VERSION "created by canmatrix"

NS_ :

BS_:

BU_: ARC ADC

BO_ 856 ARC_OD_14_15_RL: 64 ARC
 SG_ DistHeight_Obj_15_RL : 487|8@0+ (0.2,-10) [-10|41] "m" ADC
 SG_ DistHeight_Obj_14_RL : 479|8@0+ (0.2,-10) [-10|41] "m" ADC
 SG_ ARC_OD_DistX_Obj_14_RL : 7|12@0+ (0.1,-152) [-152|257.5] "m" ADC
 SG_ ARC_OD_Classification_Obj_14_RL : 98|3@0+ (1,0) [0|7] "" ADC
 SG_ ARC_OD_AabsYStd_Obj_14_RL : 111|8@0+ (0.25,0) [0|63.75] "m/s^2" ADC
 SG_ ARC_OD_ClassConf_Obj_14_RL : 119|7@0+ (1,0) [0|127] "%" ADC
 SG_ ARC_OD_ProbOfExist_Obj_14_RL : 112|7@0+ (1,0) [0|127] "%" ADC
 SG_ ARC_OD_VabsX_Obj_14_RL : 11|11@0+ (0.125,-128) [-128|127.875] "m/s" ADC
 SG_ ARC_OD_DynProp_Obj_14_RL : 130|3@0+ (1,0) [0|7] "" ADC
 SG_ ARC_OD_Length_Obj_14_RL : 136|7@0+ (0.2,0) [0|25.4] "m" ADC
 SG_ ARC_OD_MaintenanceState_Obj_0075 : 145|2@0+ (1,0) [0|3] "" ADC
 SG_ ARC_OD_Width_Obj_14_RL : 159|7@0+ (0.2,0) [0|25.4] "m" ADC
 SG_ ARC_OD_RCS_Obj_14_RL : 152|9@0+ (0.2,-51.1) [-51.1|51.1] "dBsm" ADC
 SG_ ARC_OD_Orientation_Obj_14_RL : 175|10@0+ (0.01,-5.11) [-5.11|5.12] "rad" ADC
 SG_ ARC_OD_LifeCycle_Obj_14_RL : 207|16@0+ (1,0) [0|65535] "" ADC
 SG_ ARC_OD_DistX_Obj_15_RL : 223|12@0+ (0.1,-152) [-152|257.5] "m" ADC
 SG_ ARC_OD_VabsX_Obj_15_RL : 227|11@0+ (0.125,-128) [-128|127.875] "m/s" ADC
 SG_ ARC_OD_AabsX_Obj_15_RL : 232|9@0+ (0.125,-31.875) [-31.875|32] "m/s^2" ADC
 SG_ ARC_OD_AabsX_Obj_14_RL : 16|9@0+ (0.125,-31.875) [-31.875|32] "m/s^2" ADC
 SG_ ARC_OD_DistY_Obj_15_RL : 255|12@0+ (0.0875,-179.113) [-179.113|179.2] "m" ADC
 SG_ ARC_OD_VabsY_Obj_15_RL : 259|11@0+ (0.125,-128) [-128|127.875] "m/s" ADC
 SG_ ARC_OD_AabsY_Obj_15_RL : 264|9@0+ (0.125,-31.875) [-31.875|32] "m/s^2" ADC
 SG_ ARC_OD_DistXStd_Obj_15_RL : 287|8@0+ (0.05,0) [0|12.75] "m" ADC
 SG_ ARC_OD_DistYStd_Obj_15_RL : 295|8@0+ (0.1,0) [0|25.5] "m" ADC
 SG_ ARC_OD_VabsXStd_Obj_15_RL : 303|7@0+ (0.1,0) [0|12.7] "m/s" ADC
 SG_ ARC_OD_VabsYStd_Obj_15_RL : 296|7@0+ (0.2,0) [0|25.4] "m/s" ADC
 SG_ ARC_OD_AabsXStd_Obj_15_RL : 305|7@0+ (0.25,0) [0|31.75] "m/s^2" ADC
 SG_ ARC_OD_Classification_Obj_15_RL : 314|3@0+ (1,0) [0|7] "" ADC
 SG_ ARC_OD_AabsYStd_Obj_15_RL : 327|8@0+ (0.25,0) [0|63.75] "m/s^2" ADC
 SG_ ARC_OD_ClassConf_Obj_15_RL : 335|7@0+ (1,0) [0|127] "%" ADC
 SG_ ARC_OD_DistY_Obj_14_RL : 39|12@0+ (0.0875,-179.113) [-179.113|179.2] "m" ADC
 SG_ ARC_OD_ProbOfExist_Obj_15_RL : 328|7@0+ (1,0) [0|127] "%" ADC
 SG_ ARC_OD_DynProp_Obj_15_RL : 346|3@0+ (1,0) [0|7] "" ADC
 SG_ ARC_OD_Length_Obj_15_RL : 352|7@0+ (0.2,0) [0|25.4] "m" ADC
 SG_ ARC_OD_MaintenanceState_Obj_0076 : 361|2@0+ (1,0) [0|3] "" ADC
 SG_ ARC_OD_Width_Obj_15_RL : 375|7@0+ (0.2,0) [0|25.4] "m" ADC
 SG_ ARC_OD_RCS_Obj_15_RL : 368|9@0+ (0.2,-51.1) [-51.1|51.1] "dBsm" ADC
 SG_ ARC_OD_Orientation_Obj_15_RL : 391|10@0+ (0.01,-5.11) [-5.11|5.12] "rad" ADC
 SG_ ARC_OD_LifeCycle_Obj_15_RL : 423|16@0+ (1,0) [0|65535] "" ADC
 SG_ ARC_OD_ObstacleProb_Obj_14_RL : 447|7@0+ (1,0) [0|127] "%" ADC
 SG_ ARC_OD_ObstacleProb_Obj_15_RL : 455|7@0+ (1,0) [0|127] "%" ADC
 SG_ ARC_OD_VabsY_Obj_14_RL : 43|11@0+ (0.125,-128) [-128|127.875] "m/s" ADC
 SG_ ARC_OD_ID_14_RL : 463|8@0+ (1,0) [0|255] "" ADC
 SG_ ARC_OD_ID_15_RL : 471|8@0+ (1,0) [0|255] "" ADC
 SG_ ARC_OD_MsgCounter_Obj_14_15_RL : 491|4@0+ (1,0) [0|15] "" ADC
 SG_ ARC_OD_CRC8_Obj_14_15_RL : 511|8@0+ (1,0) [0|256] "" ADC
 SG_ ARC_OD_AabsY_Obj_14_RL : 48|9@0+ (0.125,-31.875) [-31.875|32] "m/s^2" ADC
 SG_ ARC_OD_DistXStd_Obj_14_RL : 71|8@0+ (0.05,0) [0|12.75] "m" ADC
 SG_ ARC_OD_DistYStd_Obj_14_RL : 79|8@0+ (0.1,0) [0|25.5] "m" ADC
 SG_ ARC_OD_VabsXStd_Obj_14_RL : 87|7@0+ (0.1,0) [0|12.7] "m/s" ADC
 SG_ ARC_OD_VabsYStd_Obj_14_RL : 80|7@0+ (0.2,0) [0|25.4] "m/s" ADC
 SG_ ARC_OD_AabsXStd_Obj_14_RL : 89|7@0+ (0.25,0) [0|31.75] "m/s^2" ADC

BO_ 857 ARC_OD_16_17_RL: 64 ARC
 SG_ DistHeight_Obj_17_RL : 487|8@0+ (0.2,-10) [-10|41] "m" ADC
 SG_ DistHeight_Obj_16_RL : 479|8@0+ (0.2,-10) [-10|41] "m" ADC
 SG_ ARC_OD_DistX_Obj_16_RL : 7|12@0+ (0.1,-152) [-152|257.5] "m" ADC
 SG_ ARC_OD_Classification_Obj_16_RL : 98|3@0+ (1,0) [0|7] "" ADC
 SG_ ARC_OD_AabsYStd_Obj_16_RL : 111|8@0+ (0.25,0) [0|63.75] "m/s^2" ADC
 SG_ ARC_OD_ClassConf_Obj_16_RL : 119|7@0+ (1,0) [0|127] "%" ADC
 SG_ ARC_OD_ProbOfExist_Obj_16_RL : 112|7@0+ (1,0) [0|127] "%" ADC
 SG_ ARC_OD_VabsX_Obj_16_RL : 11|11@0+ (0.125,-128) [-128|127.875] "m/s" ADC
 SG_ ARC_OD_DynProp_Obj_16_RL : 130|3@0+ (1,0) [0|7] "" ADC
 SG_ ARC_OD_Length_Obj_16_RL : 136|7@0+ (0.2,0) [0|25.4] "m" ADC
 SG_ ARC_OD_MaintenanceState_Obj_0077 : 145|2@0+ (1,0) [0|3] "" ADC
 SG_ ARC_OD_Width_Obj_16_RL : 159|7@0+ (0.2,0) [0|25.4] "m" ADC
 SG_ ARC_OD_RCS_Obj_16_RL : 152|9@0+ (0.2,-51.1) [-51.1|51.1] "dBsm" ADC
 SG_ ARC_OD_Orientation_Obj_16_RL : 175|10@0+ (0.01,-5.11) [-5.11|5.12] "rad" ADC
 SG_ ARC_OD_LifeCycle_Obj_16_RL : 207|16@0+ (1,0) [0|65535] "" ADC
 SG_ ARC_OD_DistX_Obj_17_RL : 223|12@0+ (0.1,-152) [-152|257.5] "m" ADC
 SG_ ARC_OD_VabsX_Obj_17_RL : 227|11@0+ (0.125,-128) [-128|127.875] "m/s" ADC
 SG_ ARC_OD_AabsX_Obj_17_RL : 232|9@0+ (0.125,-31.875) [-31.875|32] "m/s^2" ADC
 SG_ ARC_OD_AabsX_Obj_16_RL : 16|9@0+ (0.125,-31.875) [-31.875|32] "m/s^2" ADC
 SG_ ARC_OD_DistY_Obj_17_RL : 255|12@0+ (0.0875,-179.113) [-179.113|179.2] "m" ADC
 SG_ ARC_OD_VabsY_Obj_17_RL : 259|11@0+ (0.125,-128) [-128|127.875] "m/s" ADC
 SG_ ARC_OD_AabsY_Obj_17_RL : 264|9@0+ (0.125,-31.875) [-31.875|32] "m/s^2" ADC
 SG_ ARC_OD_DistXStd_Obj_17_RL : 287|8@0+ (0.05,0) [0|12.75] "m" ADC
 SG_ ARC_OD_DistYStd_Obj_17_RL : 295|8@0+ (0.1,0) [0|25.5] "m" ADC
 SG_ ARC_OD_VabsXStd_Obj_17_RL : 303|7@0+ (0.1,0) [0|12.7] "m/s" ADC
 SG_ ARC_OD_VabsYStd_Obj_17_RL : 296|7@0+ (0.2,0) [0|25.4] "m/s" ADC
 SG_ ARC_OD_AabsXStd_Obj_17_RL : 305|7@0+ (0.25,0) [0|31.75] "m/s^2" ADC
 SG_ ARC_OD_Classification_Obj_17_RL : 314|3@0+ (1,0) [0|7] "" ADC
 SG_ ARC_OD_AabsYStd_Obj_17_RL : 327|8@0+ (0.25,0) [0|63.75] "m/s^2" ADC
 SG_ ARC_OD_ClassConf_Obj_17_RL : 335|7@0+ (1,0) [0|127] "%" ADC
 SG_ ARC_OD_DistY_Obj_16_RL : 39|12@0+ (0.0875,-179.113) [-179.113|179.2] "m" ADC
 SG_ ARC_OD_ProbOfExist_Obj_17_RL : 328|7@0+ (1,0) [0|127] "%" ADC
 SG_ ARC_OD_DynProp_Obj_17_RL : 346|3@0+ (1,0) [0|7] "" ADC
 SG_ ARC_OD_Length_Obj_17_RL : 352|7@0+ (0.2,0) [0|25.4] "m" ADC
 SG_ ARC_OD_MaintenanceState_Obj_0078 : 361|2@0+ (1,0) [0|3] "" ADC
 SG_ ARC_OD_Width_Obj_17_RL : 375|7@0+ (0.2,0) [0|25.4] "m" ADC
 SG_ ARC_OD_RCS_Obj_17_RL : 368|9@0+ (0.2,-51.1) [-51.1|51.1] "dBsm" ADC
 SG_ ARC_OD_Orientation_Obj_17_RL : 391|10@0+ (0.01,-5.11) [-5.11|5.12] "rad" ADC
 SG_ ARC_OD_LifeCycle_Obj_17_RL : 423|16@0+ (1,0) [0|65535] "" ADC
 SG_ ARC_OD_ObstacleProb_Obj_16_RL : 447|7@0+ (1,0) [0|127] "%" ADC
 SG_ ARC_OD_ObstacleProb_Obj_17_RL : 455|7@0+ (1,0) [0|127] "%" ADC
 SG_ ARC_OD_VabsY_Obj_16_RL : 43|11@0+ (0.125,-128) [-128|127.875] "m/s" ADC
 SG_ ARC_OD_ID_16_RL : 463|8@0+ (1,0) [0|255] "" ADC
 SG_ ARC_OD_ID_17_RL : 471|8@0+ (1,0) [0|255] "" ADC
 SG_ ARC_OD_MsgCounter_Obj_16_17_RL : 491|4@0+ (1,0) [0|15] "" ADC
 SG_ ARC_OD_CRC8_Obj_16_17_RL : 511|8@0+ (1,0) [0|256] "" ADC
 SG_ ARC_OD_AabsY_Obj_16_RL : 48|9@0+ (0.125,-31.875) [-31.875|32] "m/s^2" ADC
 SG_ ARC_OD_DistXStd_Obj_16_RL : 71|8@0+ (0.05,0) [0|12.75] "m" ADC
 SG_ ARC_OD_DistYStd_Obj_16_RL : 79|8@0+ (0.1,0) [0|25.5] "m" ADC
 SG_ ARC_OD_VabsXStd_Obj_16_RL : 87|7@0+ (0.1,0) [0|12.7] "m/s" ADC
 SG_ ARC_OD_VabsYStd_Obj_16_RL : 80|7@0+ (0.2,0) [0|25.4] "m/s" ADC
 SG_ ARC_OD_AabsXStd_Obj_16_RL : 89|7@0+ (0.25,0) [0|31.75] "m/s^2" ADC

BO_ 858 ARC_OD_18_19_RL: 64 ARC
 SG_ DistHeight_Obj_19_RL : 487|8@0+ (0.2,-10) [-10|41] "m" ADC
 SG_ DistHeight_Obj_18_RL : 479|8@0+ (0.2,-10) [-10|41] "m" ADC
 SG_ ARC_OD_DistX_Obj_18_RL : 7|12@0+ (0.1,-152) [-152|257.5] "m" ADC
 SG_ ARC_OD_Classification_Obj_18_RL : 98|3@0+ (1,0) [0|7] "" ADC
 SG_ ARC_OD_AabsYStd_Obj_18_RL : 111|8@0+ (0.25,0) [0|63.75] "m/s^2" ADC
 SG_ ARC_OD_ClassConf_Obj_18_RL : 119|7@0+ (1,0) [0|127] "%" ADC
 SG_ ARC_OD_ProbOfExist_Obj_18_RL : 112|7@0+ (1,0) [0|127] "%" ADC
 SG_ ARC_OD_VabsX_Obj_18_RL : 11|11@0+ (0.125,-128) [-128|127.875] "m/s" ADC
 SG_ ARC_OD_DynProp_Obj_18_RL : 130|3@0+ (1,0) [0|7] "" ADC
 SG_ ARC_OD_Length_Obj_18_RL : 136|7@0+ (0.2,0) [0|25.4] "m" ADC
 SG_ ARC_OD_MaintenanceState_Obj_0079 : 145|2@0+ (1,0) [0|3] "" ADC
 SG_ ARC_OD_Width_Obj_18_RL : 159|7@0+ (0.2,0) [0|25.4] "m" ADC
 SG_ ARC_OD_RCS_Obj_18_RL : 152|9@0+ (0.2,-51.1) [-51.1|51.1] "dBsm" ADC
 SG_ ARC_OD_Orientation_Obj_18_RL : 175|10@0+ (0.01,-5.11) [-5.11|5.12] "rad" ADC
 SG_ ARC_OD_LifeCycle_Obj_18_RL : 207|16@0+ (1,0) [0|65535] "" ADC
 SG_ ARC_OD_DistX_Obj_19_RL : 223|12@0+ (0.1,-152) [-152|257.5] "m" ADC
 SG_ ARC_OD_VabsX_Obj_19_RL : 227|11@0+ (0.125,-128) [-128|127.875] "m/s" ADC
 SG_ ARC_OD_AabsX_Obj_19_RL : 232|9@0+ (0.125,-31.875) [-31.875|32] "m/s^2" ADC
 SG_ ARC_OD_AabsX_Obj_18_RL : 16|9@0+ (0.125,-31.875) [-31.875|32] "m/s^2" ADC
 SG_ ARC_OD_DistY_Obj_19_RL : 255|12@0+ (0.0875,-179.113) [-179.113|179.2] "m" ADC
 SG_ ARC_OD_VabsY_Obj_19_RL : 259|11@0+ (0.125,-128) [-128|127.875] "m/s" ADC
 SG_ ARC_OD_AabsY_Obj_19_RL : 264|9@0+ (0.125,-31.875) [-31.875|32] "m/s^2" ADC
 SG_ ARC_OD_DistXStd_Obj_19_RL : 287|8@0+ (0.05,0) [0|12.75] "m" ADC
 SG_ ARC_OD_DistYStd_Obj_19_RL : 295|8@0+ (0.1,0) [0|25.5] "m" ADC
 SG_ ARC_OD_VabsXStd_Obj_19_RL : 303|7@0+ (0.1,0) [0|12.7] "m/s" ADC
 SG_ ARC_OD_VabsYStd_Obj_19_RL : 296|7@0+ (0.2,0) [0|25.4] "m/s" ADC
 SG_ ARC_OD_AabsXStd_Obj_19_RL : 305|7@0+ (0.25,0) [0|31.75] "m/s^2" ADC
 SG_ ARC_OD_Classification_Obj_19_RL : 314|3@0+ (1,0) [0|7] "" ADC
 SG_ ARC_OD_AabsYStd_Obj_19_RL : 327|8@0+ (0.25,0) [0|63.75] "m/s^2" ADC
 SG_ ARC_OD_ClassConf_Obj_19_RL : 335|7@0+ (1,0) [0|127] "%" ADC
 SG_ ARC_OD_DistY_Obj_18_RL : 39|12@0+ (0.0875,-179.113) [-179.113|179.2] "m" ADC
 SG_ ARC_OD_ProbOfExist_Obj_19_RL : 328|7@0+ (1,0) [0|127] "%" ADC
 SG_ ARC_OD_DynProp_Obj_19_RL : 346|3@0+ (1,0) [0|7] "" ADC
 SG_ ARC_OD_Length_Obj_19_RL : 352|7@0+ (0.2,0) [0|25.4] "m" ADC
 SG_ ARC_OD_MaintenanceState_Obj_0080 : 361|2@0+ (1,0) [0|3] "" ADC
 SG_ ARC_OD_Width_Obj_19_RL : 375|7@0+ (0.2,0) [0|25.4] "m" ADC
 SG_ ARC_OD_RCS_Obj_19_RL : 368|9@0+ (0.2,-51.1) [-51.1|51.1] "dBsm" ADC
 SG_ ARC_OD_Orientation_Obj_19_RL : 391|10@0+ (0.01,-5.11) [-5.11|5.12] "rad" ADC
 SG_ ARC_OD_LifeCycle_Obj_19_RL : 423|16@0+ (1,0) [0|65535] "" ADC
 SG_ ARC_OD_ObstacleProb_Obj_18_RL : 447|7@0+ (1,0) [0|127] "%" ADC
 SG_ ARC_OD_ObstacleProb_Obj_19_RL : 455|7@0+ (1,0) [0|127] "%" ADC
 SG_ ARC_OD_VabsY_Obj_18_RL : 43|11@0+ (0.125,-128) [-128|127.875] "m/s" ADC
 SG_ ARC_OD_ID_18_RL : 463|8@0+ (1,0) [0|255] "" ADC
 SG_ ARC_OD_ID_19_RL : 471|8@0+ (1,0) [0|255] "" ADC
 SG_ ARC_OD_MsgCounter_Obj_18_19_RL : 491|4@0+ (1,0) [0|15] "" ADC
 SG_ ARC_OD_CRC8_Obj_18_19_RL : 511|8@0+ (1,0) [0|256] "" ADC
 SG_ ARC_OD_AabsY_Obj_18_RL : 48|9@0+ (0.125,-31.875) [-31.875|32] "m/s^2" ADC
 SG_ ARC_OD_DistXStd_Obj_18_RL : 71|8@0+ (0.05,0) [0|12.75] "m" ADC
 SG_ ARC_OD_DistYStd_Obj_18_RL : 79|8@0+ (0.1,0) [0|25.5] "m" ADC
 SG_ ARC_OD_VabsXStd_Obj_18_RL : 87|7@0+ (0.1,0) [0|12.7] "m/s" ADC
 SG_ ARC_OD_VabsYStd_Obj_18_RL : 80|7@0+ (0.2,0) [0|25.4] "m/s" ADC
 SG_ ARC_OD_AabsXStd_Obj_18_RL : 89|7@0+ (0.25,0) [0|31.75] "m/s^2" ADC

BO_ 859 ARC_OD_20_21_RL: 64 ARC
 SG_ DistHeight_Obj_21_RL : 487|8@0+ (0.2,-10) [-10|41] "m" ADC
 SG_ DistHeight_Obj_20_RL : 479|8@0+ (0.2,-10) [-10|41] "m" ADC
 SG_ ARC_OD_DistX_Obj_20_RL : 7|12@0+ (0.1,-152) [-152|257.5] "m" ADC
 SG_ ARC_OD_Classification_Obj_20_RL : 98|3@0+ (1,0) [0|7] "" ADC
 SG_ ARC_OD_AabsYStd_Obj_20_RL : 111|8@0+ (0.25,0) [0|63.75] "m/s^2" ADC
 SG_ ARC_OD_ClassConf_Obj_20_RL : 119|7@0+ (1,0) [0|127] "%" ADC
 SG_ ARC_OD_ProbOfExist_Obj_20_RL : 112|7@0+ (1,0) [0|127] "%" ADC
 SG_ ARC_OD_VabsX_Obj_20_RL : 11|11@0+ (0.125,-128) [-128|127.875] "m/s" ADC
 SG_ ARC_OD_DynProp_Obj_20_RL : 130|3@0+ (1,0) [0|7] "" ADC
 SG_ ARC_OD_Length_Obj_20_RL : 136|7@0+ (0.2,0) [0|25.4] "m" ADC
 SG_ ARC_OD_MaintenanceState_Obj_0081 : 145|2@0+ (1,0) [0|3] "" ADC
 SG_ ARC_OD_Width_Obj_20_RL : 159|7@0+ (0.2,0) [0|25.4] "m" ADC
 SG_ ARC_OD_RCS_Obj_20_RL : 152|9@0+ (0.2,-51.1) [-51.1|51.1] "dBsm" ADC
 SG_ ARC_OD_Orientation_Obj_20_RL : 175|10@0+ (0.01,-5.11) [-5.11|5.12] "rad" ADC
 SG_ ARC_OD_LifeCycle_Obj_20_RL : 207|16@0+ (1,0) [0|65535] "" ADC
 SG_ ARC_OD_DistX_Obj_21_RL : 223|12@0+ (0.1,-152) [-152|257.5] "m" ADC
 SG_ ARC_OD_VabsX_Obj_21_RL : 227|11@0+ (0.125,-128) [-128|127.875] "m/s" ADC
 SG_ ARC_OD_AabsX_Obj_21_RL : 232|9@0+ (0.125,-31.875) [-31.875|32] "m/s^2" ADC
 SG_ ARC_OD_AabsX_Obj_20_RL : 16|9@0+ (0.125,-31.875) [-31.875|32] "m/s^2" ADC
 SG_ ARC_OD_DistY_Obj_21_RL : 255|12@0+ (0.0875,-179.113) [-179.113|179.2] "m" ADC
 SG_ ARC_OD_VabsY_Obj_21_RL : 259|11@0+ (0.125,-128) [-128|127.875] "m/s" ADC
 SG_ ARC_OD_AabsY_Obj_21_RL : 264|9@0+ (0.125,-31.875) [-31.875|32] "m/s^2" ADC
 SG_ ARC_OD_DistXStd_Obj_21_RL : 287|8@0+ (0.05,0) [0|12.75] "m" ADC
 SG_ ARC_OD_DistYStd_Obj_21_RL : 295|8@0+ (0.1,0) [0|25.5] "m" ADC
 SG_ ARC_OD_VabsXStd_Obj_21_RL : 303|7@0+ (0.1,0) [0|12.7] "m/s" ADC
 SG_ ARC_OD_VabsYStd_Obj_21_RL : 296|7@0+ (0.2,0) [0|25.4] "m/s" ADC
 SG_ ARC_OD_AabsXStd_Obj_21_RL : 305|7@0+ (0.25,0) [0|31.75] "m/s^2" ADC
 SG_ ARC_OD_Classification_Obj_21_RL : 314|3@0+ (1,0) [0|7] "" ADC
 SG_ ARC_OD_AabsYStd_Obj_21_RL : 327|8@0+ (0.25,0) [0|63.75] "m/s^2" ADC
 SG_ ARC_OD_ClassConf_Obj_21_RL : 335|7@0+ (1,0) [0|127] "%" ADC
 SG_ ARC_OD_DistY_Obj_20_RL : 39|12@0+ (0.0875,-179.113) [-179.113|179.2] "m" ADC
 SG_ ARC_OD_ProbOfExist_Obj_21_RL : 328|7@0+ (1,0) [0|127] "%" ADC
 SG_ ARC_OD_DynProp_Obj_21_RL : 346|3@0+ (1,0) [0|7] "" ADC
 SG_ ARC_OD_Length_Obj_21_RL : 352|7@0+ (0.2,0) [0|25.4] "m" ADC
 SG_ ARC_OD_MaintenanceState_Obj_0082 : 361|2@0+ (1,0) [0|3] "" ADC
 SG_ ARC_OD_Width_Obj_21_RL : 375|7@0+ (0.2,0) [0|25.4] "m" ADC
 SG_ ARC_OD_RCS_Obj_21_RL : 368|9@0+ (0.2,-51.1) [-51.1|51.1] "dBsm" ADC
 SG_ ARC_OD_Orientation_Obj_21_RL : 391|10@0+ (0.01,-5.11) [-5.11|5.12] "rad" ADC
 SG_ ARC_OD_LifeCycle_Obj_21_RL : 423|16@0+ (1,0) [0|65535] "" ADC
 SG_ ARC_OD_ObstacleProb_Obj_20_RL : 447|7@0+ (1,0) [0|127] "%" ADC
 SG_ ARC_OD_ObstacleProb_Obj_21_RL : 455|7@0+ (1,0) [0|127] "%" ADC
 SG_ ARC_OD_VabsY_Obj_20_RL : 43|11@0+ (0.125,-128) [-128|127.875] "m/s" ADC
 SG_ ARC_OD_ID_20_RL : 463|8@0+ (1,0) [0|255] "" ADC
 SG_ ARC_OD_ID_21_RL : 471|8@0+ (1,0) [0|255] "" ADC
 SG_ ARC_OD_MsgCounter_Obj_20_21_RL : 491|4@0+ (1,0) [0|15] "" ADC
 SG_ ARC_OD_CRC8_Obj_20_21_RL : 511|8@0+ (1,0) [0|256] "" ADC
 SG_ ARC_OD_AabsY_Obj_20_RL : 48|9@0+ (0.125,-31.875) [-31.875|32] "m/s^2" ADC
 SG_ ARC_OD_DistXStd_Obj_20_RL : 71|8@0+ (0.05,0) [0|12.75] "m" ADC
 SG_ ARC_OD_DistYStd_Obj_20_RL : 79|8@0+ (0.1,0) [0|25.5] "m" ADC
 SG_ ARC_OD_VabsXStd_Obj_20_RL : 87|7@0+ (0.1,0) [0|12.7] "m/s" ADC
 SG_ ARC_OD_VabsYStd_Obj_20_RL : 80|7@0+ (0.2,0) [0|25.4] "m/s" ADC
 SG_ ARC_OD_AabsXStd_Obj_20_RL : 89|7@0+ (0.25,0) [0|31.75] "m/s^2" ADC

BO_ 860 ARC_OD_22_23_RL: 64 ARC
 SG_ DistHeight_Obj_23_RL : 487|8@0+ (0.2,-10) [-10|41] "m" ADC
 SG_ DistHeight_Obj_22_RL : 479|8@0+ (0.2,-10) [-10|41] "m" ADC
 SG_ ARC_OD_DistX_Obj_22_RL : 7|12@0+ (0.1,-152) [-152|257.5] "m" ADC
 SG_ ARC_OD_Classification_Obj_22_RL : 98|3@0+ (1,0) [0|7] "" ADC
 SG_ ARC_OD_AabsYStd_Obj_22_RL : 111|8@0+ (0.25,0) [0|63.75] "m/s^2" ADC
 SG_ ARC_OD_ClassConf_Obj_22_RL : 119|7@0+ (1,0) [0|127] "%" ADC
 SG_ ARC_OD_ProbOfExist_Obj_22_RL : 112|7@0+ (1,0) [0|127] "%" ADC
 SG_ ARC_OD_VabsX_Obj_22_RL : 11|11@0+ (0.125,-128) [-128|127.875] "m/s" ADC
 SG_ ARC_OD_DynProp_Obj_22_RL : 130|3@0+ (1,0) [0|7] "" ADC
 SG_ ARC_OD_Length_Obj_22_RL : 136|7@0+ (0.2,0) [0|25.4] "m" ADC
 SG_ ARC_OD_MaintenanceState_Obj_0083 : 145|2@0+ (1,0) [0|3] "" ADC
 SG_ ARC_OD_Width_Obj_22_RL : 159|7@0+ (0.2,0) [0|25.4] "m" ADC
 SG_ ARC_OD_RCS_Obj_22_RL : 152|9@0+ (0.2,-51.1) [-51.1|51.1] "dBsm" ADC
 SG_ ARC_OD_Orientation_Obj_22_RL : 175|10@0+ (0.01,-5.11) [-5.11|5.12] "rad" ADC
 SG_ ARC_OD_LifeCycle_Obj_22_RL : 207|16@0+ (1,0) [0|65535] "" ADC
 SG_ ARC_OD_DistX_Obj_23_RL : 223|12@0+ (0.1,-152) [-152|257.5] "m" ADC
 SG_ ARC_OD_VabsX_Obj_23_RL : 227|11@0+ (0.125,-128) [-128|127.875] "m/s" ADC
 SG_ ARC_OD_AabsX_Obj_23_RL : 232|9@0+ (0.125,-31.875) [-31.875|32] "m/s^2" ADC
 SG_ ARC_OD_AabsX_Obj_22_RL : 16|9@0+ (0.125,-31.875) [-31.875|32] "m/s^2" ADC
 SG_ ARC_OD_DistY_Obj_23_RL : 255|12@0+ (0.0875,-179.113) [-179.113|179.2] "m" ADC
 SG_ ARC_OD_VabsY_Obj_23_RL : 259|11@0+ (0.125,-128) [-128|127.875] "m/s" ADC
 SG_ ARC_OD_AabsY_Obj_23_RL : 264|9@0+ (0.125,-31.875) [-31.875|32] "m/s^2" ADC
 SG_ ARC_OD_DistXStd_Obj_23_RL : 287|8@0+ (0.05,0) [0|12.75] "m" ADC
 SG_ ARC_OD_DistYStd_Obj_23_RL : 295|8@0+ (0.1,0) [0|25.5] "m" ADC
 SG_ ARC_OD_VabsXStd_Obj_23_RL : 303|7@0+ (0.1,0) [0|12.7] "m/s" ADC
 SG_ ARC_OD_VabsYStd_Obj_23_RL : 296|7@0+ (0.2,0) [0|25.4] "m/s" ADC
 SG_ ARC_OD_AabsXStd_Obj_23_RL : 305|7@0+ (0.25,0) [0|31.75] "m/s^2" ADC
 SG_ ARC_OD_Classification_Obj_23_RL : 314|3@0+ (1,0) [0|7] "" ADC
 SG_ ARC_OD_AabsYStd_Obj_23_RL : 327|8@0+ (0.25,0) [0|63.75] "m/s^2" ADC
 SG_ ARC_OD_ClassConf_Obj_23_RL : 335|7@0+ (1,0) [0|127] "%" ADC
 SG_ ARC_OD_DistY_Obj_22_RL : 39|12@0+ (0.0875,-179.113) [-179.113|179.2] "m" ADC
 SG_ ARC_OD_ProbOfExist_Obj_23_RL : 328|7@0+ (1,0) [0|127] "%" ADC
 SG_ ARC_OD_DynProp_Obj_23_RL : 346|3@0+ (1,0) [0|7] "" ADC
 SG_ ARC_OD_Length_Obj_23_RL : 352|7@0+ (0.2,0) [0|25.4] "m" ADC
 SG_ ARC_OD_MaintenanceState_Obj_0084 : 361|2@0+ (1,0) [0|3] "" ADC
 SG_ ARC_OD_Width_Obj_23_RL : 375|7@0+ (0.2,0) [0|25.4] "m" ADC
 SG_ ARC_OD_RCS_Obj_23_RL : 368|9@0+ (0.2,-51.1) [-51.1|51.1] "dBsm" ADC
 SG_ ARC_OD_Orientation_Obj_23_RL : 391|10@0+ (0.01,-5.11) [-5.11|5.12] "rad" ADC
 SG_ ARC_OD_LifeCycle_Obj_23_RL : 423|16@0+ (1,0) [0|65535] "" ADC
 SG_ ARC_OD_ObstacleProb_Obj_22_RL : 447|7@0+ (1,0) [0|127] "%" ADC
 SG_ ARC_OD_ObstacleProb_Obj_23_RL : 455|7@0+ (1,0) [0|127] "%" ADC
 SG_ ARC_OD_VabsY_Obj_22_RL : 43|11@0+ (0.125,-128) [-128|127.875] "m/s" ADC
 SG_ ARC_OD_ID_22_RL : 463|8@0+ (1,0) [0|255] "" ADC
 SG_ ARC_OD_ID_23_RL : 471|8@0+ (1,0) [0|255] "" ADC
 SG_ ARC_OD_MsgCounter_Obj_22_23_RL : 491|4@0+ (1,0) [0|15] "" ADC
 SG_ ARC_OD_CRC8_Obj_22_23_RL : 511|8@0+ (1,0) [0|256] "" ADC
 SG_ ARC_OD_AabsY_Obj_22_RL : 48|9@0+ (0.125,-31.875) [-31.875|32] "m/s^2" ADC
 SG_ ARC_OD_DistXStd_Obj_22_RL : 71|8@0+ (0.05,0) [0|12.75] "m" ADC
 SG_ ARC_OD_DistYStd_Obj_22_RL : 79|8@0+ (0.1,0) [0|25.5] "m" ADC
 SG_ ARC_OD_VabsXStd_Obj_22_RL : 87|7@0+ (0.1,0) [0|12.7] "m/s" ADC
 SG_ ARC_OD_VabsYStd_Obj_22_RL : 80|7@0+ (0.2,0) [0|25.4] "m/s" ADC
 SG_ ARC_OD_AabsXStd_Obj_22_RL : 89|7@0+ (0.25,0) [0|31.75] "m/s^2" ADC

BO_ 861 ARC_OD_24_25_RL: 64 ARC
 SG_ DistHeight_Obj_25_RL : 487|8@0+ (0.2,-10) [-10|41] "m" ADC
 SG_ DistHeight_Obj_24_RL : 479|8@0+ (0.2,-10) [-10|41] "m" ADC
 SG_ ARC_OD_DistX_Obj_24_RL : 7|12@0+ (0.1,-152) [-152|257.5] "m" ADC
 SG_ ARC_OD_Classification_Obj_24_RL : 98|3@0+ (1,0) [0|7] "" ADC
 SG_ ARC_OD_AabsYStd_Obj_24_RL : 111|8@0+ (0.25,0) [0|63.75] "m/s^2" ADC
 SG_ ARC_OD_ClassConf_Obj_24_RL : 119|7@0+ (1,0) [0|127] "%" ADC
 SG_ ARC_OD_ProbOfExist_Obj_24_RL : 112|7@0+ (1,0) [0|127] "%" ADC
 SG_ ARC_OD_VabsX_Obj_24_RL : 11|11@0+ (0.125,-128) [-128|127.875] "m/s" ADC
 SG_ ARC_OD_DynProp_Obj_24_RL : 130|3@0+ (1,0) [0|7] "" ADC
 SG_ ARC_OD_Length_Obj_24_RL : 136|7@0+ (0.2,0) [0|25.4] "m" ADC
 SG_ ARC_OD_MaintenanceState_Obj_0085 : 145|2@0+ (1,0) [0|3] "" ADC
 SG_ ARC_OD_Width_Obj_24_RL : 159|7@0+ (0.2,0) [0|25.4] "m" ADC
 SG_ ARC_OD_RCS_Obj_24_RL : 152|9@0+ (0.2,-51.1) [-51.1|51.1] "dBsm" ADC
 SG_ ARC_OD_Orientation_Obj_24_RL : 175|10@0+ (0.01,-5.11) [-5.11|5.12] "rad" ADC
 SG_ ARC_OD_LifeCycle_Obj_24_RL : 207|16@0+ (1,0) [0|65535] "" ADC
 SG_ ARC_OD_DistX_Obj_25_RL : 223|12@0+ (0.1,-152) [-152|257.5] "m" ADC
 SG_ ARC_OD_VabsX_Obj_25_RL : 227|11@0+ (0.125,-128) [-128|127.875] "m/s" ADC
 SG_ ARC_OD_AabsX_Obj_25_RL : 232|9@0+ (0.125,-31.875) [-31.875|32] "m/s^2" ADC
 SG_ ARC_OD_AabsX_Obj_24_RL : 16|9@0+ (0.125,-31.875) [-31.875|32] "m/s^2" ADC
 SG_ ARC_OD_DistY_Obj_25_RL : 255|12@0+ (0.0875,-179.113) [-179.113|179.2] "m" ADC
 SG_ ARC_OD_VabsY_Obj_25_RL : 259|11@0+ (0.125,-128) [-128|127.875] "m/s" ADC
 SG_ ARC_OD_AabsY_Obj_25_RL : 264|9@0+ (0.125,-31.875) [-31.875|32] "m/s^2" ADC
 SG_ ARC_OD_DistXStd_Obj_25_RL : 287|8@0+ (0.05,0) [0|12.75] "m" ADC
 SG_ ARC_OD_DistYStd_Obj_25_RL : 295|8@0+ (0.1,0) [0|25.5] "m" ADC
 SG_ ARC_OD_VabsXStd_Obj_25_RL : 303|7@0+ (0.1,0) [0|12.7] "m/s" ADC
 SG_ ARC_OD_VabsYStd_Obj_25_RL : 296|7@0+ (0.2,0) [0|25.4] "m/s" ADC
 SG_ ARC_OD_AabsXStd_Obj_25_RL : 305|7@0+ (0.25,0) [0|31.75] "m/s^2" ADC
 SG_ ARC_OD_Classification_Obj_25_RL : 314|3@0+ (1,0) [0|7] "" ADC
 SG_ ARC_OD_AabsYStd_Obj_25_RL : 327|8@0+ (0.25,0) [0|63.75] "m/s^2" ADC
 SG_ ARC_OD_ClassConf_Obj_25_RL : 335|7@0+ (1,0) [0|127] "%" ADC
 SG_ ARC_OD_DistY_Obj_24_RL : 39|12@0+ (0.0875,-179.113) [-179.113|179.2] "m" ADC
 SG_ ARC_OD_ProbOfExist_Obj_25_RL : 328|7@0+ (1,0) [0|127] "%" ADC
 SG_ ARC_OD_DynProp_Obj_25_RL : 346|3@0+ (1,0) [0|7] "" ADC
 SG_ ARC_OD_Length_Obj_25_RL : 352|7@0+ (0.2,0) [0|25.4] "m" ADC
 SG_ ARC_OD_MaintenanceState_Obj_0086 : 361|2@0+ (1,0) [0|3] "" ADC
 SG_ ARC_OD_Width_Obj_25_RL : 375|7@0+ (0.2,0) [0|25.4] "m" ADC
 SG_ ARC_OD_RCS_Obj_25_RL : 368|9@0+ (0.2,-51.1) [-51.1|51.1] "dBsm" ADC
 SG_ ARC_OD_Orientation_Obj_25_RL : 391|10@0+ (0.01,-5.11) [-5.11|5.12] "rad" ADC
 SG_ ARC_OD_LifeCycle_Obj_25_RL : 423|16@0+ (1,0) [0|65535] "" ADC
 SG_ ARC_OD_ObstacleProb_Obj_24_RL : 447|7@0+ (1,0) [0|127] "%" ADC
 SG_ ARC_OD_ObstacleProb_Obj_25_RL : 455|7@0+ (1,0) [0|127] "%" ADC
 SG_ ARC_OD_VabsY_Obj_24_RL : 43|11@0+ (0.125,-128) [-128|127.875] "m/s" ADC
 SG_ ARC_OD_ID_24_RL : 463|8@0+ (1,0) [0|255] "" ADC
 SG_ ARC_OD_ID_25_RL : 471|8@0+ (1,0) [0|255] "" ADC
 SG_ ARC_OD_MsgCounter_Obj_24_25_RL : 491|4@0+ (1,0) [0|15] "" ADC
 SG_ ARC_OD_CRC8_Obj_24_25_RL : 511|8@0+ (1,0) [0|256] "" ADC
 SG_ ARC_OD_AabsY_Obj_24_RL : 48|9@0+ (0.125,-31.875) [-31.875|32] "m/s^2" ADC
 SG_ ARC_OD_DistXStd_Obj_24_RL : 71|8@0+ (0.05,0) [0|12.75] "m" ADC
 SG_ ARC_OD_DistYStd_Obj_24_RL : 79|8@0+ (0.1,0) [0|25.5] "m" ADC
 SG_ ARC_OD_VabsXStd_Obj_24_RL : 87|7@0+ (0.1,0) [0|12.7] "m/s" ADC
 SG_ ARC_OD_VabsYStd_Obj_24_RL : 80|7@0+ (0.2,0) [0|25.4] "m/s" ADC
 SG_ ARC_OD_AabsXStd_Obj_24_RL : 89|7@0+ (0.25,0) [0|31.75] "m/s^2" ADC

BO_ 862 ARC_OD_26_27_RL: 64 ARC
 SG_ DistHeight_Obj_27_RL : 487|8@0+ (0.2,-10) [-10|41] "m" ADC
 SG_ DistHeight_Obj_26_RL : 479|8@0+ (0.2,-10) [-10|41] "m" ADC
 SG_ ARC_OD_DistX_Obj_26_RL : 7|12@0+ (0.1,-152) [-152|257.5] "m" ADC
 SG_ ARC_OD_Classification_Obj_26_RL : 98|3@0+ (1,0) [0|7] "" ADC
 SG_ ARC_OD_AabsYStd_Obj_26_RL : 111|8@0+ (0.25,0) [0|63.75] "m/s^2" ADC
 SG_ ARC_OD_ClassConf_Obj_26_RL : 119|7@0+ (1,0) [0|127] "%" ADC
 SG_ ARC_OD_ProbOfExist_Obj_26_RL : 112|7@0+ (1,0) [0|127] "%" ADC
 SG_ ARC_OD_VabsX_Obj_26_RL : 11|11@0+ (0.125,-128) [-128|127.875] "m/s" ADC
 SG_ ARC_OD_DynProp_Obj_26_RL : 130|3@0+ (1,0) [0|7] "" ADC
 SG_ ARC_OD_Length_Obj_26_RL : 136|7@0+ (0.2,0) [0|25.4] "m" ADC
 SG_ ARC_OD_MaintenanceState_Obj_0087 : 145|2@0+ (1,0) [0|3] "" ADC
 SG_ ARC_OD_Width_Obj_26_RL : 159|7@0+ (0.2,0) [0|25.4] "m" ADC
 SG_ ARC_OD_RCS_Obj_26_RL : 152|9@0+ (0.2,-51.1) [-51.1|51.1] "dBsm" ADC
 SG_ ARC_OD_Orientation_Obj_26_RL : 175|10@0+ (0.01,-5.11) [-5.11|5.12] "rad" ADC
 SG_ ARC_OD_LifeCycle_Obj_26_RL : 207|16@0+ (1,0) [0|65535] "" ADC
 SG_ ARC_OD_DistX_Obj_27_RL : 223|12@0+ (0.1,-152) [-152|257.5] "m" ADC
 SG_ ARC_OD_VabsX_Obj_27_RL : 227|11@0+ (0.125,-128) [-128|127.875] "m/s" ADC
 SG_ ARC_OD_AabsX_Obj_27_RL : 232|9@0+ (0.125,-31.875) [-31.875|32] "m/s^2" ADC
 SG_ ARC_OD_AabsX_Obj_26_RL : 16|9@0+ (0.125,-31.875) [-31.875|32] "m/s^2" ADC
 SG_ ARC_OD_DistY_Obj_27_RL : 255|12@0+ (0.0875,-179.113) [-179.113|179.2] "m" ADC
 SG_ ARC_OD_VabsY_Obj_27_RL : 259|11@0+ (0.125,-128) [-128|127.875] "m/s" ADC
 SG_ ARC_OD_AabsY_Obj_27_RL : 264|9@0+ (0.125,-31.875) [-31.875|32] "m/s^2" ADC
 SG_ ARC_OD_DistXStd_Obj_27_RL : 287|8@0+ (0.05,0) [0|12.75] "m" ADC
 SG_ ARC_OD_DistYStd_Obj_27_RL : 295|8@0+ (0.1,0) [0|25.5] "m" ADC
 SG_ ARC_OD_VabsXStd_Obj_27_RL : 303|7@0+ (0.1,0) [0|12.7] "m/s" ADC
 SG_ ARC_OD_VabsYStd_Obj_27_RL : 296|7@0+ (0.2,0) [0|25.4] "m/s" ADC
 SG_ ARC_OD_AabsXStd_Obj_27_RL : 305|7@0+ (0.25,0) [0|31.75] "m/s^2" ADC
 SG_ ARC_OD_Classification_Obj_27_RL : 314|3@0+ (1,0) [0|7] "" ADC
 SG_ ARC_OD_AabsYStd_Obj_27_RL : 327|8@0+ (0.25,0) [0|63.75] "m/s^2" ADC
 SG_ ARC_OD_ClassConf_Obj_27_RL : 335|7@0+ (1,0) [0|127] "%" ADC
 SG_ ARC_OD_DistY_Obj_26_RL : 39|12@0+ (0.0875,-179.113) [-179.113|179.2] "m" ADC
 SG_ ARC_OD_ProbOfExist_Obj_27_RL : 328|7@0+ (1,0) [0|127] "%" ADC
 SG_ ARC_OD_DynProp_Obj_27_RL : 346|3@0+ (1,0) [0|7] "" ADC
 SG_ ARC_OD_Length_Obj_27_RL : 352|7@0+ (0.2,0) [0|25.4] "m" ADC
 SG_ ARC_OD_MaintenanceState_Obj_0088 : 361|2@0+ (1,0) [0|3] "" ADC
 SG_ ARC_OD_Width_Obj_27_RL : 375|7@0+ (0.2,0) [0|25.4] "m" ADC
 SG_ ARC_OD_RCS_Obj_27_RL : 368|9@0+ (0.2,-51.1) [-51.1|51.1] "dBsm" ADC
 SG_ ARC_OD_Orientation_Obj_27_RL : 391|10@0+ (0.01,-5.11) [-5.11|5.12] "rad" ADC
 SG_ ARC_OD_LifeCycle_Obj_27_RL : 423|16@0+ (1,0) [0|65535] "" ADC
 SG_ ARC_OD_ObstacleProb_Obj_26_RL : 447|7@0+ (1,0) [0|127] "%" ADC
 SG_ ARC_OD_ObstacleProb_Obj_27_RL : 455|7@0+ (1,0) [0|127] "%" ADC
 SG_ ARC_OD_VabsY_Obj_26_RL : 43|11@0+ (0.125,-128) [-128|127.875] "m/s" ADC
 SG_ ARC_OD_ID_26_RL : 463|8@0+ (1,0) [0|255] "" ADC
 SG_ ARC_OD_ID_27_RL : 471|8@0+ (1,0) [0|255] "" ADC
 SG_ ARC_OD_MsgCounter_Obj_26_27_RL : 491|4@0+ (1,0) [0|15] "" ADC
 SG_ ARC_OD_CRC8_Obj_26_27_RL : 511|8@0+ (1,0) [0|256] "" ADC
 SG_ ARC_OD_AabsY_Obj_26_RL : 48|9@0+ (0.125,-31.875) [-31.875|32] "m/s^2" ADC
 SG_ ARC_OD_DistXStd_Obj_26_RL : 71|8@0+ (0.05,0) [0|12.75] "m" ADC
 SG_ ARC_OD_DistYStd_Obj_26_RL : 79|8@0+ (0.1,0) [0|25.5] "m" ADC
 SG_ ARC_OD_VabsXStd_Obj_26_RL : 87|7@0+ (0.1,0) [0|12.7] "m/s" ADC
 SG_ ARC_OD_VabsYStd_Obj_26_RL : 80|7@0+ (0.2,0) [0|25.4] "m/s" ADC
 SG_ ARC_OD_AabsXStd_Obj_26_RL : 89|7@0+ (0.25,0) [0|31.75] "m/s^2" ADC

BO_ 863 ARC_OD_28_29_RL: 64 ARC
 SG_ DistHeight_Obj_29_RL : 487|8@0+ (0.2,-10) [-10|41] "m" ADC
 SG_ DistHeight_Obj_28_RL : 479|8@0+ (0.2,-10) [-10|41] "m" ADC
 SG_ ARC_OD_DistX_Obj_28_RL : 7|12@0+ (0.1,-152) [-152|257.5] "m" ADC
 SG_ ARC_OD_Classification_Obj_28_RL : 98|3@0+ (1,0) [0|7] "" ADC
 SG_ ARC_OD_AabsYStd_Obj_28_RL : 111|8@0+ (0.25,0) [0|63.75] "m/s^2" ADC
 SG_ ARC_OD_ClassConf_Obj_28_RL : 119|7@0+ (1,0) [0|127] "%" ADC
 SG_ ARC_OD_ProbOfExist_Obj_28_RL : 112|7@0+ (1,0) [0|127] "%" ADC
 SG_ ARC_OD_VabsX_Obj_28_RL : 11|11@0+ (0.125,-128) [-128|127.875] "m/s" ADC
 SG_ ARC_OD_DynProp_Obj_28_RL : 130|3@0+ (1,0) [0|7] "" ADC
 SG_ ARC_OD_Length_Obj_28_RL : 136|7@0+ (0.2,0) [0|25.4] "m" ADC
 SG_ ARC_OD_MaintenanceState_Obj_0089 : 145|2@0+ (1,0) [0|3] "" ADC
 SG_ ARC_OD_Width_Obj_28_RL : 159|7@0+ (0.2,0) [0|25.4] "m" ADC
 SG_ ARC_OD_RCS_Obj_28_RL : 152|9@0+ (0.2,-51.1) [-51.1|51.1] "dBsm" ADC
 SG_ ARC_OD_Orientation_Obj_28_RL : 175|10@0+ (0.01,-5.11) [-5.11|5.12] "rad" ADC
 SG_ ARC_OD_LifeCycle_Obj_28_RL : 207|16@0+ (1,0) [0|65535] "" ADC
 SG_ ARC_OD_DistX_Obj_29_RL : 223|12@0+ (0.1,-152) [-152|257.5] "m" ADC
 SG_ ARC_OD_VabsX_Obj_29_RL : 227|11@0+ (0.125,-128) [-128|127.875] "m/s" ADC
 SG_ ARC_OD_AabsX_Obj_29_RL : 232|9@0+ (0.125,-31.875) [-31.875|32] "m/s^2" ADC
 SG_ ARC_OD_AabsX_Obj_28_RL : 16|9@0+ (0.125,-31.875) [-31.875|32] "m/s^2" ADC
 SG_ ARC_OD_DistY_Obj_29_RL : 255|12@0+ (0.0875,-179.113) [-179.113|179.2] "m" ADC
 SG_ ARC_OD_VabsY_Obj_29_RL : 259|11@0+ (0.125,-128) [-128|127.875] "m/s" ADC
 SG_ ARC_OD_AabsY_Obj_29_RL : 264|9@0+ (0.125,-31.875) [-31.875|32] "m/s^2" ADC
 SG_ ARC_OD_DistXStd_Obj_29_RL : 287|8@0+ (0.05,0) [0|12.75] "m" ADC
 SG_ ARC_OD_DistYStd_Obj_29_RL : 295|8@0+ (0.1,0) [0|25.5] "m" ADC
 SG_ ARC_OD_VabsXStd_Obj_29_RL : 303|7@0+ (0.1,0) [0|12.7] "m/s" ADC
 SG_ ARC_OD_VabsYStd_Obj_29_RL : 296|7@0+ (0.2,0) [0|25.4] "m/s" ADC
 SG_ ARC_OD_AabsXStd_Obj_29_RL : 305|7@0+ (0.25,0) [0|31.75] "m/s^2" ADC
 SG_ ARC_OD_Classification_Obj_29_RL : 314|3@0+ (1,0) [0|7] "" ADC
 SG_ ARC_OD_AabsYStd_Obj_29_RL : 327|8@0+ (0.25,0) [0|63.75] "m/s^2" ADC
 SG_ ARC_OD_ClassConf_Obj_29_RL : 335|7@0+ (1,0) [0|127] "%" ADC
 SG_ ARC_OD_DistY_Obj_28_RL : 39|12@0+ (0.0875,-179.113) [-179.113|179.2] "m" ADC
 SG_ ARC_OD_ProbOfExist_Obj_29_RL : 328|7@0+ (1,0) [0|127] "%" ADC
 SG_ ARC_OD_DynProp_Obj_29_RL : 346|3@0+ (1,0) [0|7] "" ADC
 SG_ ARC_OD_Length_Obj_29_RL : 352|7@0+ (0.2,0) [0|25.4] "m" ADC
 SG_ ARC_OD_MaintenanceState_Obj_0090 : 361|2@0+ (1,0) [0|3] "" ADC
 SG_ ARC_OD_Width_Obj_29_RL : 375|7@0+ (0.2,0) [0|25.4] "m" ADC
 SG_ ARC_OD_RCS_Obj_29_RL : 368|9@0+ (0.2,-51.1) [-51.1|51.1] "dBsm" ADC
 SG_ ARC_OD_Orientation_Obj_29_RL : 391|10@0+ (0.01,-5.11) [-5.11|5.12] "rad" ADC
 SG_ ARC_OD_LifeCycle_Obj_29_RL : 423|16@0+ (1,0) [0|65535] "" ADC
 SG_ ARC_OD_ObstacleProb_Obj_28_RL : 447|7@0+ (1,0) [0|127] "%" ADC
 SG_ ARC_OD_ObstacleProb_Obj_29_RL : 455|7@0+ (1,0) [0|127] "%" ADC
 SG_ ARC_OD_VabsY_Obj_28_RL : 43|11@0+ (0.125,-128) [-128|127.875] "m/s" ADC
 SG_ ARC_OD_ID_28_RL : 463|8@0+ (1,0) [0|255] "" ADC
 SG_ ARC_OD_ID_29_RL : 471|8@0+ (1,0) [0|255] "" ADC
 SG_ ARC_OD_MsgCounter_Obj_28_29_RL : 491|4@0+ (1,0) [0|15] "" ADC
 SG_ ARC_OD_CRC8_Obj_28_29_RL : 511|8@0+ (1,0) [0|256] "" ADC
 SG_ ARC_OD_AabsY_Obj_28_RL : 48|9@0+ (0.125,-31.875) [-31.875|32] "m/s^2" ADC
 SG_ ARC_OD_DistXStd_Obj_28_RL : 71|8@0+ (0.05,0) [0|12.75] "m" ADC
 SG_ ARC_OD_DistYStd_Obj_28_RL : 79|8@0+ (0.1,0) [0|25.5] "m" ADC
 SG_ ARC_OD_VabsXStd_Obj_28_RL : 87|7@0+ (0.1,0) [0|12.7] "m/s" ADC
 SG_ ARC_OD_VabsYStd_Obj_28_RL : 80|7@0+ (0.2,0) [0|25.4] "m/s" ADC
 SG_ ARC_OD_AabsXStd_Obj_28_RL : 89|7@0+ (0.25,0) [0|31.75] "m/s^2" ADC

BO_ 864 ARC_OD_30_31_RL: 64 ARC
 SG_ DistHeight_Obj_31_RL : 487|8@0+ (0.2,-10) [-10|41] "m" ADC
 SG_ DistHeight_Obj_30_RL : 479|8@0+ (0.2,-10) [-10|41] "m" ADC
 SG_ ARC_OD_DistX_Obj_30_RL : 7|12@0+ (0.1,-152) [-152|257.5] "m" ADC
 SG_ ARC_OD_Classification_Obj_30_RL : 98|3@0+ (1,0) [0|7] "" ADC
 SG_ ARC_OD_AabsYStd_Obj_30_RL : 111|8@0+ (0.25,0) [0|63.75] "m/s^2" ADC
 SG_ ARC_OD_ClassConf_Obj_30_RL : 119|7@0+ (1,0) [0|127] "%" ADC
 SG_ ARC_OD_ProbOfExist_Obj_30_RL : 112|7@0+ (1,0) [0|127] "%" ADC
 SG_ ARC_OD_VabsX_Obj_30_RL : 11|11@0+ (0.125,-128) [-128|127.875] "m/s" ADC
 SG_ ARC_OD_DynProp_Obj_30_RL : 130|3@0+ (1,0) [0|7] "" ADC
 SG_ ARC_OD_Length_Obj_30_RL : 136|7@0+ (0.2,0) [0|25.4] "m" ADC
 SG_ ARC_OD_MaintenanceState_Obj_0091 : 145|2@0+ (1,0) [0|3] "" ADC
 SG_ ARC_OD_Width_Obj_30_RL : 159|7@0+ (0.2,0) [0|25.4] "m" ADC
 SG_ ARC_OD_RCS_Obj_30_RL : 152|9@0+ (0.2,-51.1) [-51.1|51.1] "dBsm" ADC
 SG_ ARC_OD_Orientation_Obj_30_RL : 175|10@0+ (0.01,-5.11) [-5.11|5.12] "rad" ADC
 SG_ ARC_OD_LifeCycle_Obj_30_RL : 207|16@0+ (1,0) [0|65535] "" ADC
 SG_ ARC_OD_DistX_Obj_31_RL : 223|12@0+ (0.1,-152) [-152|257.5] "m" ADC
 SG_ ARC_OD_VabsX_Obj_31_RL : 227|11@0+ (0.125,-128) [-128|127.875] "m/s" ADC
 SG_ ARC_OD_AabsX_Obj_31_RL : 232|9@0+ (0.125,-31.875) [-31.875|32] "m/s^2" ADC
 SG_ ARC_OD_AabsX_Obj_30_RL : 16|9@0+ (0.125,-31.875) [-31.875|32] "m/s^2" ADC
 SG_ ARC_OD_DistY_Obj_31_RL : 255|12@0+ (0.0875,-179.113) [-179.113|179.2] "m" ADC
 SG_ ARC_OD_VabsY_Obj_31_RL : 259|11@0+ (0.125,-128) [-128|127.875] "m/s" ADC
 SG_ ARC_OD_AabsY_Obj_31_RL : 264|9@0+ (0.125,-31.875) [-31.875|32] "m/s^2" ADC
 SG_ ARC_OD_DistXStd_Obj_31_RL : 287|8@0+ (0.05,0) [0|12.75] "m" ADC
 SG_ ARC_OD_DistYStd_Obj_31_RL : 295|8@0+ (0.1,0) [0|25.5] "m" ADC
 SG_ ARC_OD_VabsXStd_Obj_31_RL : 303|7@0+ (0.1,0) [0|12.7] "m/s" ADC
 SG_ ARC_OD_VabsYStd_Obj_31_RL : 296|7@0+ (0.2,0) [0|25.4] "m/s" ADC
 SG_ ARC_OD_AabsXStd_Obj_31_RL : 305|7@0+ (0.25,0) [0|31.75] "m/s^2" ADC
 SG_ ARC_OD_Classification_Obj_31_RL : 314|3@0+ (1,0) [0|7] "" ADC
 SG_ ARC_OD_AabsYStd_Obj_31_RL : 327|8@0+ (0.25,0) [0|63.75] "m/s^2" ADC
 SG_ ARC_OD_ClassConf_Obj_31_RL : 335|7@0+ (1,0) [0|127] "%" ADC
 SG_ ARC_OD_DistY_Obj_30_RL : 39|12@0+ (0.0875,-179.113) [-179.113|179.2] "m" ADC
 SG_ ARC_OD_ProbOfExist_Obj_31_RL : 328|7@0+ (1,0) [0|127] "%" ADC
 SG_ ARC_OD_DynProp_Obj_31_RL : 346|3@0+ (1,0) [0|7] "" ADC
 SG_ ARC_OD_Length_Obj_31_RL : 352|7@0+ (0.2,0) [0|25.4] "m" ADC
 SG_ ARC_OD_MaintenanceState_Obj_0092 : 361|2@0+ (1,0) [0|3] "" ADC
 SG_ ARC_OD_Width_Obj_31_RL : 375|7@0+ (0.2,0) [0|25.4] "m" ADC
 SG_ ARC_OD_RCS_Obj_31_RL : 368|9@0+ (0.2,-51.1) [-51.1|51.1] "dBsm" ADC
 SG_ ARC_OD_Orientation_Obj_31_RL : 391|10@0+ (0.01,-5.11) [-5.11|5.12] "rad" ADC
 SG_ ARC_OD_LifeCycle_Obj_31_RL : 423|16@0+ (1,0) [0|65535] "" ADC
 SG_ ARC_OD_ObstacleProb_Obj_30_RL : 447|7@0+ (1,0) [0|127] "%" ADC
 SG_ ARC_OD_ObstacleProb_Obj_31_RL : 455|7@0+ (1,0) [0|127] "%" ADC
 SG_ ARC_OD_VabsY_Obj_30_RL : 43|11@0+ (0.125,-128) [-128|127.875] "m/s" ADC
 SG_ ARC_OD_ID_30_RL : 463|8@0+ (1,0) [0|255] "" ADC
 SG_ ARC_OD_ID_31_RL : 471|8@0+ (1,0) [0|255] "" ADC
 SG_ ARC_OD_MsgCounter_Obj_30_31_RL : 491|4@0+ (1,0) [0|15] "" ADC
 SG_ ARC_OD_CRC8_Obj_30_31_RL : 511|8@0+ (1,0) [0|256] "" ADC
 SG_ ARC_OD_AabsY_Obj_30_RL : 48|9@0+ (0.125,-31.875) [-31.875|32] "m/s^2" ADC
 SG_ ARC_OD_DistXStd_Obj_30_RL : 71|8@0+ (0.05,0) [0|12.75] "m" ADC
 SG_ ARC_OD_DistYStd_Obj_30_RL : 79|8@0+ (0.1,0) [0|25.5] "m" ADC
 SG_ ARC_OD_VabsXStd_Obj_30_RL : 87|7@0+ (0.1,0) [0|12.7] "m/s" ADC
 SG_ ARC_OD_VabsYStd_Obj_30_RL : 80|7@0+ (0.2,0) [0|25.4] "m/s" ADC
 SG_ ARC_OD_AabsXStd_Obj_30_RL : 89|7@0+ (0.25,0) [0|31.75] "m/s^2" ADC

BO_ 865 ARC_OD_32_33_RL: 64 ARC
 SG_ DistHeight_Obj_33_RL : 487|8@0+ (0.2,-10) [-10|41] "m" ADC
 SG_ DistHeight_Obj_32_RL : 479|8@0+ (0.2,-10) [-10|41] "m" ADC
 SG_ ARC_OD_DistX_Obj_32_RL : 7|12@0+ (0.1,-152) [-152|257.5] "m" ADC
 SG_ ARC_OD_Classification_Obj_32_RL : 98|3@0+ (1,0) [0|7] "" ADC
 SG_ ARC_OD_AabsYStd_Obj_32_RL : 111|8@0+ (0.25,0) [0|63.75] "m/s^2" ADC
 SG_ ARC_OD_ClassConf_Obj_32_RL : 119|7@0+ (1,0) [0|127] "%" ADC
 SG_ ARC_OD_ProbOfExist_Obj_32_RL : 112|7@0+ (1,0) [0|127] "%" ADC
 SG_ ARC_OD_VabsX_Obj_32_RL : 11|11@0+ (0.125,-128) [-128|127.875] "m/s" ADC
 SG_ ARC_OD_DynProp_Obj_32_RL : 130|3@0+ (1,0) [0|7] "" ADC
 SG_ ARC_OD_Length_Obj_32_RL : 136|7@0+ (0.2,0) [0|25.4] "m" ADC
 SG_ ARC_OD_MaintenanceState_Obj_0093 : 145|2@0+ (1,0) [0|3] "" ADC
 SG_ ARC_OD_Width_Obj_32_RL : 159|7@0+ (0.2,0) [0|25.4] "m" ADC
 SG_ ARC_OD_RCS_Obj_32_RL : 152|9@0+ (0.2,-51.1) [-51.1|51.1] "dBsm" ADC
 SG_ ARC_OD_Orientation_Obj_32_RL : 175|10@0+ (0.01,-5.11) [-5.11|5.12] "rad" ADC
 SG_ ARC_OD_LifeCycle_Obj_32_RL : 207|16@0+ (1,0) [0|65535] "" ADC
 SG_ ARC_OD_DistX_Obj_33_RL : 223|12@0+ (0.1,-152) [-152|257.5] "m" ADC
 SG_ ARC_OD_VabsX_Obj_33_RL : 227|11@0+ (0.125,-128) [-128|127.875] "m/s" ADC
 SG_ ARC_OD_AabsX_Obj_33_RL : 232|9@0+ (0.125,-31.875) [-31.875|32] "m/s^2" ADC
 SG_ ARC_OD_AabsX_Obj_32_RL : 16|9@0+ (0.125,-31.875) [-31.875|32] "m/s^2" ADC
 SG_ ARC_OD_DistY_Obj_33_RL : 255|12@0+ (0.0875,-179.113) [-179.113|179.2] "m" ADC
 SG_ ARC_OD_VabsY_Obj_33_RL : 259|11@0+ (0.125,-128) [-128|127.875] "m/s" ADC
 SG_ ARC_OD_AabsY_Obj_33_RL : 264|9@0+ (0.125,-31.875) [-31.875|32] "m/s^2" ADC
 SG_ ARC_OD_DistXStd_Obj_33_RL : 287|8@0+ (0.05,0) [0|12.75] "m" ADC
 SG_ ARC_OD_DistYStd_Obj_33_RL : 295|8@0+ (0.1,0) [0|25.5] "m" ADC
 SG_ ARC_OD_VabsXStd_Obj_33_RL : 303|7@0+ (0.1,0) [0|12.7] "m/s" ADC
 SG_ ARC_OD_VabsYStd_Obj_33_RL : 296|7@0+ (0.2,0) [0|25.4] "m/s" ADC
 SG_ ARC_OD_AabsXStd_Obj_33_RL : 305|7@0+ (0.25,0) [0|31.75] "m/s^2" ADC
 SG_ ARC_OD_Classification_Obj_33_RL : 314|3@0+ (1,0) [0|7] "" ADC
 SG_ ARC_OD_AabsYStd_Obj_33_RL : 327|8@0+ (0.25,0) [0|63.75] "m/s^2" ADC
 SG_ ARC_OD_ClassConf_Obj_33_RL : 335|7@0+ (1,0) [0|127] "%" ADC
 SG_ ARC_OD_DistY_Obj_32_RL : 39|12@0+ (0.0875,-179.113) [-179.113|179.2] "m" ADC
 SG_ ARC_OD_ProbOfExist_Obj_33_RL : 328|7@0+ (1,0) [0|127] "%" ADC
 SG_ ARC_OD_DynProp_Obj_33_RL : 346|3@0+ (1,0) [0|7] "" ADC
 SG_ ARC_OD_Length_Obj_33_RL : 352|7@0+ (0.2,0) [0|25.4] "m" ADC
 SG_ ARC_OD_MaintenanceState_Obj_0094 : 361|2@0+ (1,0) [0|3] "" ADC
 SG_ ARC_OD_Width_Obj_33_RL : 375|7@0+ (0.2,0) [0|25.4] "m" ADC
 SG_ ARC_OD_RCS_Obj_33_RL : 368|9@0+ (0.2,-51.1) [-51.1|51.1] "dBsm" ADC
 SG_ ARC_OD_Orientation_Obj_33_RL : 391|10@0+ (0.01,-5.11) [-5.11|5.12] "rad" ADC
 SG_ ARC_OD_LifeCycle_Obj_33_RL : 423|16@0+ (1,0) [0|65535] "" ADC
 SG_ ARC_OD_ObstacleProb_Obj_32_RL : 447|7@0+ (1,0) [0|127] "%" ADC
 SG_ ARC_OD_ObstacleProb_Obj_33_RL : 455|7@0+ (1,0) [0|127] "%" ADC
 SG_ ARC_OD_VabsY_Obj_32_RL : 43|11@0+ (0.125,-128) [-128|127.875] "m/s" ADC
 SG_ ARC_OD_ID_32_RL : 463|8@0+ (1,0) [0|255] "" ADC
 SG_ ARC_OD_ID_33_RL : 471|8@0+ (1,0) [0|255] "" ADC
 SG_ ARC_OD_MsgCounter_Obj_32_33_RL : 491|4@0+ (1,0) [0|15] "" ADC
 SG_ ARC_OD_CRC8_Obj_32_33_RL : 511|8@0+ (1,0) [0|256] "" ADC
 SG_ ARC_OD_AabsY_Obj_32_RL : 48|9@0+ (0.125,-31.875) [-31.875|32] "m/s^2" ADC
 SG_ ARC_OD_DistXStd_Obj_32_RL : 71|8@0+ (0.05,0) [0|12.75] "m" ADC
 SG_ ARC_OD_DistYStd_Obj_32_RL : 79|8@0+ (0.1,0) [0|25.5] "m" ADC
 SG_ ARC_OD_VabsXStd_Obj_32_RL : 87|7@0+ (0.1,0) [0|12.7] "m/s" ADC
 SG_ ARC_OD_VabsYStd_Obj_32_RL : 80|7@0+ (0.2,0) [0|25.4] "m/s" ADC
 SG_ ARC_OD_AabsXStd_Obj_32_RL : 89|7@0+ (0.25,0) [0|31.75] "m/s^2" ADC

BO_ 866 ARC_OD_34_35_RL: 64 ARC
 SG_ DistHeight_Obj_35_RL : 487|8@0+ (0.2,-10) [-10|41] "m" ADC
 SG_ DistHeight_Obj_34_RL : 479|8@0+ (0.2,-10) [-10|41] "m" ADC
 SG_ ARC_OD_DistX_Obj_34_RL : 7|12@0+ (0.1,-152) [-152|257.5] "m" ADC
 SG_ ARC_OD_Classification_Obj_34_RL : 98|3@0+ (1,0) [0|7] "" ADC
 SG_ ARC_OD_AabsYStd_Obj_34_RL : 111|8@0+ (0.25,0) [0|63.75] "m/s^2" ADC
 SG_ ARC_OD_ClassConf_Obj_34_RL : 119|7@0+ (1,0) [0|127] "%" ADC
 SG_ ARC_OD_ProbOfExist_Obj_34_RL : 112|7@0+ (1,0) [0|127] "%" ADC
 SG_ ARC_OD_VabsX_Obj_34_RL : 11|11@0+ (0.125,-128) [-128|127.875] "m/s" ADC
 SG_ ARC_OD_DynProp_Obj_34_RL : 130|3@0+ (1,0) [0|7] "" ADC
 SG_ ARC_OD_Length_Obj_34_RL : 136|7@0+ (0.2,0) [0|25.4] "m" ADC
 SG_ ARC_OD_MaintenanceState_Obj_0095 : 145|2@0+ (1,0) [0|3] "" ADC
 SG_ ARC_OD_Width_Obj_34_RL : 159|7@0+ (0.2,0) [0|25.4] "m" ADC
 SG_ ARC_OD_RCS_Obj_34_RL : 152|9@0+ (0.2,-51.1) [-51.1|51.1] "dBsm" ADC
 SG_ ARC_OD_Orientation_Obj_34_RL : 175|10@0+ (0.01,-5.11) [-5.11|5.12] "rad" ADC
 SG_ ARC_OD_LifeCycle_Obj_34_RL : 207|16@0+ (1,0) [0|65535] "" ADC
 SG_ ARC_OD_DistX_Obj_35_RL : 223|12@0+ (0.1,-152) [-152|257.5] "m" ADC
 SG_ ARC_OD_VabsX_Obj_35_RL : 227|11@0+ (0.125,-128) [-128|127.875] "m/s" ADC
 SG_ ARC_OD_AabsX_Obj_35_RL : 232|9@0+ (0.125,-31.875) [-31.875|32] "m/s^2" ADC
 SG_ ARC_OD_AabsX_Obj_34_RL : 16|9@0+ (0.125,-31.875) [-31.875|32] "m/s^2" ADC
 SG_ ARC_OD_DistY_Obj_35_RL : 255|12@0+ (0.0875,-179.113) [-179.113|179.2] "m" ADC
 SG_ ARC_OD_VabsY_Obj_35_RL : 259|11@0+ (0.125,-128) [-128|127.875] "m/s" ADC
 SG_ ARC_OD_AabsY_Obj_35_RL : 264|9@0+ (0.125,-31.875) [-31.875|32] "m/s^2" ADC
 SG_ ARC_OD_DistXStd_Obj_35_RL : 287|8@0+ (0.05,0) [0|12.75] "m" ADC
 SG_ ARC_OD_DistYStd_Obj_35_RL : 295|8@0+ (0.1,0) [0|25.5] "m" ADC
 SG_ ARC_OD_VabsXStd_Obj_35_RL : 303|7@0+ (0.1,0) [0|12.7] "m/s" ADC
 SG_ ARC_OD_VabsYStd_Obj_35_RL : 296|7@0+ (0.2,0) [0|25.4] "m/s" ADC
 SG_ ARC_OD_AabsXStd_Obj_35_RL : 305|7@0+ (0.25,0) [0|31.75] "m/s^2" ADC
 SG_ ARC_OD_Classification_Obj_35_RL : 314|3@0+ (1,0) [0|7] "" ADC
 SG_ ARC_OD_AabsYStd_Obj_35_RL : 327|8@0+ (0.25,0) [0|63.75] "m/s^2" ADC
 SG_ ARC_OD_ClassConf_Obj_35_RL : 335|7@0+ (1,0) [0|127] "%" ADC
 SG_ ARC_OD_DistY_Obj_34_RL : 39|12@0+ (0.0875,-179.113) [-179.113|179.2] "m" ADC
 SG_ ARC_OD_ProbOfExist_Obj_35_RL : 328|7@0+ (1,0) [0|127] "%" ADC
 SG_ ARC_OD_DynProp_Obj_35_RL : 346|3@0+ (1,0) [0|7] "" ADC
 SG_ ARC_OD_Length_Obj_35_RL : 352|7@0+ (0.2,0) [0|25.4] "m" ADC
 SG_ ARC_OD_MaintenanceState_Obj_0096 : 361|2@0+ (1,0) [0|3] "" ADC
 SG_ ARC_OD_Width_Obj_35_RL : 375|7@0+ (0.2,0) [0|25.4] "m" ADC
 SG_ ARC_OD_RCS_Obj_35_RL : 368|9@0+ (0.2,-51.1) [-51.1|51.1] "dBsm" ADC
 SG_ ARC_OD_Orientation_Obj_35_RL : 391|10@0+ (0.01,-5.11) [-5.11|5.12] "rad" ADC
 SG_ ARC_OD_LifeCycle_Obj_35_RL : 423|16@0+ (1,0) [0|65535] "" ADC
 SG_ ARC_OD_ObstacleProb_Obj_34_RL : 447|7@0+ (1,0) [0|127] "%" ADC
 SG_ ARC_OD_ObstacleProb_Obj_35_RL : 455|7@0+ (1,0) [0|127] "%" ADC
 SG_ ARC_OD_VabsY_Obj_34_RL : 43|11@0+ (0.125,-128) [-128|127.875] "m/s" ADC
 SG_ ARC_OD_ID_34_RL : 463|8@0+ (1,0) [0|255] "" ADC
 SG_ ARC_OD_ID_35_RL : 471|8@0+ (1,0) [0|255] "" ADC
 SG_ ARC_OD_MsgCounter_Obj_34_35_RL : 491|4@0+ (1,0) [0|15] "" ADC
 SG_ ARC_OD_CRC8_Obj_34_35_RL : 511|8@0+ (1,0) [0|256] "" ADC
 SG_ ARC_OD_AabsY_Obj_34_RL : 48|9@0+ (0.125,-31.875) [-31.875|32] "m/s^2" ADC
 SG_ ARC_OD_DistXStd_Obj_34_RL : 71|8@0+ (0.05,0) [0|12.75] "m" ADC
 SG_ ARC_OD_DistYStd_Obj_34_RL : 79|8@0+ (0.1,0) [0|25.5] "m" ADC
 SG_ ARC_OD_VabsXStd_Obj_34_RL : 87|7@0+ (0.1,0) [0|12.7] "m/s" ADC
 SG_ ARC_OD_VabsYStd_Obj_34_RL : 80|7@0+ (0.2,0) [0|25.4] "m/s" ADC
 SG_ ARC_OD_AabsXStd_Obj_34_RL : 89|7@0+ (0.25,0) [0|31.75] "m/s^2" ADC

BO_ 867 ARC_OD_36_37_RL: 64 ARC
 SG_ DistHeight_Obj_37_RL : 487|8@0+ (0.2,-10) [-10|41] "m" ADC
 SG_ DistHeight_Obj_36_RL : 479|8@0+ (0.2,-10) [-10|41] "m" ADC
 SG_ ARC_OD_DistX_Obj_36_RL : 7|12@0+ (0.1,-152) [-152|257.5] "m" ADC
 SG_ ARC_OD_Classification_Obj_36_RL : 98|3@0+ (1,0) [0|7] "" ADC
 SG_ ARC_OD_AabsYStd_Obj_36_RL : 111|8@0+ (0.25,0) [0|63.75] "m/s^2" ADC
 SG_ ARC_OD_ClassConf_Obj_36_RL : 119|7@0+ (1,0) [0|127] "%" ADC
 SG_ ARC_OD_ProbOfExist_Obj_36_RL : 112|7@0+ (1,0) [0|127] "%" ADC
 SG_ ARC_OD_VabsX_Obj_36_RL : 11|11@0+ (0.125,-128) [-128|127.875] "m/s" ADC
 SG_ ARC_OD_DynProp_Obj_36_RL : 130|3@0+ (1,0) [0|7] "" ADC
 SG_ ARC_OD_Length_Obj_36_RL : 136|7@0+ (0.2,0) [0|25.4] "m" ADC
 SG_ ARC_OD_MaintenanceState_Obj_0097 : 145|2@0+ (1,0) [0|3] "" ADC
 SG_ ARC_OD_Width_Obj_36_RL : 159|7@0+ (0.2,0) [0|25.4] "m" ADC
 SG_ ARC_OD_RCS_Obj_36_RL : 152|9@0+ (0.2,-51.1) [-51.1|51.1] "dBsm" ADC
 SG_ ARC_OD_Orientation_Obj_36_RL : 175|10@0+ (0.01,-5.11) [-5.11|5.12] "rad" ADC
 SG_ ARC_OD_LifeCycle_Obj_36_RL : 207|16@0+ (1,0) [0|65535] "" ADC
 SG_ ARC_OD_DistX_Obj_37_RL : 223|12@0+ (0.1,-152) [-152|257.5] "m" ADC
 SG_ ARC_OD_VabsX_Obj_37_RL : 227|11@0+ (0.125,-128) [-128|127.875] "m/s" ADC
 SG_ ARC_OD_AabsX_Obj_37_RL : 232|9@0+ (0.125,-31.875) [-31.875|32] "m/s^2" ADC
 SG_ ARC_OD_AabsX_Obj_36_RL : 16|9@0+ (0.125,-31.875) [-31.875|32] "m/s^2" ADC
 SG_ ARC_OD_DistY_Obj_37_RL : 255|12@0+ (0.0875,-179.113) [-179.113|179.2] "m" ADC
 SG_ ARC_OD_VabsY_Obj_37_RL : 259|11@0+ (0.125,-128) [-128|127.875] "m/s" ADC
 SG_ ARC_OD_AabsY_Obj_37_RL : 264|9@0+ (0.125,-31.875) [-31.875|32] "m/s^2" ADC
 SG_ ARC_OD_DistXStd_Obj_37_RL : 287|8@0+ (0.05,0) [0|12.75] "m" ADC
 SG_ ARC_OD_DistYStd_Obj_37_RL : 295|8@0+ (0.1,0) [0|25.5] "m" ADC
 SG_ ARC_OD_VabsXStd_Obj_37_RL : 303|7@0+ (0.1,0) [0|12.7] "m/s" ADC
 SG_ ARC_OD_VabsYStd_Obj_37_RL : 296|7@0+ (0.2,0) [0|25.4] "m/s" ADC
 SG_ ARC_OD_AabsXStd_Obj_37_RL : 305|7@0+ (0.25,0) [0|31.75] "m/s^2" ADC
 SG_ ARC_OD_Classification_Obj_37_RL : 314|3@0+ (1,0) [0|7] "" ADC
 SG_ ARC_OD_AabsYStd_Obj_37_RL : 327|8@0+ (0.25,0) [0|63.75] "m/s^2" ADC
 SG_ ARC_OD_ClassConf_Obj_37_RL : 335|7@0+ (1,0) [0|127] "%" ADC
 SG_ ARC_OD_DistY_Obj_36_RL : 39|12@0+ (0.0875,-179.113) [-179.113|179.2] "m" ADC
 SG_ ARC_OD_ProbOfExist_Obj_37_RL : 328|7@0+ (1,0) [0|127] "%" ADC
 SG_ ARC_OD_DynProp_Obj_37_RL : 346|3@0+ (1,0) [0|7] "" ADC
 SG_ ARC_OD_Length_Obj_37_RL : 352|7@0+ (0.2,0) [0|25.4] "m" ADC
 SG_ ARC_OD_MaintenanceState_Obj_0098 : 361|2@0+ (1,0) [0|3] "" ADC
 SG_ ARC_OD_Width_Obj_37_RL : 375|7@0+ (0.2,0) [0|25.4] "m" ADC
 SG_ ARC_OD_RCS_Obj_37_RL : 368|9@0+ (0.2,-51.1) [-51.1|51.1] "dBsm" ADC
 SG_ ARC_OD_Orientation_Obj_37_RL : 391|10@0+ (0.01,-5.11) [-5.11|5.12] "rad" ADC
 SG_ ARC_OD_LifeCycle_Obj_37_RL : 423|16@0+ (1,0) [0|65535] "" ADC
 SG_ ARC_OD_ObstacleProb_Obj_36_RL : 447|7@0+ (1,0) [0|127] "%" ADC
 SG_ ARC_OD_ObstacleProb_Obj_37_RL : 455|7@0+ (1,0) [0|127] "%" ADC
 SG_ ARC_OD_VabsY_Obj_36_RL : 43|11@0+ (0.125,-128) [-128|127.875] "m/s" ADC
 SG_ ARC_OD_ID_36_RL : 463|8@0+ (1,0) [0|255] "" ADC
 SG_ ARC_OD_ID_37_RL : 471|8@0+ (1,0) [0|255] "" ADC
 SG_ ARC_OD_MsgCounter_Obj_36_37_RL : 491|4@0+ (1,0) [0|15] "" ADC
 SG_ ARC_OD_CRC8_Obj_36_37_RL : 511|8@0+ (1,0) [0|256] "" ADC
 SG_ ARC_OD_AabsY_Obj_36_RL : 48|9@0+ (0.125,-31.875) [-31.875|32] "m/s^2" ADC
 SG_ ARC_OD_DistXStd_Obj_36_RL : 71|8@0+ (0.05,0) [0|12.75] "m" ADC
 SG_ ARC_OD_DistYStd_Obj_36_RL : 79|8@0+ (0.1,0) [0|25.5] "m" ADC
 SG_ ARC_OD_VabsXStd_Obj_36_RL : 87|7@0+ (0.1,0) [0|12.7] "m/s" ADC
 SG_ ARC_OD_VabsYStd_Obj_36_RL : 80|7@0+ (0.2,0) [0|25.4] "m/s" ADC
 SG_ ARC_OD_AabsXStd_Obj_36_RL : 89|7@0+ (0.25,0) [0|31.75] "m/s^2" ADC

BO_ 868 ARC_OD_38_39_RL: 64 ARC
 SG_ DistHeight_Obj_39_RL : 487|8@0+ (0.2,-10) [-10|41] "m" ADC
 SG_ DistHeight_Obj_38_RL : 479|8@0+ (0.2,-10) [-10|41] "m" ADC
 SG_ ARC_OD_DistX_Obj_38_RL : 7|12@0+ (0.1,-152) [-152|257.5] "m" ADC
 SG_ ARC_OD_Classification_Obj_38_RL : 98|3@0+ (1,0) [0|7] "" ADC
 SG_ ARC_OD_AabsYStd_Obj_38_RL : 111|8@0+ (0.25,0) [0|63.75] "m/s^2" ADC
 SG_ ARC_OD_ClassConf_Obj_38_RL : 119|7@0+ (1,0) [0|127] "%" ADC
 SG_ ARC_OD_ProbOfExist_Obj_38_RL : 112|7@0+ (1,0) [0|127] "%" ADC
 SG_ ARC_OD_VabsX_Obj_38_RL : 11|11@0+ (0.125,-128) [-128|127.875] "m/s" ADC
 SG_ ARC_OD_DynProp_Obj_38_RL : 130|3@0+ (1,0) [0|7] "" ADC
 SG_ ARC_OD_Length_Obj_38_RL : 136|7@0+ (0.2,0) [0|25.4] "m" ADC
 SG_ ARC_OD_MaintenanceState_Obj_0099 : 145|2@0+ (1,0) [0|3] "" ADC
 SG_ ARC_OD_Width_Obj_38_RL : 159|7@0+ (0.2,0) [0|25.4] "m" ADC
 SG_ ARC_OD_RCS_Obj_38_RL : 152|9@0+ (0.2,-51.1) [-51.1|51.1] "dBsm" ADC
 SG_ ARC_OD_Orientation_Obj_38_RL : 175|10@0+ (0.01,-5.11) [-5.11|5.12] "rad" ADC
 SG_ ARC_OD_LifeCycle_Obj_38_RL : 207|16@0+ (1,0) [0|65535] "" ADC
 SG_ ARC_OD_DistX_Obj_39_RL : 223|12@0+ (0.1,-152) [-152|257.5] "m" ADC
 SG_ ARC_OD_VabsX_Obj_39_RL : 227|11@0+ (0.125,-128) [-128|127.875] "m/s" ADC
 SG_ ARC_OD_AabsX_Obj_39_RL : 232|9@0+ (0.125,-31.875) [-31.875|32] "m/s^2" ADC
 SG_ ARC_OD_AabsX_Obj_38_RL : 16|9@0+ (0.125,-31.875) [-31.875|32] "m/s^2" ADC
 SG_ ARC_OD_DistY_Obj_39_RL : 255|12@0+ (0.0875,-179.113) [-179.113|179.2] "m" ADC
 SG_ ARC_OD_VabsY_Obj_39_RL : 259|11@0+ (0.125,-128) [-128|127.875] "m/s" ADC
 SG_ ARC_OD_AabsY_Obj_39_RL : 264|9@0+ (0.125,-31.875) [-31.875|32] "m/s^2" ADC
 SG_ ARC_OD_DistXStd_Obj_39_RL : 287|8@0+ (0.05,0) [0|12.75] "m" ADC
 SG_ ARC_OD_DistYStd_Obj_39_RL : 295|8@0+ (0.1,0) [0|25.5] "m" ADC
 SG_ ARC_OD_VabsXStd_Obj_39_RL : 303|7@0+ (0.1,0) [0|12.7] "m/s" ADC
 SG_ ARC_OD_VabsYStd_Obj_39_RL : 296|7@0+ (0.2,0) [0|25.4] "m/s" ADC
 SG_ ARC_OD_AabsXStd_Obj_39_RL : 305|7@0+ (0.25,0) [0|31.75] "m/s^2" ADC
 SG_ ARC_OD_Classification_Obj_39_RL : 314|3@0+ (1,0) [0|7] "" ADC
 SG_ ARC_OD_AabsYStd_Obj_39_RL : 327|8@0+ (0.25,0) [0|63.75] "m/s^2" ADC
 SG_ ARC_OD_ClassConf_Obj_39_RL : 335|7@0+ (1,0) [0|127] "%" ADC
 SG_ ARC_OD_DistY_Obj_38_RL : 39|12@0+ (0.0875,-179.113) [-179.113|179.2] "m" ADC
 SG_ ARC_OD_ProbOfExist_Obj_39_RL : 328|7@0+ (1,0) [0|127] "%" ADC
 SG_ ARC_OD_DynProp_Obj_39_RL : 346|3@0+ (1,0) [0|7] "" ADC
 SG_ ARC_OD_Length_Obj_39_RL : 352|7@0+ (0.2,0) [0|25.4] "m" ADC
 SG_ ARC_OD_MaintenanceState_Obj_0100 : 361|2@0+ (1,0) [0|3] "" ADC
 SG_ ARC_OD_Width_Obj_39_RL : 375|7@0+ (0.2,0) [0|25.4] "m" ADC
 SG_ ARC_OD_RCS_Obj_39_RL : 368|9@0+ (0.2,-51.1) [-51.1|51.1] "dBsm" ADC
 SG_ ARC_OD_Orientation_Obj_39_RL : 391|10@0+ (0.01,-5.11) [-5.11|5.12] "rad" ADC
 SG_ ARC_OD_LifeCycle_Obj_39_RL : 423|16@0+ (1,0) [0|65535] "" ADC
 SG_ ARC_OD_ObstacleProb_Obj_38_RL : 447|7@0+ (1,0) [0|127] "%" ADC
 SG_ ARC_OD_ObstacleProb_Obj_39_RL : 455|7@0+ (1,0) [0|127] "%" ADC
 SG_ ARC_OD_VabsY_Obj_38_RL : 43|11@0+ (0.125,-128) [-128|127.875] "m/s" ADC
 SG_ ARC_OD_ID_38_RL : 463|8@0+ (1,0) [0|255] "" ADC
 SG_ ARC_OD_ID_39_RL : 471|8@0+ (1,0) [0|255] "" ADC
 SG_ ARC_OD_MsgCounter_Obj_38_39_RL : 491|4@0+ (1,0) [0|15] "" ADC
 SG_ ARC_OD_CRC8_Obj_38_39_RL : 511|8@0+ (1,0) [0|256] "" ADC
 SG_ ARC_OD_AabsY_Obj_38_RL : 48|9@0+ (0.125,-31.875) [-31.875|32] "m/s^2" ADC
 SG_ ARC_OD_DistXStd_Obj_38_RL : 71|8@0+ (0.05,0) [0|12.75] "m" ADC
 SG_ ARC_OD_DistYStd_Obj_38_RL : 79|8@0+ (0.1,0) [0|25.5] "m" ADC
 SG_ ARC_OD_VabsXStd_Obj_38_RL : 87|7@0+ (0.1,0) [0|12.7] "m/s" ADC
 SG_ ARC_OD_VabsYStd_Obj_38_RL : 80|7@0+ (0.2,0) [0|25.4] "m/s" ADC
 SG_ ARC_OD_AabsXStd_Obj_38_RL : 89|7@0+ (0.25,0) [0|31.75] "m/s^2" ADC

BO_ 869 ARC_OD_40_41_RL: 64 ARC
 SG_ DistHeight_Obj_41_RL : 487|8@0+ (0.2,-10) [-10|41] "m" ADC
 SG_ DistHeight_Obj_40_RL : 479|8@0+ (0.2,-10) [-10|41] "m" ADC
 SG_ ARC_OD_DistX_Obj_40_RL : 7|12@0+ (0.1,-152) [-152|257.5] "m" ADC
 SG_ ARC_OD_Classification_Obj_40_RL : 98|3@0+ (1,0) [0|7] "" ADC
 SG_ ARC_OD_AabsYStd_Obj_40_RL : 111|8@0+ (0.25,0) [0|63.75] "m/s^2" ADC
 SG_ ARC_OD_ClassConf_Obj_40_RL : 119|7@0+ (1,0) [0|127] "%" ADC
 SG_ ARC_OD_ProbOfExist_Obj_40_RL : 112|7@0+ (1,0) [0|127] "%" ADC
 SG_ ARC_OD_VabsX_Obj_40_RL : 11|11@0+ (0.125,-128) [-128|127.875] "m/s" ADC
 SG_ ARC_OD_DynProp_Obj_40_RL : 130|3@0+ (1,0) [0|7] "" ADC
 SG_ ARC_OD_Length_Obj_40_RL : 136|7@0+ (0.2,0) [0|25.4] "m" ADC
 SG_ ARC_OD_MaintenanceState_Obj_0101 : 145|2@0+ (1,0) [0|3] "" ADC
 SG_ ARC_OD_Width_Obj_40_RL : 159|7@0+ (0.2,0) [0|25.4] "m" ADC
 SG_ ARC_OD_RCS_Obj_40_RL : 152|9@0+ (0.2,-51.1) [-51.1|51.1] "dBsm" ADC
 SG_ ARC_OD_Orientation_Obj_40_RL : 175|10@0+ (0.01,-5.11) [-5.11|5.12] "rad" ADC
 SG_ ARC_OD_LifeCycle_Obj_40_RL : 207|16@0+ (1,0) [0|65535] "" ADC
 SG_ ARC_OD_DistX_Obj_41_RL : 223|12@0+ (0.1,-152) [-152|257.5] "m" ADC
 SG_ ARC_OD_VabsX_Obj_41_RL : 227|11@0+ (0.125,-128) [-128|127.875] "m/s" ADC
 SG_ ARC_OD_AabsX_Obj_41_RL : 232|9@0+ (0.125,-31.875) [-31.875|32] "m/s^2" ADC
 SG_ ARC_OD_AabsX_Obj_40_RL : 16|9@0+ (0.125,-31.875) [-31.875|32] "m/s^2" ADC
 SG_ ARC_OD_DistY_Obj_41_RL : 255|12@0+ (0.0875,-179.113) [-179.113|179.2] "m" ADC
 SG_ ARC_OD_VabsY_Obj_41_RL : 259|11@0+ (0.125,-128) [-128|127.875] "m/s" ADC
 SG_ ARC_OD_AabsY_Obj_41_RL : 264|9@0+ (0.125,-31.875) [-31.875|32] "m/s^2" ADC
 SG_ ARC_OD_DistXStd_Obj_41_RL : 287|8@0+ (0.05,0) [0|12.75] "m" ADC
 SG_ ARC_OD_DistYStd_Obj_41_RL : 295|8@0+ (0.1,0) [0|25.5] "m" ADC
 SG_ ARC_OD_VabsXStd_Obj_41_RL : 303|7@0+ (0.1,0) [0|12.7] "m/s" ADC
 SG_ ARC_OD_VabsYStd_Obj_41_RL : 296|7@0+ (0.2,0) [0|25.4] "m/s" ADC
 SG_ ARC_OD_AabsXStd_Obj_41_RL : 305|7@0+ (0.25,0) [0|31.75] "m/s^2" ADC
 SG_ ARC_OD_Classification_Obj_41_RL : 314|3@0+ (1,0) [0|7] "" ADC
 SG_ ARC_OD_AabsYStd_Obj_41_RL : 327|8@0+ (0.25,0) [0|63.75] "m/s^2" ADC
 SG_ ARC_OD_ClassConf_Obj_41_RL : 335|7@0+ (1,0) [0|127] "%" ADC
 SG_ ARC_OD_DistY_Obj_40_RL : 39|12@0+ (0.0875,-179.113) [-179.113|179.2] "m" ADC
 SG_ ARC_OD_ProbOfExist_Obj_41_RL : 328|7@0+ (1,0) [0|127] "%" ADC
 SG_ ARC_OD_DynProp_Obj_41_RL : 346|3@0+ (1,0) [0|7] "" ADC
 SG_ ARC_OD_Length_Obj_41_RL : 352|7@0+ (0.2,0) [0|25.4] "m" ADC
 SG_ ARC_OD_MaintenanceState_Obj_0102 : 361|2@0+ (1,0) [0|3] "" ADC
 SG_ ARC_OD_Width_Obj_41_RL : 375|7@0+ (0.2,0) [0|25.4] "m" ADC
 SG_ ARC_OD_RCS_Obj_41_RL : 368|9@0+ (0.2,-51.1) [-51.1|51.1] "dBsm" ADC
 SG_ ARC_OD_Orientation_Obj_41_RL : 391|10@0+ (0.01,-5.11) [-5.11|5.12] "rad" ADC
 SG_ ARC_OD_LifeCycle_Obj_41_RL : 423|16@0+ (1,0) [0|65535] "" ADC
 SG_ ARC_OD_ObstacleProb_Obj_40_RL : 447|7@0+ (1,0) [0|127] "%" ADC
 SG_ ARC_OD_ObstacleProb_Obj_41_RL : 455|7@0+ (1,0) [0|127] "%" ADC
 SG_ ARC_OD_VabsY_Obj_40_RL : 43|11@0+ (0.125,-128) [-128|127.875] "m/s" ADC
 SG_ ARC_OD_ID_40_RL : 463|8@0+ (1,0) [0|255] "" ADC
 SG_ ARC_OD_ID_41_RL : 471|8@0+ (1,0) [0|255] "" ADC
 SG_ ARC_OD_MsgCounter_Obj_40_41_RL : 491|4@0+ (1,0) [0|15] "" ADC
 SG_ ARC_OD_CRC8_Obj_40_41_RL : 511|8@0+ (1,0) [0|256] "" ADC
 SG_ ARC_OD_AabsY_Obj_40_RL : 48|9@0+ (0.125,-31.875) [-31.875|32] "m/s^2" ADC
 SG_ ARC_OD_DistXStd_Obj_40_RL : 71|8@0+ (0.05,0) [0|12.75] "m" ADC
 SG_ ARC_OD_DistYStd_Obj_40_RL : 79|8@0+ (0.1,0) [0|25.5] "m" ADC
 SG_ ARC_OD_VabsXStd_Obj_40_RL : 87|7@0+ (0.1,0) [0|12.7] "m/s" ADC
 SG_ ARC_OD_VabsYStd_Obj_40_RL : 80|7@0+ (0.2,0) [0|25.4] "m/s" ADC
 SG_ ARC_OD_AabsXStd_Obj_40_RL : 89|7@0+ (0.25,0) [0|31.75] "m/s^2" ADC

BO_ 870 ARC_OD_42_43_RL: 64 ARC
 SG_ DistHeight_Obj_43_RL : 487|8@0+ (0.2,-10) [-10|41] "m" Vector__XXX
 SG_ DistHeight_Obj_42_RL : 479|8@0+ (0.2,-10) [-10|41] "m" Vector__XXX
 SG_ ARC_OD_DistX_Obj_42_RL : 7|12@0+ (0.1,-152) [-152|257.5] "m" ADC
 SG_ ARC_OD_Classification_Obj_42_RL : 98|3@0+ (1,0) [0|7] "" ADC
 SG_ ARC_OD_AabsYStd_Obj_42_RL : 111|8@0+ (0.25,0) [0|63.75] "m/s^2" ADC
 SG_ ARC_OD_ClassConf_Obj_42_RL : 119|7@0+ (1,0) [0|127] "%" ADC
 SG_ ARC_OD_ProbOfExist_Obj_42_RL : 112|7@0+ (1,0) [0|127] "%" ADC
 SG_ ARC_OD_VabsX_Obj_42_RL : 11|11@0+ (0.125,-128) [-128|127.875] "m/s" ADC
 SG_ ARC_OD_DynProp_Obj_42_RL : 130|3@0+ (1,0) [0|7] "" ADC
 SG_ ARC_OD_Length_Obj_42_RL : 136|7@0+ (0.2,0) [0|25.4] "m" ADC
 SG_ ARC_OD_MaintenanceState_Obj_0103 : 145|2@0+ (1,0) [0|3] "" ADC
 SG_ ARC_OD_Width_Obj_42_RL : 159|7@0+ (0.2,0) [0|25.4] "m" ADC
 SG_ ARC_OD_RCS_Obj_42_RL : 152|9@0+ (0.2,-51.1) [-51.1|51.1] "dBsm" ADC
 SG_ ARC_OD_Orientation_Obj_42_RL : 175|10@0+ (0.01,-5.11) [-5.11|5.12] "rad" ADC
 SG_ ARC_OD_LifeCycle_Obj_42_RL : 207|16@0+ (1,0) [0|65535] "" ADC
 SG_ ARC_OD_DistX_Obj_43_RL : 223|12@0+ (0.1,-152) [-152|257.5] "m" ADC
 SG_ ARC_OD_VabsX_Obj_43_RL : 227|11@0+ (0.125,-128) [-128|127.875] "m/s" ADC
 SG_ ARC_OD_AabsX_Obj_43_RL : 232|9@0+ (0.125,-31.875) [-31.875|32] "m/s^2" ADC
 SG_ ARC_OD_AabsX_Obj_42_RL : 16|9@0+ (0.125,-31.875) [-31.875|32] "m/s^2" ADC
 SG_ ARC_OD_DistY_Obj_43_RL : 255|12@0+ (0.0875,-179.113) [-179.113|179.2] "m" ADC
 SG_ ARC_OD_VabsY_Obj_43_RL : 259|11@0+ (0.125,-128) [-128|127.875] "m/s" ADC
 SG_ ARC_OD_AabsY_Obj_43_RL : 264|9@0+ (0.125,-31.875) [-31.875|32] "m/s^2" ADC
 SG_ ARC_OD_DistXStd_Obj_43_RL : 287|8@0+ (0.05,0) [0|12.75] "m" ADC
 SG_ ARC_OD_DistYStd_Obj_43_RL : 295|8@0+ (0.1,0) [0|25.5] "m" ADC
 SG_ ARC_OD_VabsXStd_Obj_43_RL : 303|7@0+ (0.1,0) [0|12.7] "m/s" ADC
 SG_ ARC_OD_VabsYStd_Obj_43_RL : 296|7@0+ (0.2,0) [0|25.4] "m/s" ADC
 SG_ ARC_OD_AabsXStd_Obj_43_RL : 305|7@0+ (0.25,0) [0|31.75] "m/s^2" ADC
 SG_ ARC_OD_Classification_Obj_43_RL : 314|3@0+ (1,0) [0|7] "" ADC
 SG_ ARC_OD_AabsYStd_Obj_43_RL : 327|8@0+ (0.25,0) [0|63.75] "m/s^2" ADC
 SG_ ARC_OD_ClassConf_Obj_43_RL : 335|7@0+ (1,0) [0|127] "%" ADC
 SG_ ARC_OD_DistY_Obj_42_RL : 39|12@0+ (0.0875,-179.113) [-179.113|179.2] "m" ADC
 SG_ ARC_OD_ProbOfExist_Obj_43_RL : 328|7@0+ (1,0) [0|127] "%" ADC
 SG_ ARC_OD_DynProp_Obj_43_RL : 346|3@0+ (1,0) [0|7] "" ADC
 SG_ ARC_OD_Length_Obj_43_RL : 352|7@0+ (0.2,0) [0|25.4] "m" ADC
 SG_ ARC_OD_MaintenanceState_Obj_0104 : 361|2@0+ (1,0) [0|3] "" ADC
 SG_ ARC_OD_Width_Obj_43_RL : 375|7@0+ (0.2,0) [0|25.4] "m" ADC
 SG_ ARC_OD_RCS_Obj_43_RL : 368|9@0+ (0.2,-51.1) [-51.1|51.1] "dBsm" ADC
 SG_ ARC_OD_Orientation_Obj_43_RL : 391|10@0+ (0.01,-5.11) [-5.11|5.12] "rad" ADC
 SG_ ARC_OD_LifeCycle_Obj_43_RL : 423|16@0+ (1,0) [0|65535] "" ADC
 SG_ ARC_OD_ObstacleProb_Obj_42_RL : 447|7@0+ (1,0) [0|127] "%" ADC
 SG_ ARC_OD_ObstacleProb_Obj_43_RL : 455|7@0+ (1,0) [0|127] "%" ADC
 SG_ ARC_OD_VabsY_Obj_42_RL : 43|11@0+ (0.125,-128) [-128|127.875] "m/s" ADC
 SG_ ARC_OD_ID_42_RL : 463|8@0+ (1,0) [0|255] "" ADC
 SG_ ARC_OD_ID_43_RL : 471|8@0+ (1,0) [0|255] "" ADC
 SG_ ARC_OD_MsgCounter_Obj_42_43_RL : 491|4@0+ (1,0) [0|15] "" ADC
 SG_ ARC_OD_CRC8_Obj_42_43_RL : 511|8@0+ (1,0) [0|256] "" ADC
 SG_ ARC_OD_AabsY_Obj_42_RL : 48|9@0+ (0.125,-31.875) [-31.875|32] "m/s^2" ADC
 SG_ ARC_OD_DistXStd_Obj_42_RL : 71|8@0+ (0.05,0) [0|12.75] "m" ADC
 SG_ ARC_OD_DistYStd_Obj_42_RL : 79|8@0+ (0.1,0) [0|25.5] "m" ADC
 SG_ ARC_OD_VabsXStd_Obj_42_RL : 87|7@0+ (0.1,0) [0|12.7] "m/s" ADC
 SG_ ARC_OD_VabsYStd_Obj_42_RL : 80|7@0+ (0.2,0) [0|25.4] "m/s" ADC
 SG_ ARC_OD_AabsXStd_Obj_42_RL : 89|7@0+ (0.25,0) [0|31.75] "m/s^2" ADC

BO_ 871 ARC_OD_44_45_RL: 64 ARC
 SG_ DistHeight_Obj_45_RL : 487|8@0+ (0.2,-10) [-10|41] "m" Vector__XXX
 SG_ DistHeight_Obj_44_RL : 479|8@0+ (0.2,-10) [-10|41] "m" Vector__XXX
 SG_ ARC_OD_DistX_Obj_44_RL : 7|12@0+ (0.1,-152) [-152|257.5] "m" ADC
 SG_ ARC_OD_Classification_Obj_44_RL : 98|3@0+ (1,0) [0|7] "" ADC
 SG_ ARC_OD_AabsYStd_Obj_44_RL : 111|8@0+ (0.25,0) [0|63.75] "m/s^2" ADC
 SG_ ARC_OD_ClassConf_Obj_44_RL : 119|7@0+ (1,0) [0|127] "%" ADC
 SG_ ARC_OD_ProbOfExist_Obj_44_RL : 112|7@0+ (1,0) [0|127] "%" ADC
 SG_ ARC_OD_VabsX_Obj_44_RL : 11|11@0+ (0.125,-128) [-128|127.875] "m/s" ADC
 SG_ ARC_OD_DynProp_Obj_44_RL : 130|3@0+ (1,0) [0|7] "" ADC
 SG_ ARC_OD_Length_Obj_44_RL : 136|7@0+ (0.2,0) [0|25.4] "m" ADC
 SG_ ARC_OD_MaintenanceState_Obj_0105 : 145|2@0+ (1,0) [0|3] "" ADC
 SG_ ARC_OD_Width_Obj_44_RL : 159|7@0+ (0.2,0) [0|25.4] "m" ADC
 SG_ ARC_OD_RCS_Obj_44_RL : 152|9@0+ (0.2,-51.1) [-51.1|51.1] "dBsm" ADC
 SG_ ARC_OD_Orientation_Obj_44_RL : 175|10@0+ (0.01,-5.11) [-5.11|5.12] "rad" ADC
 SG_ ARC_OD_LifeCycle_Obj_44_RL : 207|16@0+ (1,0) [0|65535] "" ADC
 SG_ ARC_OD_DistX_Obj_45_RL : 223|12@0+ (0.1,-152) [-152|257.5] "m" ADC
 SG_ ARC_OD_VabsX_Obj_45_RL : 227|11@0+ (0.125,-128) [-128|127.875] "m/s" ADC
 SG_ ARC_OD_AabsX_Obj_45_RL : 232|9@0+ (0.125,-31.875) [-31.875|32] "m/s^2" ADC
 SG_ ARC_OD_AabsX_Obj_44_RL : 16|9@0+ (0.125,-31.875) [-31.875|32] "m/s^2" ADC
 SG_ ARC_OD_DistY_Obj_45_RL : 255|12@0+ (0.0875,-179.113) [-179.113|179.2] "m" ADC
 SG_ ARC_OD_VabsY_Obj_45_RL : 259|11@0+ (0.125,-128) [-128|127.875] "m/s" ADC
 SG_ ARC_OD_AabsY_Obj_45_RL : 264|9@0+ (0.125,-31.875) [-31.875|32] "m/s^2" ADC
 SG_ ARC_OD_DistXStd_Obj_45_RL : 287|8@0+ (0.05,0) [0|12.75] "m" ADC
 SG_ ARC_OD_DistYStd_Obj_45_RL : 295|8@0+ (0.1,0) [0|25.5] "m" ADC
 SG_ ARC_OD_VabsXStd_Obj_45_RL : 303|7@0+ (0.1,0) [0|12.7] "m/s" ADC
 SG_ ARC_OD_VabsYStd_Obj_45_RL : 296|7@0+ (0.2,0) [0|25.4] "m/s" ADC
 SG_ ARC_OD_AabsXStd_Obj_45_RL : 305|7@0+ (0.25,0) [0|31.75] "m/s^2" ADC
 SG_ ARC_OD_Classification_Obj_45_RL : 314|3@0+ (1,0) [0|7] "" ADC
 SG_ ARC_OD_AabsYStd_Obj_45_RL : 327|8@0+ (0.25,0) [0|63.75] "m/s^2" ADC
 SG_ ARC_OD_ClassConf_Obj_45_RL : 335|7@0+ (1,0) [0|127] "%" ADC
 SG_ ARC_OD_DistY_Obj_44_RL : 39|12@0+ (0.0875,-179.113) [-179.113|179.2] "m" ADC
 SG_ ARC_OD_ProbOfExist_Obj_45_RL : 328|7@0+ (1,0) [0|127] "%" ADC
 SG_ ARC_OD_DynProp_Obj_45_RL : 346|3@0+ (1,0) [0|7] "" ADC
 SG_ ARC_OD_Length_Obj_45_RL : 352|7@0+ (0.2,0) [0|25.4] "m" ADC
 SG_ ARC_OD_MaintenanceState_Obj_0106 : 361|2@0+ (1,0) [0|3] "" ADC
 SG_ ARC_OD_Width_Obj_45_RL : 375|7@0+ (0.2,0) [0|25.4] "m" ADC
 SG_ ARC_OD_RCS_Obj_45_RL : 368|9@0+ (0.2,-51.1) [-51.1|51.1] "dBsm" ADC
 SG_ ARC_OD_Orientation_Obj_45_RL : 391|10@0+ (0.01,-5.11) [-5.11|5.12] "rad" ADC
 SG_ ARC_OD_LifeCycle_Obj_45_RL : 423|16@0+ (1,0) [0|65535] "" ADC
 SG_ ARC_OD_ObstacleProb_Obj_44_RL : 447|7@0+ (1,0) [0|127] "%" ADC
 SG_ ARC_OD_ObstacleProb_Obj_45_RL : 455|7@0+ (1,0) [0|127] "%" ADC
 SG_ ARC_OD_VabsY_Obj_44_RL : 43|11@0+ (0.125,-128) [-128|127.875] "m/s" ADC
 SG_ ARC_OD_ID_44_RL : 463|8@0+ (1,0) [0|255] "" ADC
 SG_ ARC_OD_ID_45_RL : 471|8@0+ (1,0) [0|255] "" ADC
 SG_ ARC_OD_MsgCounter_Obj_44_45_RL : 491|4@0+ (1,0) [0|15] "" ADC
 SG_ ARC_OD_CRC8_Obj_44_45_RL : 511|8@0+ (1,0) [0|256] "" ADC
 SG_ ARC_OD_AabsY_Obj_44_RL : 48|9@0+ (0.125,-31.875) [-31.875|32] "m/s^2" ADC
 SG_ ARC_OD_DistXStd_Obj_44_RL : 71|8@0+ (0.05,0) [0|12.75] "m" ADC
 SG_ ARC_OD_DistYStd_Obj_44_RL : 79|8@0+ (0.1,0) [0|25.5] "m" ADC
 SG_ ARC_OD_VabsXStd_Obj_44_RL : 87|7@0+ (0.1,0) [0|12.7] "m/s" ADC
 SG_ ARC_OD_VabsYStd_Obj_44_RL : 80|7@0+ (0.2,0) [0|25.4] "m/s" ADC
 SG_ ARC_OD_AabsXStd_Obj_44_RL : 89|7@0+ (0.25,0) [0|31.75] "m/s^2" ADC

BO_ 872 ARC_OD_46_47_RL: 64 ARC
 SG_ DistHeight_Obj_47_RL : 487|8@0+ (0.2,-10) [-10|41] "m" Vector__XXX
 SG_ DistHeight_Obj_46_RL : 479|8@0+ (0.2,-10) [-10|41] "m" Vector__XXX
 SG_ ARC_OD_DistX_Obj_46_RL : 7|12@0+ (0.1,-152) [-152|257.5] "m" ADC
 SG_ ARC_OD_Classification_Obj_46_RL : 98|3@0+ (1,0) [0|7] "" ADC
 SG_ ARC_OD_AabsYStd_Obj_46_RL : 111|8@0+ (0.25,0) [0|63.75] "m/s^2" ADC
 SG_ ARC_OD_ClassConf_Obj_46_RL : 119|7@0+ (1,0) [0|127] "%" ADC
 SG_ ARC_OD_ProbOfExist_Obj_46_RL : 112|7@0+ (1,0) [0|127] "%" ADC
 SG_ ARC_OD_VabsX_Obj_46_RL : 11|11@0+ (0.125,-128) [-128|127.875] "m/s" ADC
 SG_ ARC_OD_DynProp_Obj_46_RL : 130|3@0+ (1,0) [0|7] "" ADC
 SG_ ARC_OD_Length_Obj_46_RL : 136|7@0+ (0.2,0) [0|25.4] "m" ADC
 SG_ ARC_OD_MaintenanceState_Obj_0107 : 145|2@0+ (1,0) [0|3] "" ADC
 SG_ ARC_OD_Width_Obj_46_RL : 159|7@0+ (0.2,0) [0|25.4] "m" ADC
 SG_ ARC_OD_RCS_Obj_46_RL : 152|9@0+ (0.2,-51.1) [-51.1|51.1] "dBsm" ADC
 SG_ ARC_OD_Orientation_Obj_46_RL : 175|10@0+ (0.01,-5.11) [-5.11|5.12] "rad" ADC
 SG_ ARC_OD_LifeCycle_Obj_46_RL : 207|16@0+ (1,0) [0|65535] "" ADC
 SG_ ARC_OD_DistX_Obj_47_RL : 223|12@0+ (0.1,-152) [-152|257.5] "m" ADC
 SG_ ARC_OD_VabsX_Obj_47_RL : 227|11@0+ (0.125,-128) [-128|127.875] "m/s" ADC
 SG_ ARC_OD_AabsX_Obj_47_RL : 232|9@0+ (0.125,-31.875) [-31.875|32] "m/s^2" ADC
 SG_ ARC_OD_AabsX_Obj_46_RL : 16|9@0+ (0.125,-31.875) [-31.875|32] "m/s^2" ADC
 SG_ ARC_OD_DistY_Obj_47_RL : 255|12@0+ (0.0875,-179.113) [-179.113|179.2] "m" ADC
 SG_ ARC_OD_VabsY_Obj_47_RL : 259|11@0+ (0.125,-128) [-128|127.875] "m/s" ADC
 SG_ ARC_OD_AabsY_Obj_47_RL : 264|9@0+ (0.125,-31.875) [-31.875|32] "m/s^2" ADC
 SG_ ARC_OD_DistXStd_Obj_47_RL : 287|8@0+ (0.05,0) [0|12.75] "m" ADC
 SG_ ARC_OD_DistYStd_Obj_47_RL : 295|8@0+ (0.1,0) [0|25.5] "m" ADC
 SG_ ARC_OD_VabsXStd_Obj_47_RL : 303|7@0+ (0.1,0) [0|12.7] "m/s" ADC
 SG_ ARC_OD_VabsYStd_Obj_47_RL : 296|7@0+ (0.2,0) [0|25.4] "m/s" ADC
 SG_ ARC_OD_AabsXStd_Obj_47_RL : 305|7@0+ (0.25,0) [0|31.75] "m/s^2" ADC
 SG_ ARC_OD_Classification_Obj_47_RL : 314|3@0+ (1,0) [0|7] "" ADC
 SG_ ARC_OD_AabsYStd_Obj_47_RL : 327|8@0+ (0.25,0) [0|63.75] "m/s^2" ADC
 SG_ ARC_OD_ClassConf_Obj_47_RL : 335|7@0+ (1,0) [0|127] "%" ADC
 SG_ ARC_OD_DistY_Obj_46_RL : 39|12@0+ (0.0875,-179.113) [-179.113|179.2] "m" ADC
 SG_ ARC_OD_ProbOfExist_Obj_47_RL : 328|7@0+ (1,0) [0|127] "%" ADC
 SG_ ARC_OD_DynProp_Obj_47_RL : 346|3@0+ (1,0) [0|7] "" ADC
 SG_ ARC_OD_Length_Obj_47_RL : 352|7@0+ (0.2,0) [0|25.4] "m" ADC
 SG_ ARC_OD_MaintenanceState_Obj_0108 : 361|2@0+ (1,0) [0|3] "" ADC
 SG_ ARC_OD_Width_Obj_47_RL : 375|7@0+ (0.2,0) [0|25.4] "m" ADC
 SG_ ARC_OD_RCS_Obj_47_RL : 368|9@0+ (0.2,-51.1) [-51.1|51.1] "dBsm" ADC
 SG_ ARC_OD_Orientation_Obj_47_RL : 391|10@0+ (0.01,-5.11) [-5.11|5.12] "rad" ADC
 SG_ ARC_OD_LifeCycle_Obj_47_RL : 423|16@0+ (1,0) [0|65535] "" ADC
 SG_ ARC_OD_ObstacleProb_Obj_46_RL : 447|7@0+ (1,0) [0|127] "%" ADC
 SG_ ARC_OD_ObstacleProb_Obj_47_RL : 455|7@0+ (1,0) [0|127] "%" ADC
 SG_ ARC_OD_VabsY_Obj_46_RL : 43|11@0+ (0.125,-128) [-128|127.875] "m/s" ADC
 SG_ ARC_OD_ID_46_RL : 463|8@0+ (1,0) [0|255] "" ADC
 SG_ ARC_OD_ID_47_RL : 471|8@0+ (1,0) [0|255] "" ADC
 SG_ ARC_OD_MsgCounter_Obj_46_47_RL : 491|4@0+ (1,0) [0|15] "" ADC
 SG_ ARC_OD_CRC8_Obj_46_47_RL : 511|8@0+ (1,0) [0|256] "" ADC
 SG_ ARC_OD_AabsY_Obj_46_RL : 48|9@0+ (0.125,-31.875) [-31.875|32] "m/s^2" ADC
 SG_ ARC_OD_DistXStd_Obj_46_RL : 71|8@0+ (0.05,0) [0|12.75] "m" ADC
 SG_ ARC_OD_DistYStd_Obj_46_RL : 79|8@0+ (0.1,0) [0|25.5] "m" ADC
 SG_ ARC_OD_VabsXStd_Obj_46_RL : 87|7@0+ (0.1,0) [0|12.7] "m/s" ADC
 SG_ ARC_OD_VabsYStd_Obj_46_RL : 80|7@0+ (0.2,0) [0|25.4] "m/s" ADC
 SG_ ARC_OD_AabsXStd_Obj_46_RL : 89|7@0+ (0.25,0) [0|31.75] "m/s^2" ADC

BO_ 873 ARC_OD_48_49_RL: 64 ARC
 SG_ DistHeight_Obj_49_RL : 487|8@0+ (0.2,-10) [-10|41] "m" Vector__XXX
 SG_ DistHeight_Obj_48_RL : 479|8@0+ (0.2,-10) [-10|41] "m" Vector__XXX
 SG_ ARC_OD_DistX_Obj_48_RL : 7|12@0+ (0.1,-152) [-152|257.5] "m" ADC
 SG_ ARC_OD_Classification_Obj_48_RL : 98|3@0+ (1,0) [0|7] "" ADC
 SG_ ARC_OD_AabsYStd_Obj_48_RL : 111|8@0+ (0.25,0) [0|63.75] "m/s^2" ADC
 SG_ ARC_OD_ClassConf_Obj_48_RL : 119|7@0+ (1,0) [0|127] "%" ADC
 SG_ ARC_OD_ProbOfExist_Obj_48_RL : 112|7@0+ (1,0) [0|127] "%" ADC
 SG_ ARC_OD_VabsX_Obj_48_RL : 11|11@0+ (0.125,-128) [-128|127.875] "m/s" ADC
 SG_ ARC_OD_DynProp_Obj_48_RL : 130|3@0+ (1,0) [0|7] "" ADC
 SG_ ARC_OD_Length_Obj_48_RL : 136|7@0+ (0.2,0) [0|25.4] "m" ADC
 SG_ ARC_OD_MaintenanceState_Obj_0109 : 145|2@0+ (1,0) [0|3] "" ADC
 SG_ ARC_OD_Width_Obj_48_RL : 159|7@0+ (0.2,0) [0|25.4] "m" ADC
 SG_ ARC_OD_RCS_Obj_48_RL : 152|9@0+ (0.2,-51.1) [-51.1|51.1] "dBsm" ADC
 SG_ ARC_OD_Orientation_Obj_48_RL : 175|10@0+ (0.01,-5.11) [-5.11|5.12] "rad" ADC
 SG_ ARC_OD_LifeCycle_Obj_48_RL : 207|16@0+ (1,0) [0|65535] "" ADC
 SG_ ARC_OD_DistX_Obj_49_RL : 223|12@0+ (0.1,-152) [-152|257.5] "m" ADC
 SG_ ARC_OD_VabsX_Obj_49_RL : 227|11@0+ (0.125,-128) [-128|127.875] "m/s" ADC
 SG_ ARC_OD_AabsX_Obj_49_RL : 232|9@0+ (0.125,-31.875) [-31.875|32] "m/s^2" ADC
 SG_ ARC_OD_AabsX_Obj_48_RL : 16|9@0+ (0.125,-31.875) [-31.875|32] "m/s^2" ADC
 SG_ ARC_OD_DistY_Obj_49_RL : 255|12@0+ (0.0875,-179.113) [-179.113|179.2] "m" ADC
 SG_ ARC_OD_VabsY_Obj_49_RL : 259|11@0+ (0.125,-128) [-128|127.875] "m/s" ADC
 SG_ ARC_OD_AabsY_Obj_49_RL : 264|9@0+ (0.125,-31.875) [-31.875|32] "m/s^2" ADC
 SG_ ARC_OD_DistXStd_Obj_49_RL : 287|8@0+ (0.05,0) [0|12.75] "m" ADC
 SG_ ARC_OD_DistYStd_Obj_49_RL : 295|8@0+ (0.1,0) [0|25.5] "m" ADC
 SG_ ARC_OD_VabsXStd_Obj_49_RL : 303|7@0+ (0.1,0) [0|12.7] "m/s" ADC
 SG_ ARC_OD_VabsYStd_Obj_49_RL : 296|7@0+ (0.2,0) [0|25.4] "m/s" ADC
 SG_ ARC_OD_AabsXStd_Obj_49_RL : 305|7@0+ (0.25,0) [0|31.75] "m/s^2" ADC
 SG_ ARC_OD_Classification_Obj_49_RL : 314|3@0+ (1,0) [0|7] "" ADC
 SG_ ARC_OD_AabsYStd_Obj_49_RL : 327|8@0+ (0.25,0) [0|63.75] "m/s^2" ADC
 SG_ ARC_OD_ClassConf_Obj_49_RL : 335|7@0+ (1,0) [0|127] "%" ADC
 SG_ ARC_OD_DistY_Obj_48_RL : 39|12@0+ (0.0875,-179.113) [-179.113|179.2] "m" ADC
 SG_ ARC_OD_ProbOfExist_Obj_49_RL : 328|7@0+ (1,0) [0|127] "%" ADC
 SG_ ARC_OD_DynProp_Obj_49_RL : 346|3@0+ (1,0) [0|7] "" ADC
 SG_ ARC_OD_Length_Obj_49_RL : 352|7@0+ (0.2,0) [0|25.4] "m" ADC
 SG_ ARC_OD_MaintenanceState_Obj_0110 : 361|2@0+ (1,0) [0|3] "" ADC
 SG_ ARC_OD_Width_Obj_49_RL : 375|7@0+ (0.2,0) [0|25.4] "m" ADC
 SG_ ARC_OD_RCS_Obj_49_RL : 368|9@0+ (0.2,-51.1) [-51.1|51.1] "dBsm" ADC
 SG_ ARC_OD_Orientation_Obj_49_RL : 391|10@0+ (0.01,-5.11) [-5.11|5.12] "rad" ADC
 SG_ ARC_OD_LifeCycle_Obj_49_RL : 423|16@0+ (1,0) [0|65535] "" ADC
 SG_ ARC_OD_ObstacleProb_Obj_48_RL : 447|7@0+ (1,0) [0|127] "%" ADC
 SG_ ARC_OD_ObstacleProb_Obj_49_RL : 455|7@0+ (1,0) [0|127] "%" ADC
 SG_ ARC_OD_VabsY_Obj_48_RL : 43|11@0+ (0.125,-128) [-128|127.875] "m/s" ADC
 SG_ ARC_OD_ID_48_RL : 463|8@0+ (1,0) [0|255] "" ADC
 SG_ ARC_OD_ID_49_RL : 471|8@0+ (1,0) [0|255] "" ADC
 SG_ ARC_OD_MsgCounter_Obj_48_49_RL : 491|4@0+ (1,0) [0|15] "" ADC
 SG_ ARC_OD_CRC8_Obj_48_49_RL : 511|8@0+ (1,0) [0|256] "" ADC
 SG_ ARC_OD_AabsY_Obj_48_RL : 48|9@0+ (0.125,-31.875) [-31.875|32] "m/s^2" ADC
 SG_ ARC_OD_DistXStd_Obj_48_RL : 71|8@0+ (0.05,0) [0|12.75] "m" ADC
 SG_ ARC_OD_DistYStd_Obj_48_RL : 79|8@0+ (0.1,0) [0|25.5] "m" ADC
 SG_ ARC_OD_VabsXStd_Obj_48_RL : 87|7@0+ (0.1,0) [0|12.7] "m/s" ADC
 SG_ ARC_OD_VabsYStd_Obj_48_RL : 80|7@0+ (0.2,0) [0|25.4] "m/s" ADC
 SG_ ARC_OD_AabsXStd_Obj_48_RL : 89|7@0+ (0.25,0) [0|31.75] "m/s^2" ADC

BO_ 874 ARC_OD_50_51_RL: 64 ARC
 SG_ DistHeight_Obj_51_RL : 487|8@0+ (0.2,-10) [-10|41] "m" Vector__XXX
 SG_ DistHeight_Obj_50_RL : 479|8@0+ (0.2,-10) [-10|41] "m" Vector__XXX
 SG_ ARC_OD_DistX_Obj_50_RL : 7|12@0+ (0.1,-152) [-152|257.5] "m" ADC
 SG_ ARC_OD_Classification_Obj_50_RL : 98|3@0+ (1,0) [0|7] "" ADC
 SG_ ARC_OD_AabsYStd_Obj_50_RL : 111|8@0+ (0.25,0) [0|63.75] "m/s^2" ADC
 SG_ ARC_OD_ClassConf_Obj_50_RL : 119|7@0+ (1,0) [0|127] "%" ADC
 SG_ ARC_OD_ProbOfExist_Obj_50_RL : 112|7@0+ (1,0) [0|127] "%" ADC
 SG_ ARC_OD_VabsX_Obj_50_RL : 11|11@0+ (0.125,-128) [-128|127.875] "m/s" ADC
 SG_ ARC_OD_DynProp_Obj_50_RL : 130|3@0+ (1,0) [0|7] "" ADC
 SG_ ARC_OD_Length_Obj_50_RL : 136|7@0+ (0.2,0) [0|25.4] "m" ADC
 SG_ ARC_OD_MaintenanceState_Obj_0111 : 145|2@0+ (1,0) [0|3] "" ADC
 SG_ ARC_OD_Width_Obj_50_RL : 159|7@0+ (0.2,0) [0|25.4] "m" ADC
 SG_ ARC_OD_RCS_Obj_50_RL : 152|9@0+ (0.2,-51.1) [-51.1|51.1] "dBsm" ADC
 SG_ ARC_OD_Orientation_Obj_50_RL : 175|10@0+ (0.01,-5.11) [-5.11|5.12] "rad" ADC
 SG_ ARC_OD_LifeCycle_Obj_50_RL : 207|16@0+ (1,0) [0|65535] "" ADC
 SG_ ARC_OD_DistX_Obj_51_RL : 223|12@0+ (0.1,-152) [-152|257.5] "m" ADC
 SG_ ARC_OD_VabsX_Obj_51_RL : 227|11@0+ (0.125,-128) [-128|127.875] "m/s" ADC
 SG_ ARC_OD_AabsX_Obj_51_RL : 232|9@0+ (0.125,-31.875) [-31.875|32] "m/s^2" ADC
 SG_ ARC_OD_AabsX_Obj_50_RL : 16|9@0+ (0.125,-31.875) [-31.875|32] "m/s^2" ADC
 SG_ ARC_OD_DistY_Obj_51_RL : 255|12@0+ (0.0875,-179.113) [-179.113|179.2] "m" ADC
 SG_ ARC_OD_VabsY_Obj_51_RL : 259|11@0+ (0.125,-128) [-128|127.875] "m/s" ADC
 SG_ ARC_OD_AabsY_Obj_51_RL : 264|9@0+ (0.125,-31.875) [-31.875|32] "m/s^2" ADC
 SG_ ARC_OD_DistXStd_Obj_51_RL : 287|8@0+ (0.05,0) [0|12.75] "m" ADC
 SG_ ARC_OD_DistYStd_Obj_51_RL : 295|8@0+ (0.1,0) [0|25.5] "m" ADC
 SG_ ARC_OD_VabsXStd_Obj_51_RL : 303|7@0+ (0.1,0) [0|12.7] "m/s" ADC
 SG_ ARC_OD_VabsYStd_Obj_51_RL : 296|7@0+ (0.2,0) [0|25.4] "m/s" ADC
 SG_ ARC_OD_AabsXStd_Obj_51_RL : 305|7@0+ (0.25,0) [0|31.75] "m/s^2" ADC
 SG_ ARC_OD_Classification_Obj_51_RL : 314|3@0+ (1,0) [0|7] "" ADC
 SG_ ARC_OD_AabsYStd_Obj_51_RL : 327|8@0+ (0.25,0) [0|63.75] "m/s^2" ADC
 SG_ ARC_OD_ClassConf_Obj_51_RL : 335|7@0+ (1,0) [0|127] "%" ADC
 SG_ ARC_OD_DistY_Obj_50_RL : 39|12@0+ (0.0875,-179.113) [-179.113|179.2] "m" ADC
 SG_ ARC_OD_ProbOfExist_Obj_51_RL : 328|7@0+ (1,0) [0|127] "%" ADC
 SG_ ARC_OD_DynProp_Obj_51_RL : 346|3@0+ (1,0) [0|7] "" ADC
 SG_ ARC_OD_Length_Obj_51_RL : 352|7@0+ (0.2,0) [0|25.4] "m" ADC
 SG_ ARC_OD_MaintenanceState_Obj_0112 : 361|2@0+ (1,0) [0|3] "" ADC
 SG_ ARC_OD_Width_Obj_51_RL : 375|7@0+ (0.2,0) [0|25.4] "m" ADC
 SG_ ARC_OD_RCS_Obj_51_RL : 368|9@0+ (0.2,-51.1) [-51.1|51.1] "dBsm" ADC
 SG_ ARC_OD_Orientation_Obj_51_RL : 391|10@0+ (0.01,-5.11) [-5.11|5.12] "rad" ADC
 SG_ ARC_OD_LifeCycle_Obj_51_RL : 423|16@0+ (1,0) [0|65535] "" ADC
 SG_ ARC_OD_ObstacleProb_Obj_50_RL : 447|7@0+ (1,0) [0|127] "%" ADC
 SG_ ARC_OD_ObstacleProb_Obj_51_RL : 455|7@0+ (1,0) [0|127] "%" ADC
 SG_ ARC_OD_VabsY_Obj_50_RL : 43|11@0+ (0.125,-128) [-128|127.875] "m/s" ADC
 SG_ ARC_OD_ID_50_RL : 463|8@0+ (1,0) [0|255] "" ADC
 SG_ ARC_OD_ID_51_RL : 471|8@0+ (1,0) [0|255] "" ADC
 SG_ ARC_OD_MsgCounter_Obj_50_51_RL : 491|4@0+ (1,0) [0|15] "" ADC
 SG_ ARC_OD_CRC8_Obj_50_51_RL : 511|8@0+ (1,0) [0|256] "" ADC
 SG_ ARC_OD_AabsY_Obj_50_RL : 48|9@0+ (0.125,-31.875) [-31.875|32] "m/s^2" ADC
 SG_ ARC_OD_DistXStd_Obj_50_RL : 71|8@0+ (0.05,0) [0|12.75] "m" ADC
 SG_ ARC_OD_DistYStd_Obj_50_RL : 79|8@0+ (0.1,0) [0|25.5] "m" ADC
 SG_ ARC_OD_VabsXStd_Obj_50_RL : 87|7@0+ (0.1,0) [0|12.7] "m/s" ADC
 SG_ ARC_OD_VabsYStd_Obj_50_RL : 80|7@0+ (0.2,0) [0|25.4] "m/s" ADC
 SG_ ARC_OD_AabsXStd_Obj_50_RL : 89|7@0+ (0.25,0) [0|31.75] "m/s^2" ADC

BO_ 875 ARC_OD_52_53_RL: 64 ARC
 SG_ DistHeight_Obj_53_RL : 487|8@0+ (0.2,-10) [-10|41] "m" Vector__XXX
 SG_ DistHeight_Obj_52_RL : 479|8@0+ (0.2,-10) [-10|41] "m" Vector__XXX
 SG_ ARC_OD_DistX_Obj_52_RL : 7|12@0+ (0.1,-152) [-152|257.5] "m" ADC
 SG_ ARC_OD_Classification_Obj_52_RL : 98|3@0+ (1,0) [0|7] "" ADC
 SG_ ARC_OD_AabsYStd_Obj_52_RL : 111|8@0+ (0.25,0) [0|63.75] "m/s^2" ADC
 SG_ ARC_OD_ClassConf_Obj_52_RL : 119|7@0+ (1,0) [0|127] "%" ADC
 SG_ ARC_OD_ProbOfExist_Obj_52_RL : 112|7@0+ (1,0) [0|127] "%" ADC
 SG_ ARC_OD_VabsX_Obj_52_RL : 11|11@0+ (0.125,-128) [-128|127.875] "m/s" ADC
 SG_ ARC_OD_DynProp_Obj_52_RL : 130|3@0+ (1,0) [0|7] "" ADC
 SG_ ARC_OD_Length_Obj_52_RL : 136|7@0+ (0.2,0) [0|25.4] "m" ADC
 SG_ ARC_OD_MaintenanceState_Obj_0113 : 145|2@0+ (1,0) [0|3] "" ADC
 SG_ ARC_OD_Width_Obj_52_RL : 159|7@0+ (0.2,0) [0|25.4] "m" ADC
 SG_ ARC_OD_RCS_Obj_52_RL : 152|9@0+ (0.2,-51.1) [-51.1|51.1] "dBsm" ADC
 SG_ ARC_OD_Orientation_Obj_52_RL : 175|10@0+ (0.01,-5.11) [-5.11|5.12] "rad" ADC
 SG_ ARC_OD_LifeCycle_Obj_52_RL : 207|16@0+ (1,0) [0|65535] "" ADC
 SG_ ARC_OD_DistX_Obj_53_RL : 223|12@0+ (0.1,-152) [-152|257.5] "m" ADC
 SG_ ARC_OD_VabsX_Obj_53_RL : 227|11@0+ (0.125,-128) [-128|127.875] "m/s" ADC
 SG_ ARC_OD_AabsX_Obj_53_RL : 232|9@0+ (0.125,-31.875) [-31.875|32] "m/s^2" ADC
 SG_ ARC_OD_AabsX_Obj_52_RL : 16|9@0+ (0.125,-31.875) [-31.875|32] "m/s^2" ADC
 SG_ ARC_OD_DistY_Obj_53_RL : 255|12@0+ (0.0875,-179.113) [-179.113|179.2] "m" ADC
 SG_ ARC_OD_VabsY_Obj_53_RL : 259|11@0+ (0.125,-128) [-128|127.875] "m/s" ADC
 SG_ ARC_OD_AabsY_Obj_53_RL : 264|9@0+ (0.125,-31.875) [-31.875|32] "m/s^2" ADC
 SG_ ARC_OD_DistXStd_Obj_53_RL : 287|8@0+ (0.05,0) [0|12.75] "m" ADC
 SG_ ARC_OD_DistYStd_Obj_53_RL : 295|8@0+ (0.1,0) [0|25.5] "m" ADC
 SG_ ARC_OD_VabsXStd_Obj_53_RL : 303|7@0+ (0.1,0) [0|12.7] "m/s" ADC
 SG_ ARC_OD_VabsYStd_Obj_53_RL : 296|7@0+ (0.2,0) [0|25.4] "m/s" ADC
 SG_ ARC_OD_AabsXStd_Obj_53_RL : 305|7@0+ (0.25,0) [0|31.75] "m/s^2" ADC
 SG_ ARC_OD_Classification_Obj_53_RL : 314|3@0+ (1,0) [0|7] "" ADC
 SG_ ARC_OD_AabsYStd_Obj_53_RL : 327|8@0+ (0.25,0) [0|63.75] "m/s^2" ADC
 SG_ ARC_OD_ClassConf_Obj_53_RL : 335|7@0+ (1,0) [0|127] "%" ADC
 SG_ ARC_OD_DistY_Obj_52_RL : 39|12@0+ (0.0875,-179.113) [-179.113|179.2] "m" ADC
 SG_ ARC_OD_ProbOfExist_Obj_53_RL : 328|7@0+ (1,0) [0|127] "%" ADC
 SG_ ARC_OD_DynProp_Obj_53_RL : 346|3@0+ (1,0) [0|7] "" ADC
 SG_ ARC_OD_Length_Obj_53_RL : 352|7@0+ (0.2,0) [0|25.4] "m" ADC
 SG_ ARC_OD_MaintenanceState_Obj_0114 : 361|2@0+ (1,0) [0|3] "" ADC
 SG_ ARC_OD_Width_Obj_53_RL : 375|7@0+ (0.2,0) [0|25.4] "m" ADC
 SG_ ARC_OD_RCS_Obj_53_RL : 368|9@0+ (0.2,-51.1) [-51.1|51.1] "dBsm" ADC
 SG_ ARC_OD_Orientation_Obj_53_RL : 391|10@0+ (0.01,-5.11) [-5.11|5.12] "rad" ADC
 SG_ ARC_OD_LifeCycle_Obj_53_RL : 423|16@0+ (1,0) [0|65535] "" ADC
 SG_ ARC_OD_ObstacleProb_Obj_52_RL : 447|7@0+ (1,0) [0|127] "%" ADC
 SG_ ARC_OD_ObstacleProb_Obj_53_RL : 455|7@0+ (1,0) [0|127] "%" ADC
 SG_ ARC_OD_VabsY_Obj_52_RL : 43|11@0+ (0.125,-128) [-128|127.875] "m/s" ADC
 SG_ ARC_OD_ID_52_RL : 463|8@0+ (1,0) [0|255] "" ADC
 SG_ ARC_OD_ID_53_RL : 471|8@0+ (1,0) [0|255] "" ADC
 SG_ ARC_OD_MsgCounter_Obj_52_53_RL : 491|4@0+ (1,0) [0|15] "" ADC
 SG_ ARC_OD_CRC8_Obj_52_53_RL : 511|8@0+ (1,0) [0|256] "" ADC
 SG_ ARC_OD_AabsY_Obj_52_RL : 48|9@0+ (0.125,-31.875) [-31.875|32] "m/s^2" ADC
 SG_ ARC_OD_DistXStd_Obj_52_RL : 71|8@0+ (0.05,0) [0|12.75] "m" ADC
 SG_ ARC_OD_DistYStd_Obj_52_RL : 79|8@0+ (0.1,0) [0|25.5] "m" ADC
 SG_ ARC_OD_VabsXStd_Obj_52_RL : 87|7@0+ (0.1,0) [0|12.7] "m/s" ADC
 SG_ ARC_OD_VabsYStd_Obj_52_RL : 80|7@0+ (0.2,0) [0|25.4] "m/s" ADC
 SG_ ARC_OD_AabsXStd_Obj_52_RL : 89|7@0+ (0.25,0) [0|31.75] "m/s^2" ADC

BO_ 876 ARC_OD_54_55_RL: 64 ARC
 SG_ DistHeight_Obj_55_RL : 487|8@0+ (0.2,-10) [-10|41] "m" Vector__XXX
 SG_ DistHeight_Obj_54_RL : 479|8@0+ (0.2,-10) [-10|41] "m" Vector__XXX
 SG_ ARC_OD_DistX_Obj_54_RL : 7|12@0+ (0.1,-152) [-152|257.5] "m" ADC
 SG_ ARC_OD_Classification_Obj_54_RL : 98|3@0+ (1,0) [0|7] "" ADC
 SG_ ARC_OD_AabsYStd_Obj_54_RL : 111|8@0+ (0.25,0) [0|63.75] "m/s^2" ADC
 SG_ ARC_OD_ClassConf_Obj_54_RL : 119|7@0+ (1,0) [0|127] "%" ADC
 SG_ ARC_OD_ProbOfExist_Obj_54_RL : 112|7@0+ (1,0) [0|127] "%" ADC
 SG_ ARC_OD_VabsX_Obj_54_RL : 11|11@0+ (0.125,-128) [-128|127.875] "m/s" ADC
 SG_ ARC_OD_DynProp_Obj_54_RL : 130|3@0+ (1,0) [0|7] "" ADC
 SG_ ARC_OD_Length_Obj_54_RL : 136|7@0+ (0.2,0) [0|25.4] "m" ADC
 SG_ ARC_OD_MaintenanceState_Obj_0115 : 145|2@0+ (1,0) [0|3] "" ADC
 SG_ ARC_OD_Width_Obj_54_RL : 159|7@0+ (0.2,0) [0|25.4] "m" ADC
 SG_ ARC_OD_RCS_Obj_54_RL : 152|9@0+ (0.2,-51.1) [-51.1|51.1] "dBsm" ADC
 SG_ ARC_OD_Orientation_Obj_54_RL : 175|10@0+ (0.01,-5.11) [-5.11|5.12] "rad" ADC
 SG_ ARC_OD_LifeCycle_Obj_54_RL : 207|16@0+ (1,0) [0|65535] "" ADC
 SG_ ARC_OD_DistX_Obj_55_RL : 223|12@0+ (0.1,-152) [-152|257.5] "m" ADC
 SG_ ARC_OD_VabsX_Obj_55_RL : 227|11@0+ (0.125,-128) [-128|127.875] "m/s" ADC
 SG_ ARC_OD_AabsX_Obj_55_RL : 232|9@0+ (0.125,-31.875) [-31.875|32] "m/s^2" ADC
 SG_ ARC_OD_AabsX_Obj_54_RL : 16|9@0+ (0.125,-31.875) [-31.875|32] "m/s^2" ADC
 SG_ ARC_OD_DistY_Obj_55_RL : 255|12@0+ (0.0875,-179.113) [-179.113|179.2] "m" ADC
 SG_ ARC_OD_VabsY_Obj_55_RL : 259|11@0+ (0.125,-128) [-128|127.875] "m/s" ADC
 SG_ ARC_OD_AabsY_Obj_55_RL : 264|9@0+ (0.125,-31.875) [-31.875|32] "m/s^2" ADC
 SG_ ARC_OD_DistXStd_Obj_55_RL : 287|8@0+ (0.05,0) [0|12.75] "m" ADC
 SG_ ARC_OD_DistYStd_Obj_55_RL : 295|8@0+ (0.1,0) [0|25.5] "m" ADC
 SG_ ARC_OD_VabsXStd_Obj_55_RL : 303|7@0+ (0.1,0) [0|12.7] "m/s" ADC
 SG_ ARC_OD_VabsYStd_Obj_55_RL : 296|7@0+ (0.2,0) [0|25.4] "m/s" ADC
 SG_ ARC_OD_AabsXStd_Obj_55_RL : 305|7@0+ (0.25,0) [0|31.75] "m/s^2" ADC
 SG_ ARC_OD_Classification_Obj_55_RL : 314|3@0+ (1,0) [0|7] "" ADC
 SG_ ARC_OD_AabsYStd_Obj_55_RL : 327|8@0+ (0.25,0) [0|63.75] "m/s^2" ADC
 SG_ ARC_OD_ClassConf_Obj_55_RL : 335|7@0+ (1,0) [0|127] "%" ADC
 SG_ ARC_OD_DistY_Obj_54_RL : 39|12@0+ (0.0875,-179.113) [-179.113|179.2] "m" ADC
 SG_ ARC_OD_ProbOfExist_Obj_55_RL : 328|7@0+ (1,0) [0|127] "%" ADC
 SG_ ARC_OD_DynProp_Obj_55_RL : 346|3@0+ (1,0) [0|7] "" ADC
 SG_ ARC_OD_Length_Obj_55_RL : 352|7@0+ (0.2,0) [0|25.4] "m" ADC
 SG_ ARC_OD_MaintenanceState_Obj_0116 : 361|2@0+ (1,0) [0|3] "" ADC
 SG_ ARC_OD_Width_Obj_55_RL : 375|7@0+ (0.2,0) [0|25.4] "m" ADC
 SG_ ARC_OD_RCS_Obj_55_RL : 368|9@0+ (0.2,-51.1) [-51.1|51.1] "dBsm" ADC
 SG_ ARC_OD_Orientation_Obj_55_RL : 391|10@0+ (0.01,-5.11) [-5.11|5.12] "rad" ADC
 SG_ ARC_OD_LifeCycle_Obj_55_RL : 423|16@0+ (1,0) [0|65535] "" ADC
 SG_ ARC_OD_ObstacleProb_Obj_54_RL : 447|7@0+ (1,0) [0|127] "%" ADC
 SG_ ARC_OD_ObstacleProb_Obj_55_RL : 455|7@0+ (1,0) [0|127] "%" ADC
 SG_ ARC_OD_VabsY_Obj_54_RL : 43|11@0+ (0.125,-128) [-128|127.875] "m/s" ADC
 SG_ ARC_OD_ID_54_RL : 463|8@0+ (1,0) [0|255] "" ADC
 SG_ ARC_OD_ID_55_RL : 471|8@0+ (1,0) [0|255] "" ADC
 SG_ ARC_OD_MsgCounter_Obj_54_55_RL : 491|4@0+ (1,0) [0|15] "" ADC
 SG_ ARC_OD_CRC8_Obj_54_55_RL : 511|8@0+ (1,0) [0|256] "" ADC
 SG_ ARC_OD_AabsY_Obj_54_RL : 48|9@0+ (0.125,-31.875) [-31.875|32] "m/s^2" ADC
 SG_ ARC_OD_DistXStd_Obj_54_RL : 71|8@0+ (0.05,0) [0|12.75] "m" ADC
 SG_ ARC_OD_DistYStd_Obj_54_RL : 79|8@0+ (0.1,0) [0|25.5] "m" ADC
 SG_ ARC_OD_VabsXStd_Obj_54_RL : 87|7@0+ (0.1,0) [0|12.7] "m/s" ADC
 SG_ ARC_OD_VabsYStd_Obj_54_RL : 80|7@0+ (0.2,0) [0|25.4] "m/s" ADC
 SG_ ARC_OD_AabsXStd_Obj_54_RL : 89|7@0+ (0.25,0) [0|31.75] "m/s^2" ADC

BO_ 877 ARC_OD_56_57_RL: 64 ARC
 SG_ DistHeight_Obj_57_RL : 487|8@0+ (0.2,-10) [-10|41] "m" Vector__XXX
 SG_ DistHeight_Obj_56_RL : 479|8@0+ (0.2,-10) [-10|41] "m" Vector__XXX
 SG_ ARC_OD_DistX_Obj_56_RL : 7|12@0+ (0.1,-152) [-152|257.5] "m" ADC
 SG_ ARC_OD_Classification_Obj_56_RL : 98|3@0+ (1,0) [0|7] "" ADC
 SG_ ARC_OD_AabsYStd_Obj_56_RL : 111|8@0+ (0.25,0) [0|63.75] "m/s^2" ADC
 SG_ ARC_OD_ClassConf_Obj_56_RL : 119|7@0+ (1,0) [0|127] "%" ADC
 SG_ ARC_OD_ProbOfExist_Obj_56_RL : 112|7@0+ (1,0) [0|127] "%" ADC
 SG_ ARC_OD_VabsX_Obj_56_RL : 11|11@0+ (0.125,-128) [-128|127.875] "m/s" ADC
 SG_ ARC_OD_DynProp_Obj_56_RL : 130|3@0+ (1,0) [0|7] "" ADC
 SG_ ARC_OD_Length_Obj_56_RL : 136|7@0+ (0.2,0) [0|25.4] "m" ADC
 SG_ ARC_OD_MaintenanceState_Obj_0117 : 145|2@0+ (1,0) [0|3] "" ADC
 SG_ ARC_OD_Width_Obj_56_RL : 159|7@0+ (0.2,0) [0|25.4] "m" ADC
 SG_ ARC_OD_RCS_Obj_56_RL : 152|9@0+ (0.2,-51.1) [-51.1|51.1] "dBsm" ADC
 SG_ ARC_OD_Orientation_Obj_56_RL : 175|10@0+ (0.01,-5.11) [-5.11|5.12] "rad" ADC
 SG_ ARC_OD_LifeCycle_Obj_56_RL : 207|16@0+ (1,0) [0|65535] "" ADC
 SG_ ARC_OD_DistX_Obj_57_RL : 223|12@0+ (0.1,-152) [-152|257.5] "m" ADC
 SG_ ARC_OD_VabsX_Obj_57_RL : 227|11@0+ (0.125,-128) [-128|127.875] "m/s" ADC
 SG_ ARC_OD_AabsX_Obj_57_RL : 232|9@0+ (0.125,-31.875) [-31.875|32] "m/s^2" ADC
 SG_ ARC_OD_AabsX_Obj_56_RL : 16|9@0+ (0.125,-31.875) [-31.875|32] "m/s^2" ADC
 SG_ ARC_OD_DistY_Obj_57_RL : 255|12@0+ (0.0875,-179.113) [-179.113|179.2] "m" ADC
 SG_ ARC_OD_VabsY_Obj_57_RL : 259|11@0+ (0.125,-128) [-128|127.875] "m/s" ADC
 SG_ ARC_OD_AabsY_Obj_57_RL : 264|9@0+ (0.125,-31.875) [-31.875|32] "m/s^2" ADC
 SG_ ARC_OD_DistXStd_Obj_57_RL : 287|8@0+ (0.05,0) [0|12.75] "m" ADC
 SG_ ARC_OD_DistYStd_Obj_57_RL : 295|8@0+ (0.1,0) [0|25.5] "m" ADC
 SG_ ARC_OD_VabsXStd_Obj_57_RL : 303|7@0+ (0.1,0) [0|12.7] "m/s" ADC
 SG_ ARC_OD_VabsYStd_Obj_57_RL : 296|7@0+ (0.2,0) [0|25.4] "m/s" ADC
 SG_ ARC_OD_AabsXStd_Obj_57_RL : 305|7@0+ (0.25,0) [0|31.75] "m/s^2" ADC
 SG_ ARC_OD_Classification_Obj_57_RL : 314|3@0+ (1,0) [0|7] "" ADC
 SG_ ARC_OD_AabsYStd_Obj_57_RL : 327|8@0+ (0.25,0) [0|63.75] "m/s^2" ADC
 SG_ ARC_OD_ClassConf_Obj_57_RL : 335|7@0+ (1,0) [0|127] "%" ADC
 SG_ ARC_OD_DistY_Obj_56_RL : 39|12@0+ (0.0875,-179.113) [-179.113|179.2] "m" ADC
 SG_ ARC_OD_ProbOfExist_Obj_57_RL : 328|7@0+ (1,0) [0|127] "%" ADC
 SG_ ARC_OD_DynProp_Obj_57_RL : 346|3@0+ (1,0) [0|7] "" ADC
 SG_ ARC_OD_Length_Obj_57_RL : 352|7@0+ (0.2,0) [0|25.4] "m" ADC
 SG_ ARC_OD_MaintenanceState_Obj_0118 : 361|2@0+ (1,0) [0|3] "" ADC
 SG_ ARC_OD_Width_Obj_57_RL : 375|7@0+ (0.2,0) [0|25.4] "m" ADC
 SG_ ARC_OD_RCS_Obj_57_RL : 368|9@0+ (0.2,-51.1) [-51.1|51.1] "dBsm" ADC
 SG_ ARC_OD_Orientation_Obj_57_RL : 391|10@0+ (0.01,-5.11) [-5.11|5.12] "rad" ADC
 SG_ ARC_OD_LifeCycle_Obj_57_RL : 423|16@0+ (1,0) [0|65535] "" ADC
 SG_ ARC_OD_ObstacleProb_Obj_56_RL : 447|7@0+ (1,0) [0|127] "%" ADC
 SG_ ARC_OD_ObstacleProb_Obj_57_RL : 455|7@0+ (1,0) [0|127] "%" ADC
 SG_ ARC_OD_VabsY_Obj_56_RL : 43|11@0+ (0.125,-128) [-128|127.875] "m/s" ADC
 SG_ ARC_OD_ID_56_RL : 463|8@0+ (1,0) [0|255] "" ADC
 SG_ ARC_OD_ID_57_RL : 471|8@0+ (1,0) [0|255] "" ADC
 SG_ ARC_OD_MsgCounter_Obj_56_57_RL : 491|4@0+ (1,0) [0|15] "" ADC
 SG_ ARC_OD_CRC8_Obj_56_57_RL : 511|8@0+ (1,0) [0|256] "" ADC
 SG_ ARC_OD_AabsY_Obj_56_RL : 48|9@0+ (0.125,-31.875) [-31.875|32] "m/s^2" ADC
 SG_ ARC_OD_DistXStd_Obj_56_RL : 71|8@0+ (0.05,0) [0|12.75] "m" ADC
 SG_ ARC_OD_DistYStd_Obj_56_RL : 79|8@0+ (0.1,0) [0|25.5] "m" ADC
 SG_ ARC_OD_VabsXStd_Obj_56_RL : 87|7@0+ (0.1,0) [0|12.7] "m/s" ADC
 SG_ ARC_OD_VabsYStd_Obj_56_RL : 80|7@0+ (0.2,0) [0|25.4] "m/s" ADC
 SG_ ARC_OD_AabsXStd_Obj_56_RL : 89|7@0+ (0.25,0) [0|31.75] "m/s^2" ADC

BO_ 878 ARC_OD_58_59_RL: 64 ARC
 SG_ DistHeight_Obj_59_RL : 487|8@0+ (0.2,-10) [-10|41] "m" Vector__XXX
 SG_ DistHeight_Obj_58_RL : 479|8@0+ (0.2,-10) [-10|41] "m" Vector__XXX
 SG_ ARC_OD_DistX_Obj_58_RL : 7|12@0+ (0.1,-152) [-152|257.5] "m" ADC
 SG_ ARC_OD_Classification_Obj_58_RL : 98|3@0+ (1,0) [0|7] "" ADC
 SG_ ARC_OD_AabsYStd_Obj_58_RL : 111|8@0+ (0.25,0) [0|63.75] "m/s^2" ADC
 SG_ ARC_OD_ClassConf_Obj_58_RL : 119|7@0+ (1,0) [0|127] "%" ADC
 SG_ ARC_OD_ProbOfExist_Obj_58_RL : 112|7@0+ (1,0) [0|127] "%" ADC
 SG_ ARC_OD_VabsX_Obj_58_RL : 11|11@0+ (0.125,-128) [-128|127.875] "m/s" ADC
 SG_ ARC_OD_DynProp_Obj_58_RL : 130|3@0+ (1,0) [0|7] "" ADC
 SG_ ARC_OD_Length_Obj_58_RL : 136|7@0+ (0.2,0) [0|25.4] "m" ADC
 SG_ ARC_OD_MaintenanceState_Obj_0119 : 145|2@0+ (1,0) [0|3] "" ADC
 SG_ ARC_OD_Width_Obj_58_RL : 159|7@0+ (0.2,0) [0|25.4] "m" ADC
 SG_ ARC_OD_RCS_Obj_58_RL : 152|9@0+ (0.2,-51.1) [-51.1|51.1] "dBsm" ADC
 SG_ ARC_OD_Orientation_Obj_58_RL : 175|10@0+ (0.01,-5.11) [-5.11|5.12] "rad" ADC
 SG_ ARC_OD_LifeCycle_Obj_58_RL : 207|16@0+ (1,0) [0|65535] "" ADC
 SG_ ARC_OD_DistX_Obj_59_RL : 223|12@0+ (0.1,-152) [-152|257.5] "m" ADC
 SG_ ARC_OD_VabsX_Obj_59_RL : 227|11@0+ (0.125,-128) [-128|127.875] "m/s" ADC
 SG_ ARC_OD_AabsX_Obj_59_RL : 232|9@0+ (0.125,-31.875) [-31.875|32] "m/s^2" ADC
 SG_ ARC_OD_AabsX_Obj_58_RL : 16|9@0+ (0.125,-31.875) [-31.875|32] "m/s^2" ADC
 SG_ ARC_OD_DistY_Obj_59_RL : 255|12@0+ (0.0875,-179.113) [-179.113|179.2] "m" ADC
 SG_ ARC_OD_VabsY_Obj_59_RL : 259|11@0+ (0.125,-128) [-128|127.875] "m/s" ADC
 SG_ ARC_OD_AabsY_Obj_59_RL : 264|9@0+ (0.125,-31.875) [-31.875|32] "m/s^2" ADC
 SG_ ARC_OD_DistXStd_Obj_59_RL : 287|8@0+ (0.05,0) [0|12.75] "m" ADC
 SG_ ARC_OD_DistYStd_Obj_59_RL : 295|8@0+ (0.1,0) [0|25.5] "m" ADC
 SG_ ARC_OD_VabsXStd_Obj_59_RL : 303|7@0+ (0.1,0) [0|12.7] "m/s" ADC
 SG_ ARC_OD_VabsYStd_Obj_59_RL : 296|7@0+ (0.2,0) [0|25.4] "m/s" ADC
 SG_ ARC_OD_AabsXStd_Obj_59_RL : 305|7@0+ (0.25,0) [0|31.75] "m/s^2" ADC
 SG_ ARC_OD_Classification_Obj_59_RL : 314|3@0+ (1,0) [0|7] "" ADC
 SG_ ARC_OD_AabsYStd_Obj_59_RL : 327|8@0+ (0.25,0) [0|63.75] "m/s^2" ADC
 SG_ ARC_OD_ClassConf_Obj_59_RL : 335|7@0+ (1,0) [0|127] "%" ADC
 SG_ ARC_OD_DistY_Obj_58_RL : 39|12@0+ (0.0875,-179.113) [-179.113|179.2] "m" ADC
 SG_ ARC_OD_ProbOfExist_Obj_59_RL : 328|7@0+ (1,0) [0|127] "%" ADC
 SG_ ARC_OD_DynProp_Obj_59_RL : 346|3@0+ (1,0) [0|7] "" ADC
 SG_ ARC_OD_Length_Obj_59_RL : 352|7@0+ (0.2,0) [0|25.4] "m" ADC
 SG_ ARC_OD_MaintenanceState_Obj_0120 : 361|2@0+ (1,0) [0|3] "" ADC
 SG_ ARC_OD_Width_Obj_59_RL : 375|7@0+ (0.2,0) [0|25.4] "m" ADC
 SG_ ARC_OD_RCS_Obj_59_RL : 368|9@0+ (0.2,-51.1) [-51.1|51.1] "dBsm" ADC
 SG_ ARC_OD_Orientation_Obj_59_RL : 391|10@0+ (0.01,-5.11) [-5.11|5.12] "rad" ADC
 SG_ ARC_OD_LifeCycle_Obj_59_RL : 423|16@0+ (1,0) [0|65535] "" ADC
 SG_ ARC_OD_ObstacleProb_Obj_58_RL : 447|7@0+ (1,0) [0|127] "%" ADC
 SG_ ARC_OD_ObstacleProb_Obj_59_RL : 455|7@0+ (1,0) [0|127] "%" ADC
 SG_ ARC_OD_VabsY_Obj_58_RL : 43|11@0+ (0.125,-128) [-128|127.875] "m/s" ADC
 SG_ ARC_OD_ID_58_RL : 463|8@0+ (1,0) [0|255] "" ADC
 SG_ ARC_OD_ID_59_RL : 471|8@0+ (1,0) [0|255] "" ADC
 SG_ ARC_OD_MsgCounter_Obj_58_59_RL : 491|4@0+ (1,0) [0|15] "" ADC
 SG_ ARC_OD_CRC8_Obj_58_59_RL : 511|8@0+ (1,0) [0|256] "" ADC
 SG_ ARC_OD_AabsY_Obj_58_RL : 48|9@0+ (0.125,-31.875) [-31.875|32] "m/s^2" ADC
 SG_ ARC_OD_DistXStd_Obj_58_RL : 71|8@0+ (0.05,0) [0|12.75] "m" ADC
 SG_ ARC_OD_DistYStd_Obj_58_RL : 79|8@0+ (0.1,0) [0|25.5] "m" ADC
 SG_ ARC_OD_VabsXStd_Obj_58_RL : 87|7@0+ (0.1,0) [0|12.7] "m/s" ADC
 SG_ ARC_OD_VabsYStd_Obj_58_RL : 80|7@0+ (0.2,0) [0|25.4] "m/s" ADC
 SG_ ARC_OD_AabsXStd_Obj_58_RL : 89|7@0+ (0.25,0) [0|31.75] "m/s^2" ADC

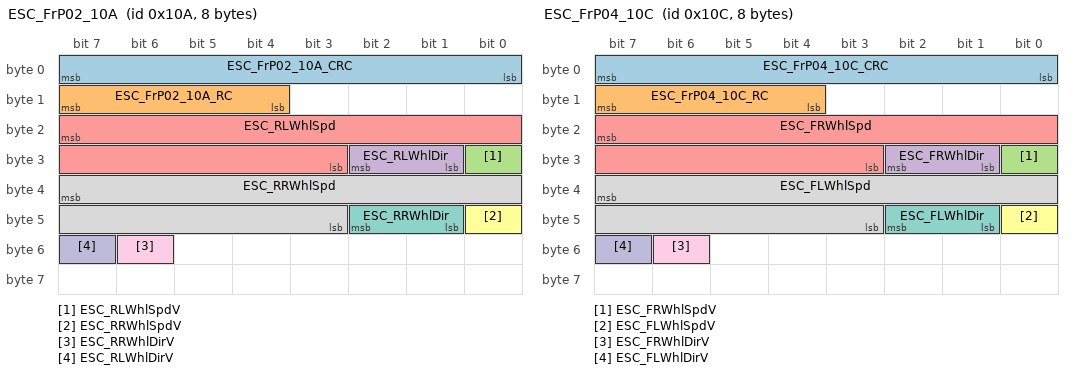
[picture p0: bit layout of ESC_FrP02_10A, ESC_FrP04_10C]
BO_ 266 ESC_FrP02_10A: 8 ADC
 SG_ ESC_FrP02_10A_CRC : 7|8@0+ (1,0) [0|255] "" ARC
 SG_ ESC_FrP02_10A_RC : 15|4@0+ (1,0) [0|15] "" ARC
 SG_ ESC_RLWhlSpdV : 24|1@0+ (1,0) [0|1] "" ARC
 SG_ ESC_RLWhlDir : 26|2@0+ (1,0) [0|3] "" ARC
 SG_ ESC_RLWhlSpd : 23|13@0+ (0.05625,0) [0|460.74375] "km/h" ARC
 SG_ ESC_RRWhlSpdV : 40|1@0+ (1,0) [0|1] "" ARC
 SG_ ESC_RRWhlDir : 42|2@0+ (1,0) [0|3] "" ARC
 SG_ ESC_RRWhlSpd : 39|13@0+ (0.05625,0) [0|460.74375] "km/h" ARC
 SG_ ESC_RRWhlDirV : 54|1@0+ (1,0) [0|1] "" ARC
 SG_ ESC_RLWhlDirV : 55|1@0+ (1,0) [0|1] "" ARC

BO_ 268 ESC_FrP04_10C: 8 ADC
 SG_ ESC_FrP04_10C_CRC : 7|8@0+ (1,0) [0|255] "" ARC
 SG_ ESC_FrP04_10C_RC : 15|4@0+ (1,0) [0|15] "" ARC
 SG_ ESC_FRWhlSpdV : 24|1@0+ (1,0) [0|1] "" ARC
 SG_ ESC_FRWhlDir : 26|2@0+ (1,0) [0|3] "" ARC
 SG_ ESC_FRWhlSpd : 23|13@0+ (0.05625,0) [0|460.74375] "km/h" ARC
 SG_ ESC_FLWhlSpdV : 40|1@0+ (1,0) [0|1] "" ARC
 SG_ ESC_FLWhlDir : 42|2@0+ (1,0) [0|3] "" ARC
 SG_ ESC_FLWhlSpd : 39|13@0+ (0.05625,0) [0|460.74375] "km/h" ARC
 SG_ ESC_FRWhlDirV : 54|1@0+ (1,0) [0|1] "" ARC
 SG_ ESC_FLWhlDirV : 55|1@0+ (1,0) [0|1] "" ARC

BO_ 271 ESC_FrP07_10F: 16 ADC
 SG_ ESC_LatSenSts : 9|1@0+ (1,0) [0|1] "" ARC
 SG_ ESC_YRSenSts : 10|1@0+ (1,0) [0|1] "" ARC
 SG_ ESC_LgtSenSt : 11|1@0+ (1,0) [0|1] "" ARC
 SG_ ESC_YR : 23|16@0+ (0.01,-300) [-300|355.35] "°/s" ARC
 SG_ ESC_LatAccelSenVal : 39|16@0+ (0.001,-6) [-6|59.535] "g" ARC
 SG_ ESC_LgtAccel : 55|16@0+ (0.001,-6) [-6|59.535] "g" ARC

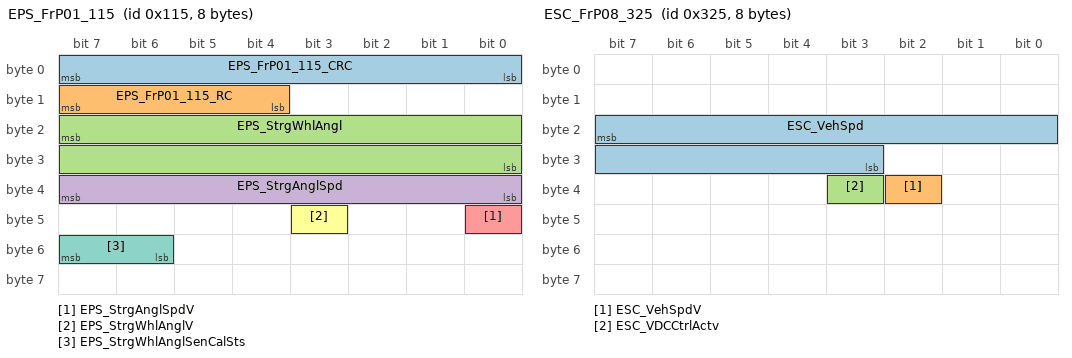
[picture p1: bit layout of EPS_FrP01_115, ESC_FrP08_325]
BO_ 277 EPS_FrP01_115: 8 ADC
 SG_ EPS_FrP01_115_CRC : 7|8@0+ (1,0) [0|255] "" ARC
 SG_ EPS_FrP01_115_RC : 15|4@0+ (1,0) [0|15] "" ARC
 SG_ EPS_StrgWhlAngl : 23|16@0+ (0.0625,-2048) [-2048|2047.9375] "deg" ARC
 SG_ EPS_StrgAnglSpd : 39|8@0+ (4,0) [0|1020] "deg/s" ARC
 SG_ EPS_StrgAnglSpdV : 40|1@0+ (1,0) [0|1] "" ARC
 SG_ EPS_StrgWhlAnglV : 43|1@0+ (1,0) [0|1] "" ARC
 SG_ EPS_StrgWhlAnglSenCalSts : 55|2@0+ (1,0) [0|3] "" ARC

BO_ 805 ESC_FrP08_325: 8 ADC
 SG_ ESC_VehSpd : 23|13@0+ (0.05625,0) [0|460.74375] "km/h" ARC
 SG_ ESC_VehSpdV : 34|1@0+ (1,0) [0|1] "" ARC
 SG_ ESC_VDCCtrlActv : 35|1@0+ (1,0) [0|1] "" ARC

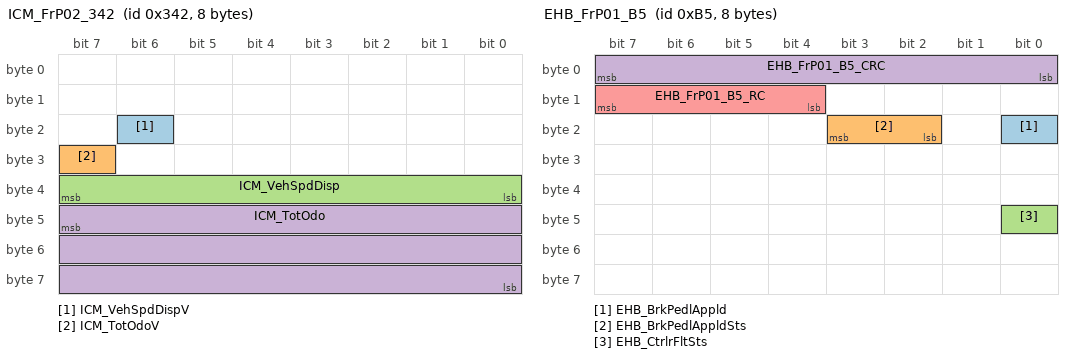
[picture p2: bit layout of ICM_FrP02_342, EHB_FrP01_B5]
BO_ 834 ICM_FrP02_342: 8 ADC
 SG_ ICM_VehSpdDispV : 22|1@0+ (1,0) [0|1] "" ARC
 SG_ ICM_TotOdoV : 31|1@0+ (1,0) [0|1] "" ARC
 SG_ ICM_VehSpdDisp : 39|8@0+ (1,0) [0|255] "" ARC
 SG_ ICM_TotOdo : 47|24@0+ (0.1,0) [0|1677721.5] "" ARC

BO_ 819 ADC_TimeSync: 16 ADC
 SG_ Sync_Counter : 19|4@0+ (1,0) [0|15] "" ARC
 SG_ Sync_CRC : 15|8@0+ (1,0) [0|255] "" ARC
 SG_ Sync_OVS : 25|2@0+ (1,0) [0|3] "" ARC
 SG_ Sync_Resd : 31|5@0+ (1,0) [0|31] "" ARC
 SG_ Sync_SGW : 26|1@0+ (1,0) [0|1] "" ARC
 SG_ Sync_SyncTime : 39|32@0+ (1,0) [0|4294967295] "s" ARC
 SG_ Sync_TimeDomain : 23|4@0+ (1,0) [0|15] "" ARC
 SG_ Sync_Type : 7|8@0+ (1,0) [0|255] "" ARC

BO_ 267 ESC_FrP03_10B: 32 ADC
 SG_ ESC_FrP03_10B_CRC_1 : 7|8@0+ (1,0) [0|255] "" ARC
 SG_ ESC_EBDActv : 8|1@0+ (1,0) [0|1] "" ARC
 SG_ ESC_FrP03_10B_RC_1 : 15|4@0+ (1,0) [0|15] "" ARC
 SG_ ESC_TCSActv : 26|1@0+ (1,0) [0|1] "" ARC
 SG_ ESC_ABSActv : 27|1@0+ (1,0) [0|1] "" ARC
 SG_ ESC_ESCFld : 49|1@0+ (1,0) [0|1] "" ARC
 SG_ ESC_CDPActv : 57|1@0+ (1,0) [0|1] "" ARC
 SG_ ESC_HDCSts : 85|2@0+ (1,0) [0|3] "" ARC
 SG_ ESC_Off : 88|1@0+ (1,0) [0|1] "" ARC
 SG_ ESC_ABAAvlbl : 113|1@0+ (1,0) [0|1] "" ARC
 SG_ ESC_ABAActv : 114|1@0+ (1,0) [0|1] "" ARC
 SG_ ESC_FrP03_10B_CRC_3 : 135|8@0+ (1,0) [0|255] "" ARC
 SG_ ESC_FrP03_10B_RC_3 : 143|4@0+ (1,0) [0|15] "" ARC
 SG_ ESC_FrP03_10B_CRC_4 : 199|8@0+ (1,0) [0|255] "" ARC
 SG_ ESC_FrP03_10B_RC_4 : 207|4@0+ (1,0) [0|15] "" ARC
 SG_ ESC_FrP03_10B_CRC_2 : 71|8@0+ (1,0) [0|255] "" ARC
 SG_ ESC_FrP03_10B_RC_2 : 79|4@0+ (1,0) [0|15] "" ARC

BO_ 269 ESC_FrP05_10D: 8 ADC
 SG_ ESC_VehStdslSts : 44|1@0+ (1,0) [0|1] "" ARC
 SG_ ESC_VehStdslStsV : 45|1@0+ (1,0) [0|1] "" ARC

BO_ 181 EHB_FrP01_B5: 8 ADC
 SG_ EHB_BrkPedlAppld : 16|1@0+ (1,0) [0|1] "" ARC
 SG_ EHB_BrkPedlAppldSts : 19|2@0+ (1,0) [0|3] "" ARC
 SG_ EHB_CtrlrFltSts : 40|1@0+ (1,0) [0|1] "" ARC
 SG_ EHB_FrP01_B5_CRC : 7|8@0+ (1,0) [0|255] "" ARC
 SG_ EHB_FrP01_B5_RC : 15|4@0+ (1,0) [0|15] "" ARC

CM_ SG_ 266 ESC_FrP02_10A_RC "/";
CM_ SG_ 266 ESC_RLWhlSpdV "����������Ч��";
CM_ SG_ 266 ESC_RLWhlDir "�������ٷ���";
CM_ SG_ 266 ESC_RLWhlSpd "����������";
CM_ SG_ 266 ESC_RRWhlSpdV "�Һ�������Ч��";
CM_ SG_ 266 ESC_RRWhlDir "�Һ����ٷ���";
CM_ SG_ 266 ESC_RRWhlSpd "�Һ�������";
CM_ SG_ 266 ESC_RRWhlDirV "�Һ����ٷ�����Ч��";
CM_ SG_ 266 ESC_RLWhlDirV "�������ٷ�����Ч��";
CM_ SG_ 268 ESC_FrP04_10C_RC "/";
CM_ SG_ 268 ESC_FRWhlSpdV "��ǰ������Ч��";
CM_ SG_ 268 ESC_FRWhlDir "��ǰ�ַ���";
CM_ SG_ 268 ESC_FRWhlSpd "��ǰ������";
CM_ SG_ 268 ESC_FLWhlSpdV "��ǰ������Ч��";
CM_ SG_ 268 ESC_FLWhlDir "��ǰ�ַ���";
CM_ SG_ 268 ESC_FLWhlSpd "��ǰ������";
CM_ SG_ 268 ESC_FRWhlDirV "��ǰ�ַ�����Ч��";
CM_ SG_ 268 ESC_FLWhlDirV "��ǰ�ַ�����Ч��";
CM_ SG_ 271 ESC_LatSenSts "������ٶ���Ч��";
CM_ SG_ 271 ESC_YRSenSts "��ڽ��ٶ���Ч��";
CM_ SG_ 271 ESC_LgtSenSt "������ٶ���Ч��";
CM_ SG_ 271 ESC_YR "��ڽ��ٶ�";
CM_ SG_ 271 ESC_LatAccelSenVal "������ٶ�ֵ";
CM_ SG_ 271 ESC_LgtAccel "������ٶ�ֵ";
CM_ SG_ 277 EPS_FrP01_115_RC "/";
CM_ SG_ 277 EPS_StrgWhlAngl "������ת�ǣ������Ҹ���";
CM_ SG_ 277 EPS_StrgAnglSpd "������ת������";
CM_ SG_ 277 EPS_StrgAnglSpdV "������ת��������Ч��";
CM_ SG_ 277 EPS_StrgWhlAnglV "Steering Wheel Angle Validity";
CM_ SG_ 277 EPS_StrgWhlAnglSenCalSts "Steering Wheel Angle Sensor Calibration Status";
CM_ SG_ 805 ESC_VehSpd "����";
CM_ SG_ 805 ESC_VehSpdV "������Ч��";
CM_ SG_ 805 ESC_VDCCtrlActv "VDC�Ƿ񼤻�";
CM_ SG_ 834 ICM_VehSpdDispV "/";
CM_ SG_ 819 Sync_Counter "ʱ��ͬ��-������������ֵ";
CM_ SG_ 819 Sync_CRC "ʱ��ͬ��-CRCУ��ֵ";
CM_ SG_ 819 Sync_OVS "ʱ��ͬ��-������� Overflow of seconds";
CM_ SG_ 819 Sync_Resd "ʱ��ͬ��-������Ϣ";
CM_ SG_ 819 Sync_SGW "ʱ��ͬ��-ͬ��״̬";
CM_ SG_ 819 Sync_SyncTime "ʱ��ͬ��-����ͬ��ʱ��";
CM_ SG_ 819 Sync_TimeDomain "ʱ��ͬ��-ʱ��ͬ����";
CM_ SG_ 819 Sync_Type "ʱ��ͬ��-֡����";
CM_ SG_ 267 ESC_EBDActv "EBD����״̬";
CM_ SG_ 267 ESC_TCSActv "TCS����״̬";
CM_ SG_ 267 ESC_ABSActv "ABS����״̬";
CM_ SG_ 267 ESC_ESCFld "ESC�ź���ʾESCʧ��";
CM_ SG_ 267 ESC_CDPActv "CDP����״̬";
CM_ SG_ 267 ESC_HDCSts "HDC״̬";
CM_ SG_ 267 ESC_Off "ESP�ر�";
CM_ SG_ 181 EHB_BrkPedlAppld "�ƶ�̤���Ƿ񱻼�ʻԱ����";
CM_ SG_ 181 EHB_BrkPedlAppldSts "BrakePedalApplied�ź�״̬";

BA_DEF_ BO_ "GenMsgCycleTime" INT 0 65535;
BA_DEF_ BO_ "GenMsgSendType" ENUM "Cycle","OnChange","OnWrite","OnWriteWithRepetition","OnChangeWithRepetition","IfActive","IfActiveWithRepetition","NoMsgSendType";
BA_DEF_ BO_ "VFrameFormat" ENUM "StandardCAN","ExtendedCAN","reserved","reserved","reserved","reserved","reserved","reserved","reserved","reserved","reserved","reserved","reserved","reserved","StandardCAN_FD","ExtendedCAN_FD";
BA_DEF_ SG_ "GenSigILSupport" ENUM "No","Yes";
BA_DEF_ SG_ "GenSigInactiveValue" HEX 0 0;
BA_DEF_ SG_ "GenSigSendType" ENUM "Cycle","OnWrite","OnWriteWithRepetition","OnChange","OnChangeWithRepetition","IfActive","IfActiveWithRepetition","NoSigSendType","vector_leerstring";
BA_DEF_ SG_ "GenSigStartValue" FLOAT 0 100000000000;
BA_DEF_DEF_ "GenMsgCycleTime" 0;
BA_DEF_DEF_ "GenMsgSendType" "Cycle";
BA_DEF_DEF_ "VFrameFormat" "StandardCAN";
BA_DEF_DEF_ "GenSigILSupport" "Yes";
BA_DEF_DEF_ "GenSigSendType" "NoSigSendType";
BA_DEF_DEF_ "GenSigStartValue" 0;
BA_DEF_DEF_ "GenSigInactiveValue" 0;
BA_ "GenMsgCycleTime" BO_ 856 50;
BA_ "VFrameFormat" BO_ 856 14;
BA_ "GenMsgCycleTime" BO_ 857 50;
BA_ "VFrameFormat" BO_ 857 14;
BA_ "GenMsgCycleTime" BO_ 858 50;
BA_ "VFrameFormat" BO_ 858 14;
BA_ "GenMsgCycleTime" BO_ 859 50;
BA_ "VFrameFormat" BO_ 859 14;
BA_ "GenMsgCycleTime" BO_ 860 50;
BA_ "VFrameFormat" BO_ 860 14;
BA_ "GenMsgCycleTime" BO_ 861 50;
BA_ "VFrameFormat" BO_ 861 14;
BA_ "GenMsgCycleTime" BO_ 862 50;
BA_ "VFrameFormat" BO_ 862 14;
BA_ "GenMsgCycleTime" BO_ 863 50;
BA_ "VFrameFormat" BO_ 863 14;
BA_ "GenMsgCycleTime" BO_ 864 50;
BA_ "VFrameFormat" BO_ 864 14;
BA_ "GenMsgCycleTime" BO_ 865 50;
BA_ "VFrameFormat" BO_ 865 14;
BA_ "GenMsgCycleTime" BO_ 866 50;
BA_ "VFrameFormat" BO_ 866 14;
BA_ "GenMsgCycleTime" BO_ 867 50;
BA_ "VFrameFormat" BO_ 867 14;
BA_ "GenMsgCycleTime" BO_ 868 50;
BA_ "VFrameFormat" BO_ 868 14;
BA_ "GenMsgCycleTime" BO_ 869 50;
BA_ "VFrameFormat" BO_ 869 14;
BA_ "GenMsgCycleTime" BO_ 870 50;
BA_ "VFrameFormat" BO_ 870 14;
BA_ "GenMsgCycleTime" BO_ 871 50;
BA_ "VFrameFormat" BO_ 871 14;
BA_ "GenMsgCycleTime" BO_ 872 50;
BA_ "VFrameFormat" BO_ 872 14;
BA_ "GenMsgCycleTime" BO_ 873 50;
BA_ "VFrameFormat" BO_ 873 14;
BA_ "GenMsgCycleTime" BO_ 874 50;
BA_ "VFrameFormat" BO_ 874 14;
BA_ "GenMsgCycleTime" BO_ 875 50;
BA_ "VFrameFormat" BO_ 875 14;
BA_ "GenMsgCycleTime" BO_ 876 50;
BA_ "VFrameFormat" BO_ 876 14;
BA_ "GenMsgCycleTime" BO_ 877 50;
BA_ "VFrameFormat" BO_ 877 14;
BA_ "GenMsgCycleTime" BO_ 878 50;
BA_ "VFrameFormat" BO_ 878 14;
BA_ "GenMsgCycleTime" BO_ 266 20;
BA_ "VFrameFormat" BO_ 266 14;
BA_ "GenMsgCycleTime" BO_ 268 20;
BA_ "VFrameFormat" BO_ 268 14;
BA_ "GenMsgCycleTime" BO_ 271 20;
BA_ "VFrameFormat" BO_ 271 14;
BA_ "GenMsgCycleTime" BO_ 277 20;
BA_ "VFrameFormat" BO_ 277 14;
BA_ "GenMsgCycleTime" BO_ 805 100;
BA_ "VFrameFormat" BO_ 805 14;
BA_ "GenMsgCycleTime" BO_ 834 100;
BA_ "VFrameFormat" BO_ 834 14;
BA_ "GenMsgCycleTime" BO_ 819 500;
BA_ "VFrameFormat" BO_ 819 14;
BA_ "GenMsgCycleTime" BO_ 267 20;
BA_ "VFrameFormat" BO_ 267 14;
BA_ "GenMsgCycleTime" BO_ 269 20;
BA_ "VFrameFormat" BO_ 269 14;
BA_ "VFrameFormat" BO_ 181 14;
BA_ "GenSigSendType" SG_ 856 DistHeight_Obj_15_RL 8;
BA_ "GenSigSendType" SG_ 856 DistHeight_Obj_14_RL 8;
BA_ "GenSigSendType" SG_ 856 ARC_OD_DistX_Obj_14_RL 8;
BA_ "GenSigSendType" SG_ 856 ARC_OD_Classification_Obj_14_RL 8;
BA_ "GenSigSendType" SG_ 856 ARC_OD_AabsYStd_Obj_14_RL 8;
BA_ "GenSigSendType" SG_ 856 ARC_OD_ClassConf_Obj_14_RL 8;
BA_ "GenSigSendType" SG_ 856 ARC_OD_ProbOfExist_Obj_14_RL 8;
BA_ "GenSigSendType" SG_ 856 ARC_OD_VabsX_Obj_14_RL 8;
BA_ "GenSigSendType" SG_ 856 ARC_OD_DynProp_Obj_14_RL 8;
BA_ "GenSigSendType" SG_ 856 ARC_OD_Length_Obj_14_RL 8;
BA_ "GenSigSendType" SG_ 856 ARC_OD_MaintenanceState_Obj_0075 8;
BA_ "GenSigSendType" SG_ 856 ARC_OD_Width_Obj_14_RL 8;
BA_ "GenSigSendType" SG_ 856 ARC_OD_RCS_Obj_14_RL 8;
BA_ "GenSigSendType" SG_ 856 ARC_OD_Orientation_Obj_14_RL 8;
BA_ "GenSigSendType" SG_ 856 ARC_OD_LifeCycle_Obj_14_RL 8;
BA_ "GenSigSendType" SG_ 856 ARC_OD_DistX_Obj_15_RL 8;
BA_ "GenSigSendType" SG_ 856 ARC_OD_VabsX_Obj_15_RL 8;
BA_ "GenSigSendType" SG_ 856 ARC_OD_AabsX_Obj_15_RL 8;
BA_ "GenSigSendType" SG_ 856 ARC_OD_AabsX_Obj_14_RL 8;
BA_ "GenSigSendType" SG_ 856 ARC_OD_DistY_Obj_15_RL 8;
BA_ "GenSigSendType" SG_ 856 ARC_OD_VabsY_Obj_15_RL 8;
BA_ "GenSigSendType" SG_ 856 ARC_OD_AabsY_Obj_15_RL 8;
BA_ "GenSigSendType" SG_ 856 ARC_OD_DistXStd_Obj_15_RL 8;
BA_ "GenSigSendType" SG_ 856 ARC_OD_DistYStd_Obj_15_RL 8;
BA_ "GenSigSendType" SG_ 856 ARC_OD_VabsXStd_Obj_15_RL 8;
BA_ "GenSigSendType" SG_ 856 ARC_OD_VabsYStd_Obj_15_RL 8;
BA_ "GenSigSendType" SG_ 856 ARC_OD_AabsXStd_Obj_15_RL 8;
BA_ "GenSigSendType" SG_ 856 ARC_OD_Classification_Obj_15_RL 8;
BA_ "GenSigSendType" SG_ 856 ARC_OD_AabsYStd_Obj_15_RL 8;
BA_ "GenSigSendType" SG_ 856 ARC_OD_ClassConf_Obj_15_RL 8;
BA_ "GenSigSendType" SG_ 856 ARC_OD_DistY_Obj_14_RL 8;
BA_ "GenSigSendType" SG_ 856 ARC_OD_ProbOfExist_Obj_15_RL 8;
BA_ "GenSigSendType" SG_ 856 ARC_OD_DynProp_Obj_15_RL 8;
BA_ "GenSigSendType" SG_ 856 ARC_OD_Length_Obj_15_RL 8;
BA_ "GenSigSendType" SG_ 856 ARC_OD_MaintenanceState_Obj_0076 8;
BA_ "GenSigSendType" SG_ 856 ARC_OD_Width_Obj_15_RL 8;
BA_ "GenSigSendType" SG_ 856 ARC_OD_RCS_Obj_15_RL 8;
BA_ "GenSigSendType" SG_ 856 ARC_OD_Orientation_Obj_15_RL 8;
BA_ "GenSigSendType" SG_ 856 ARC_OD_LifeCycle_Obj_15_RL 8;
BA_ "GenSigSendType" SG_ 856 ARC_OD_ObstacleProb_Obj_14_RL 8;
BA_ "GenSigSendType" SG_ 856 ARC_OD_ObstacleProb_Obj_15_RL 8;
BA_ "GenSigSendType" SG_ 856 ARC_OD_VabsY_Obj_14_RL 8;
BA_ "GenSigSendType" SG_ 856 ARC_OD_ID_14_RL 8;
BA_ "GenSigSendType" SG_ 856 ARC_OD_ID_15_RL 8;
BA_ "GenSigSendType" SG_ 856 ARC_OD_MsgCounter_Obj_14_15_RL 8;
BA_ "GenSigSendType" SG_ 856 ARC_OD_CRC8_Obj_14_15_RL 8;
BA_ "GenSigSendType" SG_ 856 ARC_OD_AabsY_Obj_14_RL 8;
BA_ "GenSigSendType" SG_ 856 ARC_OD_DistXStd_Obj_14_RL 8;
BA_ "GenSigSendType" SG_ 856 ARC_OD_DistYStd_Obj_14_RL 8;
BA_ "GenSigSendType" SG_ 856 ARC_OD_VabsXStd_Obj_14_RL 8;
BA_ "GenSigSendType" SG_ 856 ARC_OD_VabsYStd_Obj_14_RL 8;
BA_ "GenSigSendType" SG_ 856 ARC_OD_AabsXStd_Obj_14_RL 8;
BA_ "GenSigSendType" SG_ 857 DistHeight_Obj_17_RL 8;
BA_ "GenSigSendType" SG_ 857 DistHeight_Obj_16_RL 8;
BA_ "GenSigSendType" SG_ 857 ARC_OD_DistX_Obj_16_RL 8;
BA_ "GenSigSendType" SG_ 857 ARC_OD_Classification_Obj_16_RL 8;
BA_ "GenSigSendType" SG_ 857 ARC_OD_AabsYStd_Obj_16_RL 8;
BA_ "GenSigSendType" SG_ 857 ARC_OD_ClassConf_Obj_16_RL 8;
BA_ "GenSigSendType" SG_ 857 ARC_OD_ProbOfExist_Obj_16_RL 8;
BA_ "GenSigSendType" SG_ 857 ARC_OD_VabsX_Obj_16_RL 8;
BA_ "GenSigSendType" SG_ 857 ARC_OD_DynProp_Obj_16_RL 8;
BA_ "GenSigSendType" SG_ 857 ARC_OD_Length_Obj_16_RL 8;
BA_ "GenSigSendType" SG_ 857 ARC_OD_MaintenanceState_Obj_0077 8;
BA_ "GenSigSendType" SG_ 857 ARC_OD_Width_Obj_16_RL 8;
BA_ "GenSigSendType" SG_ 857 ARC_OD_RCS_Obj_16_RL 8;
BA_ "GenSigSendType" SG_ 857 ARC_OD_Orientation_Obj_16_RL 8;
BA_ "GenSigSendType" SG_ 857 ARC_OD_LifeCycle_Obj_16_RL 8;
BA_ "GenSigSendType" SG_ 857 ARC_OD_DistX_Obj_17_RL 8;
BA_ "GenSigSendType" SG_ 857 ARC_OD_VabsX_Obj_17_RL 8;
BA_ "GenSigSendType" SG_ 857 ARC_OD_AabsX_Obj_17_RL 8;
BA_ "GenSigSendType" SG_ 857 ARC_OD_AabsX_Obj_16_RL 8;
BA_ "GenSigSendType" SG_ 857 ARC_OD_DistY_Obj_17_RL 8;
BA_ "GenSigSendType" SG_ 857 ARC_OD_VabsY_Obj_17_RL 8;
BA_ "GenSigSendType" SG_ 857 ARC_OD_AabsY_Obj_17_RL 8;
BA_ "GenSigSendType" SG_ 857 ARC_OD_DistXStd_Obj_17_RL 8;
BA_ "GenSigSendType" SG_ 857 ARC_OD_DistYStd_Obj_17_RL 8;
BA_ "GenSigSendType" SG_ 857 ARC_OD_VabsXStd_Obj_17_RL 8;
BA_ "GenSigSendType" SG_ 857 ARC_OD_VabsYStd_Obj_17_RL 8;
BA_ "GenSigSendType" SG_ 857 ARC_OD_AabsXStd_Obj_17_RL 8;
BA_ "GenSigSendType" SG_ 857 ARC_OD_Classification_Obj_17_RL 8;
BA_ "GenSigSendType" SG_ 857 ARC_OD_AabsYStd_Obj_17_RL 8;
BA_ "GenSigSendType" SG_ 857 ARC_OD_ClassConf_Obj_17_RL 8;
BA_ "GenSigSendType" SG_ 857 ARC_OD_DistY_Obj_16_RL 8;
BA_ "GenSigSendType" SG_ 857 ARC_OD_ProbOfExist_Obj_17_RL 8;
BA_ "GenSigSendType" SG_ 857 ARC_OD_DynProp_Obj_17_RL 8;
BA_ "GenSigSendType" SG_ 857 ARC_OD_Length_Obj_17_RL 8;
BA_ "GenSigSendType" SG_ 857 ARC_OD_MaintenanceState_Obj_0078 8;
BA_ "GenSigSendType" SG_ 857 ARC_OD_Width_Obj_17_RL 8;
BA_ "GenSigSendType" SG_ 857 ARC_OD_RCS_Obj_17_RL 8;
BA_ "GenSigSendType" SG_ 857 ARC_OD_Orientation_Obj_17_RL 8;
BA_ "GenSigSendType" SG_ 857 ARC_OD_LifeCycle_Obj_17_RL 8;
BA_ "GenSigSendType" SG_ 857 ARC_OD_ObstacleProb_Obj_16_RL 8;
BA_ "GenSigSendType" SG_ 857 ARC_OD_ObstacleProb_Obj_17_RL 8;
BA_ "GenSigSendType" SG_ 857 ARC_OD_VabsY_Obj_16_RL 8;
BA_ "GenSigSendType" SG_ 857 ARC_OD_ID_16_RL 8;
BA_ "GenSigSendType" SG_ 857 ARC_OD_ID_17_RL 8;
BA_ "GenSigSendType" SG_ 857 ARC_OD_MsgCounter_Obj_16_17_RL 8;
BA_ "GenSigSendType" SG_ 857 ARC_OD_CRC8_Obj_16_17_RL 8;
BA_ "GenSigSendType" SG_ 857 ARC_OD_AabsY_Obj_16_RL 8;
BA_ "GenSigSendType" SG_ 857 ARC_OD_DistXStd_Obj_16_RL 8;
BA_ "GenSigSendType" SG_ 857 ARC_OD_DistYStd_Obj_16_RL 8;
BA_ "GenSigSendType" SG_ 857 ARC_OD_VabsXStd_Obj_16_RL 8;
BA_ "GenSigSendType" SG_ 857 ARC_OD_VabsYStd_Obj_16_RL 8;
BA_ "GenSigSendType" SG_ 857 ARC_OD_AabsXStd_Obj_16_RL 8;
BA_ "GenSigSendType" SG_ 858 DistHeight_Obj_19_RL 8;
BA_ "GenSigSendType" SG_ 858 DistHeight_Obj_18_RL 8;
BA_ "GenSigSendType" SG_ 858 ARC_OD_DistX_Obj_18_RL 8;
BA_ "GenSigSendType" SG_ 858 ARC_OD_Classification_Obj_18_RL 8;
BA_ "GenSigSendType" SG_ 858 ARC_OD_AabsYStd_Obj_18_RL 8;
BA_ "GenSigSendType" SG_ 858 ARC_OD_ClassConf_Obj_18_RL 8;
BA_ "GenSigSendType" SG_ 858 ARC_OD_ProbOfExist_Obj_18_RL 8;
BA_ "GenSigSendType" SG_ 858 ARC_OD_VabsX_Obj_18_RL 8;
BA_ "GenSigSendType" SG_ 858 ARC_OD_DynProp_Obj_18_RL 8;
BA_ "GenSigSendType" SG_ 858 ARC_OD_Length_Obj_18_RL 8;
BA_ "GenSigSendType" SG_ 858 ARC_OD_MaintenanceState_Obj_0079 8;
BA_ "GenSigSendType" SG_ 858 ARC_OD_Width_Obj_18_RL 8;
BA_ "GenSigSendType" SG_ 858 ARC_OD_RCS_Obj_18_RL 8;
BA_ "GenSigSendType" SG_ 858 ARC_OD_Orientation_Obj_18_RL 8;
BA_ "GenSigSendType" SG_ 858 ARC_OD_LifeCycle_Obj_18_RL 8;
BA_ "GenSigSendType" SG_ 858 ARC_OD_DistX_Obj_19_RL 8;
BA_ "GenSigSendType" SG_ 858 ARC_OD_VabsX_Obj_19_RL 8;
BA_ "GenSigSendType" SG_ 858 ARC_OD_AabsX_Obj_19_RL 8;
BA_ "GenSigSendType" SG_ 858 ARC_OD_AabsX_Obj_18_RL 8;
BA_ "GenSigSendType" SG_ 858 ARC_OD_DistY_Obj_19_RL 8;
BA_ "GenSigSendType" SG_ 858 ARC_OD_VabsY_Obj_19_RL 8;
BA_ "GenSigSendType" SG_ 858 ARC_OD_AabsY_Obj_19_RL 8;
BA_ "GenSigSendType" SG_ 858 ARC_OD_DistXStd_Obj_19_RL 8;
BA_ "GenSigSendType" SG_ 858 ARC_OD_DistYStd_Obj_19_RL 8;
BA_ "GenSigSendType" SG_ 858 ARC_OD_VabsXStd_Obj_19_RL 8;
BA_ "GenSigSendType" SG_ 858 ARC_OD_VabsYStd_Obj_19_RL 8;
BA_ "GenSigSendType" SG_ 858 ARC_OD_AabsXStd_Obj_19_RL 8;
BA_ "GenSigSendType" SG_ 858 ARC_OD_Classification_Obj_19_RL 8;
BA_ "GenSigSendType" SG_ 858 ARC_OD_AabsYStd_Obj_19_RL 8;
BA_ "GenSigSendType" SG_ 858 ARC_OD_ClassConf_Obj_19_RL 8;
BA_ "GenSigSendType" SG_ 858 ARC_OD_DistY_Obj_18_RL 8;
BA_ "GenSigSendType" SG_ 858 ARC_OD_ProbOfExist_Obj_19_RL 8;
BA_ "GenSigSendType" SG_ 858 ARC_OD_DynProp_Obj_19_RL 8;
BA_ "GenSigSendType" SG_ 858 ARC_OD_Length_Obj_19_RL 8;
BA_ "GenSigSendType" SG_ 858 ARC_OD_MaintenanceState_Obj_0080 8;
BA_ "GenSigSendType" SG_ 858 ARC_OD_Width_Obj_19_RL 8;
BA_ "GenSigSendType" SG_ 858 ARC_OD_RCS_Obj_19_RL 8;
BA_ "GenSigSendType" SG_ 858 ARC_OD_Orientation_Obj_19_RL 8;
BA_ "GenSigSendType" SG_ 858 ARC_OD_LifeCycle_Obj_19_RL 8;
BA_ "GenSigSendType" SG_ 858 ARC_OD_ObstacleProb_Obj_18_RL 8;
BA_ "GenSigSendType" SG_ 858 ARC_OD_ObstacleProb_Obj_19_RL 8;
BA_ "GenSigSendType" SG_ 858 ARC_OD_VabsY_Obj_18_RL 8;
BA_ "GenSigSendType" SG_ 858 ARC_OD_ID_18_RL 8;
BA_ "GenSigSendType" SG_ 858 ARC_OD_ID_19_RL 8;
BA_ "GenSigSendType" SG_ 858 ARC_OD_MsgCounter_Obj_18_19_RL 8;
BA_ "GenSigSendType" SG_ 858 ARC_OD_CRC8_Obj_18_19_RL 8;
BA_ "GenSigSendType" SG_ 858 ARC_OD_AabsY_Obj_18_RL 8;
BA_ "GenSigSendType" SG_ 858 ARC_OD_DistXStd_Obj_18_RL 8;
BA_ "GenSigSendType" SG_ 858 ARC_OD_DistYStd_Obj_18_RL 8;
BA_ "GenSigSendType" SG_ 858 ARC_OD_VabsXStd_Obj_18_RL 8;
BA_ "GenSigSendType" SG_ 858 ARC_OD_VabsYStd_Obj_18_RL 8;
BA_ "GenSigSendType" SG_ 858 ARC_OD_AabsXStd_Obj_18_RL 8;
BA_ "GenSigSendType" SG_ 859 DistHeight_Obj_21_RL 8;
BA_ "GenSigSendType" SG_ 859 DistHeight_Obj_20_RL 8;
BA_ "GenSigSendType" SG_ 859 ARC_OD_DistX_Obj_20_RL 8;
BA_ "GenSigSendType" SG_ 859 ARC_OD_Classification_Obj_20_RL 8;
BA_ "GenSigSendType" SG_ 859 ARC_OD_AabsYStd_Obj_20_RL 8;
BA_ "GenSigSendType" SG_ 859 ARC_OD_ClassConf_Obj_20_RL 8;
BA_ "GenSigSendType" SG_ 859 ARC_OD_ProbOfExist_Obj_20_RL 8;
BA_ "GenSigSendType" SG_ 859 ARC_OD_VabsX_Obj_20_RL 8;
BA_ "GenSigSendType" SG_ 859 ARC_OD_DynProp_Obj_20_RL 8;
BA_ "GenSigSendType" SG_ 859 ARC_OD_Length_Obj_20_RL 8;
BA_ "GenSigSendType" SG_ 859 ARC_OD_MaintenanceState_Obj_0081 8;
BA_ "GenSigSendType" SG_ 859 ARC_OD_Width_Obj_20_RL 8;
BA_ "GenSigSendType" SG_ 859 ARC_OD_RCS_Obj_20_RL 8;
BA_ "GenSigSendType" SG_ 859 ARC_OD_Orientation_Obj_20_RL 8;
BA_ "GenSigSendType" SG_ 859 ARC_OD_LifeCycle_Obj_20_RL 8;
BA_ "GenSigSendType" SG_ 859 ARC_OD_DistX_Obj_21_RL 8;
BA_ "GenSigSendType" SG_ 859 ARC_OD_VabsX_Obj_21_RL 8;
BA_ "GenSigSendType" SG_ 859 ARC_OD_AabsX_Obj_21_RL 8;
BA_ "GenSigSendType" SG_ 859 ARC_OD_AabsX_Obj_20_RL 8;
BA_ "GenSigSendType" SG_ 859 ARC_OD_DistY_Obj_21_RL 8;
BA_ "GenSigSendType" SG_ 859 ARC_OD_VabsY_Obj_21_RL 8;
BA_ "GenSigSendType" SG_ 859 ARC_OD_AabsY_Obj_21_RL 8;
BA_ "GenSigSendType" SG_ 859 ARC_OD_DistXStd_Obj_21_RL 8;
BA_ "GenSigSendType" SG_ 859 ARC_OD_DistYStd_Obj_21_RL 8;
BA_ "GenSigSendType" SG_ 859 ARC_OD_VabsXStd_Obj_21_RL 8;
BA_ "GenSigSendType" SG_ 859 ARC_OD_VabsYStd_Obj_21_RL 8;
BA_ "GenSigSendType" SG_ 859 ARC_OD_AabsXStd_Obj_21_RL 8;
BA_ "GenSigSendType" SG_ 859 ARC_OD_Classification_Obj_21_RL 8;
BA_ "GenSigSendType" SG_ 859 ARC_OD_AabsYStd_Obj_21_RL 8;
BA_ "GenSigSendType" SG_ 859 ARC_OD_ClassConf_Obj_21_RL 8;
BA_ "GenSigSendType" SG_ 859 ARC_OD_DistY_Obj_20_RL 8;
BA_ "GenSigSendType" SG_ 859 ARC_OD_ProbOfExist_Obj_21_RL 8;
BA_ "GenSigSendType" SG_ 859 ARC_OD_DynProp_Obj_21_RL 8;
BA_ "GenSigSendType" SG_ 859 ARC_OD_Length_Obj_21_RL 8;
BA_ "GenSigSendType" SG_ 859 ARC_OD_MaintenanceState_Obj_0082 8;
BA_ "GenSigSendType" SG_ 859 ARC_OD_Width_Obj_21_RL 8;
BA_ "GenSigSendType" SG_ 859 ARC_OD_RCS_Obj_21_RL 8;
BA_ "GenSigSendType" SG_ 859 ARC_OD_Orientation_Obj_21_RL 8;
BA_ "GenSigSendType" SG_ 859 ARC_OD_LifeCycle_Obj_21_RL 8;
BA_ "GenSigSendType" SG_ 859 ARC_OD_ObstacleProb_Obj_20_RL 8;
BA_ "GenSigSendType" SG_ 859 ARC_OD_ObstacleProb_Obj_21_RL 8;
BA_ "GenSigSendType" SG_ 859 ARC_OD_VabsY_Obj_20_RL 8;
BA_ "GenSigSendType" SG_ 859 ARC_OD_ID_20_RL 8;
BA_ "GenSigSendType" SG_ 859 ARC_OD_ID_21_RL 8;
BA_ "GenSigSendType" SG_ 859 ARC_OD_MsgCounter_Obj_20_21_RL 8;
BA_ "GenSigSendType" SG_ 859 ARC_OD_CRC8_Obj_20_21_RL 8;
BA_ "GenSigSendType" SG_ 859 ARC_OD_AabsY_Obj_20_RL 8;
BA_ "GenSigSendType" SG_ 859 ARC_OD_DistXStd_Obj_20_RL 8;
BA_ "GenSigSendType" SG_ 859 ARC_OD_DistYStd_Obj_20_RL 8;
BA_ "GenSigSendType" SG_ 859 ARC_OD_VabsXStd_Obj_20_RL 8;
BA_ "GenSigSendType" SG_ 859 ARC_OD_VabsYStd_Obj_20_RL 8;
BA_ "GenSigSendType" SG_ 859 ARC_OD_AabsXStd_Obj_20_RL 8;
BA_ "GenSigSendType" SG_ 860 DistHeight_Obj_23_RL 8;
BA_ "GenSigSendType" SG_ 860 DistHeight_Obj_22_RL 8;
BA_ "GenSigSendType" SG_ 860 ARC_OD_DistX_Obj_22_RL 8;
BA_ "GenSigSendType" SG_ 860 ARC_OD_Classification_Obj_22_RL 8;
BA_ "GenSigSendType" SG_ 860 ARC_OD_AabsYStd_Obj_22_RL 8;
BA_ "GenSigSendType" SG_ 860 ARC_OD_ClassConf_Obj_22_RL 8;
BA_ "GenSigSendType" SG_ 860 ARC_OD_ProbOfExist_Obj_22_RL 8;
BA_ "GenSigSendType" SG_ 860 ARC_OD_VabsX_Obj_22_RL 8;
BA_ "GenSigSendType" SG_ 860 ARC_OD_DynProp_Obj_22_RL 8;
BA_ "GenSigSendType" SG_ 860 ARC_OD_Length_Obj_22_RL 8;
BA_ "GenSigSendType" SG_ 860 ARC_OD_MaintenanceState_Obj_0083 8;
BA_ "GenSigSendType" SG_ 860 ARC_OD_Width_Obj_22_RL 8;
BA_ "GenSigSendType" SG_ 860 ARC_OD_RCS_Obj_22_RL 8;
BA_ "GenSigSendType" SG_ 860 ARC_OD_Orientation_Obj_22_RL 8;
BA_ "GenSigSendType" SG_ 860 ARC_OD_LifeCycle_Obj_22_RL 8;
BA_ "GenSigSendType" SG_ 860 ARC_OD_DistX_Obj_23_RL 8;
BA_ "GenSigSendType" SG_ 860 ARC_OD_VabsX_Obj_23_RL 8;
BA_ "GenSigSendType" SG_ 860 ARC_OD_AabsX_Obj_23_RL 8;
BA_ "GenSigSendType" SG_ 860 ARC_OD_AabsX_Obj_22_RL 8;
BA_ "GenSigSendType" SG_ 860 ARC_OD_DistY_Obj_23_RL 8;
BA_ "GenSigSendType" SG_ 860 ARC_OD_VabsY_Obj_23_RL 8;
BA_ "GenSigSendType" SG_ 860 ARC_OD_AabsY_Obj_23_RL 8;
BA_ "GenSigSendType" SG_ 860 ARC_OD_DistXStd_Obj_23_RL 8;
BA_ "GenSigSendType" SG_ 860 ARC_OD_DistYStd_Obj_23_RL 8;
BA_ "GenSigSendType" SG_ 860 ARC_OD_VabsXStd_Obj_23_RL 8;
BA_ "GenSigSendType" SG_ 860 ARC_OD_VabsYStd_Obj_23_RL 8;
BA_ "GenSigSendType" SG_ 860 ARC_OD_AabsXStd_Obj_23_RL 8;
BA_ "GenSigSendType" SG_ 860 ARC_OD_Classification_Obj_23_RL 8;
BA_ "GenSigSendType" SG_ 860 ARC_OD_AabsYStd_Obj_23_RL 8;
BA_ "GenSigSendType" SG_ 860 ARC_OD_ClassConf_Obj_23_RL 8;
BA_ "GenSigSendType" SG_ 860 ARC_OD_DistY_Obj_22_RL 8;
BA_ "GenSigSendType" SG_ 860 ARC_OD_ProbOfExist_Obj_23_RL 8;
BA_ "GenSigSendType" SG_ 860 ARC_OD_DynProp_Obj_23_RL 8;
BA_ "GenSigSendType" SG_ 860 ARC_OD_Length_Obj_23_RL 8;
BA_ "GenSigSendType" SG_ 860 ARC_OD_MaintenanceState_Obj_0084 8;
BA_ "GenSigSendType" SG_ 860 ARC_OD_Width_Obj_23_RL 8;
BA_ "GenSigSendType" SG_ 860 ARC_OD_RCS_Obj_23_RL 8;
BA_ "GenSigSendType" SG_ 860 ARC_OD_Orientation_Obj_23_RL 8;
BA_ "GenSigSendType" SG_ 860 ARC_OD_LifeCycle_Obj_23_RL 8;
BA_ "GenSigSendType" SG_ 860 ARC_OD_ObstacleProb_Obj_22_RL 8;
BA_ "GenSigSendType" SG_ 860 ARC_OD_ObstacleProb_Obj_23_RL 8;
BA_ "GenSigSendType" SG_ 860 ARC_OD_VabsY_Obj_22_RL 8;
BA_ "GenSigSendType" SG_ 860 ARC_OD_ID_22_RL 8;
BA_ "GenSigSendType" SG_ 860 ARC_OD_ID_23_RL 8;
BA_ "GenSigSendType" SG_ 860 ARC_OD_MsgCounter_Obj_22_23_RL 8;
BA_ "GenSigSendType" SG_ 860 ARC_OD_CRC8_Obj_22_23_RL 8;
BA_ "GenSigSendType" SG_ 860 ARC_OD_AabsY_Obj_22_RL 8;
BA_ "GenSigSendType" SG_ 860 ARC_OD_DistXStd_Obj_22_RL 8;
BA_ "GenSigSendType" SG_ 860 ARC_OD_DistYStd_Obj_22_RL 8;
BA_ "GenSigSendType" SG_ 860 ARC_OD_VabsXStd_Obj_22_RL 8;
BA_ "GenSigSendType" SG_ 860 ARC_OD_VabsYStd_Obj_22_RL 8;
BA_ "GenSigSendType" SG_ 860 ARC_OD_AabsXStd_Obj_22_RL 8;
BA_ "GenSigSendType" SG_ 861 DistHeight_Obj_25_RL 8;
BA_ "GenSigSendType" SG_ 861 DistHeight_Obj_24_RL 8;
BA_ "GenSigSendType" SG_ 861 ARC_OD_DistX_Obj_24_RL 8;
BA_ "GenSigSendType" SG_ 861 ARC_OD_Classification_Obj_24_RL 8;
BA_ "GenSigSendType" SG_ 861 ARC_OD_AabsYStd_Obj_24_RL 8;
BA_ "GenSigSendType" SG_ 861 ARC_OD_ClassConf_Obj_24_RL 8;
BA_ "GenSigSendType" SG_ 861 ARC_OD_ProbOfExist_Obj_24_RL 8;
BA_ "GenSigSendType" SG_ 861 ARC_OD_VabsX_Obj_24_RL 8;
BA_ "GenSigSendType" SG_ 861 ARC_OD_DynProp_Obj_24_RL 8;
BA_ "GenSigSendType" SG_ 861 ARC_OD_Length_Obj_24_RL 8;
BA_ "GenSigSendType" SG_ 861 ARC_OD_MaintenanceState_Obj_0085 8;
BA_ "GenSigSendType" SG_ 861 ARC_OD_Width_Obj_24_RL 8;
BA_ "GenSigSendType" SG_ 861 ARC_OD_RCS_Obj_24_RL 8;
BA_ "GenSigSendType" SG_ 861 ARC_OD_Orientation_Obj_24_RL 8;
BA_ "GenSigSendType" SG_ 861 ARC_OD_LifeCycle_Obj_24_RL 8;
BA_ "GenSigSendType" SG_ 861 ARC_OD_DistX_Obj_25_RL 8;
BA_ "GenSigSendType" SG_ 861 ARC_OD_VabsX_Obj_25_RL 8;
BA_ "GenSigSendType" SG_ 861 ARC_OD_AabsX_Obj_25_RL 8;
BA_ "GenSigSendType" SG_ 861 ARC_OD_AabsX_Obj_24_RL 8;
BA_ "GenSigSendType" SG_ 861 ARC_OD_DistY_Obj_25_RL 8;
BA_ "GenSigSendType" SG_ 861 ARC_OD_VabsY_Obj_25_RL 8;
BA_ "GenSigSendType" SG_ 861 ARC_OD_AabsY_Obj_25_RL 8;
BA_ "GenSigSendType" SG_ 861 ARC_OD_DistXStd_Obj_25_RL 8;
BA_ "GenSigSendType" SG_ 861 ARC_OD_DistYStd_Obj_25_RL 8;
BA_ "GenSigSendType" SG_ 861 ARC_OD_VabsXStd_Obj_25_RL 8;
BA_ "GenSigSendType" SG_ 861 ARC_OD_VabsYStd_Obj_25_RL 8;
BA_ "GenSigSendType" SG_ 861 ARC_OD_AabsXStd_Obj_25_RL 8;
BA_ "GenSigSendType" SG_ 861 ARC_OD_Classification_Obj_25_RL 8;
BA_ "GenSigSendType" SG_ 861 ARC_OD_AabsYStd_Obj_25_RL 8;
BA_ "GenSigSendType" SG_ 861 ARC_OD_ClassConf_Obj_25_RL 8;
BA_ "GenSigSendType" SG_ 861 ARC_OD_DistY_Obj_24_RL 8;
BA_ "GenSigSendType" SG_ 861 ARC_OD_ProbOfExist_Obj_25_RL 8;
BA_ "GenSigSendType" SG_ 861 ARC_OD_DynProp_Obj_25_RL 8;
BA_ "GenSigSendType" SG_ 861 ARC_OD_Length_Obj_25_RL 8;
BA_ "GenSigSendType" SG_ 861 ARC_OD_MaintenanceState_Obj_0086 8;
BA_ "GenSigSendType" SG_ 861 ARC_OD_Width_Obj_25_RL 8;
BA_ "GenSigSendType" SG_ 861 ARC_OD_RCS_Obj_25_RL 8;
BA_ "GenSigSendType" SG_ 861 ARC_OD_Orientation_Obj_25_RL 8;
BA_ "GenSigSendType" SG_ 861 ARC_OD_LifeCycle_Obj_25_RL 8;
BA_ "GenSigSendType" SG_ 861 ARC_OD_ObstacleProb_Obj_24_RL 8;
BA_ "GenSigSendType" SG_ 861 ARC_OD_ObstacleProb_Obj_25_RL 8;
BA_ "GenSigSendType" SG_ 861 ARC_OD_VabsY_Obj_24_RL 8;
BA_ "GenSigSendType" SG_ 861 ARC_OD_ID_24_RL 8;
BA_ "GenSigSendType" SG_ 861 ARC_OD_ID_25_RL 8;
BA_ "GenSigSendType" SG_ 861 ARC_OD_MsgCounter_Obj_24_25_RL 8;
BA_ "GenSigSendType" SG_ 861 ARC_OD_CRC8_Obj_24_25_RL 8;
BA_ "GenSigSendType" SG_ 861 ARC_OD_AabsY_Obj_24_RL 8;
BA_ "GenSigSendType" SG_ 861 ARC_OD_DistXStd_Obj_24_RL 8;
BA_ "GenSigSendType" SG_ 861 ARC_OD_DistYStd_Obj_24_RL 8;
BA_ "GenSigSendType" SG_ 861 ARC_OD_VabsXStd_Obj_24_RL 8;
BA_ "GenSigSendType" SG_ 861 ARC_OD_VabsYStd_Obj_24_RL 8;
BA_ "GenSigSendType" SG_ 861 ARC_OD_AabsXStd_Obj_24_RL 8;
BA_ "GenSigSendType" SG_ 862 DistHeight_Obj_27_RL 8;
BA_ "GenSigSendType" SG_ 862 DistHeight_Obj_26_RL 8;
BA_ "GenSigSendType" SG_ 862 ARC_OD_DistX_Obj_26_RL 8;
BA_ "GenSigSendType" SG_ 862 ARC_OD_Classification_Obj_26_RL 8;
BA_ "GenSigSendType" SG_ 862 ARC_OD_AabsYStd_Obj_26_RL 8;
BA_ "GenSigSendType" SG_ 862 ARC_OD_ClassConf_Obj_26_RL 8;
BA_ "GenSigSendType" SG_ 862 ARC_OD_ProbOfExist_Obj_26_RL 8;
BA_ "GenSigSendType" SG_ 862 ARC_OD_VabsX_Obj_26_RL 8;
BA_ "GenSigSendType" SG_ 862 ARC_OD_DynProp_Obj_26_RL 8;
BA_ "GenSigSendType" SG_ 862 ARC_OD_Length_Obj_26_RL 8;
BA_ "GenSigSendType" SG_ 862 ARC_OD_MaintenanceState_Obj_0087 8;
BA_ "GenSigSendType" SG_ 862 ARC_OD_Width_Obj_26_RL 8;
BA_ "GenSigSendType" SG_ 862 ARC_OD_RCS_Obj_26_RL 8;
BA_ "GenSigSendType" SG_ 862 ARC_OD_Orientation_Obj_26_RL 8;
BA_ "GenSigSendType" SG_ 862 ARC_OD_LifeCycle_Obj_26_RL 8;
BA_ "GenSigSendType" SG_ 862 ARC_OD_DistX_Obj_27_RL 8;
BA_ "GenSigSendType" SG_ 862 ARC_OD_VabsX_Obj_27_RL 8;
BA_ "GenSigSendType" SG_ 862 ARC_OD_AabsX_Obj_27_RL 8;
BA_ "GenSigSendType" SG_ 862 ARC_OD_AabsX_Obj_26_RL 8;
BA_ "GenSigSendType" SG_ 862 ARC_OD_DistY_Obj_27_RL 8;
BA_ "GenSigSendType" SG_ 862 ARC_OD_VabsY_Obj_27_RL 8;
BA_ "GenSigSendType" SG_ 862 ARC_OD_AabsY_Obj_27_RL 8;
BA_ "GenSigSendType" SG_ 862 ARC_OD_DistXStd_Obj_27_RL 8;
BA_ "GenSigSendType" SG_ 862 ARC_OD_DistYStd_Obj_27_RL 8;
BA_ "GenSigSendType" SG_ 862 ARC_OD_VabsXStd_Obj_27_RL 8;
BA_ "GenSigSendType" SG_ 862 ARC_OD_VabsYStd_Obj_27_RL 8;
BA_ "GenSigSendType" SG_ 862 ARC_OD_AabsXStd_Obj_27_RL 8;
BA_ "GenSigSendType" SG_ 862 ARC_OD_Classification_Obj_27_RL 8;
BA_ "GenSigSendType" SG_ 862 ARC_OD_AabsYStd_Obj_27_RL 8;
BA_ "GenSigSendType" SG_ 862 ARC_OD_ClassConf_Obj_27_RL 8;
BA_ "GenSigSendType" SG_ 862 ARC_OD_DistY_Obj_26_RL 8;
BA_ "GenSigSendType" SG_ 862 ARC_OD_ProbOfExist_Obj_27_RL 8;
BA_ "GenSigSendType" SG_ 862 ARC_OD_DynProp_Obj_27_RL 8;
BA_ "GenSigSendType" SG_ 862 ARC_OD_Length_Obj_27_RL 8;
BA_ "GenSigSendType" SG_ 862 ARC_OD_MaintenanceState_Obj_0088 8;
BA_ "GenSigSendType" SG_ 862 ARC_OD_Width_Obj_27_RL 8;
BA_ "GenSigSendType" SG_ 862 ARC_OD_RCS_Obj_27_RL 8;
BA_ "GenSigSendType" SG_ 862 ARC_OD_Orientation_Obj_27_RL 8;
BA_ "GenSigSendType" SG_ 862 ARC_OD_LifeCycle_Obj_27_RL 8;
BA_ "GenSigSendType" SG_ 862 ARC_OD_ObstacleProb_Obj_26_RL 8;
BA_ "GenSigSendType" SG_ 862 ARC_OD_ObstacleProb_Obj_27_RL 8;
BA_ "GenSigSendType" SG_ 862 ARC_OD_VabsY_Obj_26_RL 8;
BA_ "GenSigSendType" SG_ 862 ARC_OD_ID_26_RL 8;
BA_ "GenSigSendType" SG_ 862 ARC_OD_ID_27_RL 8;
BA_ "GenSigSendType" SG_ 862 ARC_OD_MsgCounter_Obj_26_27_RL 8;
BA_ "GenSigSendType" SG_ 862 ARC_OD_CRC8_Obj_26_27_RL 8;
BA_ "GenSigSendType" SG_ 862 ARC_OD_AabsY_Obj_26_RL 8;
BA_ "GenSigSendType" SG_ 862 ARC_OD_DistXStd_Obj_26_RL 8;
BA_ "GenSigSendType" SG_ 862 ARC_OD_DistYStd_Obj_26_RL 8;
BA_ "GenSigSendType" SG_ 862 ARC_OD_VabsXStd_Obj_26_RL 8;
BA_ "GenSigSendType" SG_ 862 ARC_OD_VabsYStd_Obj_26_RL 8;
BA_ "GenSigSendType" SG_ 862 ARC_OD_AabsXStd_Obj_26_RL 8;
BA_ "GenSigSendType" SG_ 863 DistHeight_Obj_29_RL 8;
BA_ "GenSigSendType" SG_ 863 DistHeight_Obj_28_RL 8;
BA_ "GenSigSendType" SG_ 863 ARC_OD_DistX_Obj_28_RL 8;
BA_ "GenSigSendType" SG_ 863 ARC_OD_Classification_Obj_28_RL 8;
BA_ "GenSigSendType" SG_ 863 ARC_OD_AabsYStd_Obj_28_RL 8;
BA_ "GenSigSendType" SG_ 863 ARC_OD_ClassConf_Obj_28_RL 8;
BA_ "GenSigSendType" SG_ 863 ARC_OD_ProbOfExist_Obj_28_RL 8;
BA_ "GenSigSendType" SG_ 863 ARC_OD_VabsX_Obj_28_RL 8;
BA_ "GenSigSendType" SG_ 863 ARC_OD_DynProp_Obj_28_RL 8;
BA_ "GenSigSendType" SG_ 863 ARC_OD_Length_Obj_28_RL 8;
BA_ "GenSigSendType" SG_ 863 ARC_OD_MaintenanceState_Obj_0089 8;
BA_ "GenSigSendType" SG_ 863 ARC_OD_Width_Obj_28_RL 8;
BA_ "GenSigSendType" SG_ 863 ARC_OD_RCS_Obj_28_RL 8;
BA_ "GenSigSendType" SG_ 863 ARC_OD_Orientation_Obj_28_RL 8;
BA_ "GenSigSendType" SG_ 863 ARC_OD_LifeCycle_Obj_28_RL 8;
BA_ "GenSigSendType" SG_ 863 ARC_OD_DistX_Obj_29_RL 8;
BA_ "GenSigSendType" SG_ 863 ARC_OD_VabsX_Obj_29_RL 8;
BA_ "GenSigSendType" SG_ 863 ARC_OD_AabsX_Obj_29_RL 8;
BA_ "GenSigSendType" SG_ 863 ARC_OD_AabsX_Obj_28_RL 8;
BA_ "GenSigSendType" SG_ 863 ARC_OD_DistY_Obj_29_RL 8;
BA_ "GenSigSendType" SG_ 863 ARC_OD_VabsY_Obj_29_RL 8;
BA_ "GenSigSendType" SG_ 863 ARC_OD_AabsY_Obj_29_RL 8;
BA_ "GenSigSendType" SG_ 863 ARC_OD_DistXStd_Obj_29_RL 8;
BA_ "GenSigSendType" SG_ 863 ARC_OD_DistYStd_Obj_29_RL 8;
BA_ "GenSigSendType" SG_ 863 ARC_OD_VabsXStd_Obj_29_RL 8;
BA_ "GenSigSendType" SG_ 863 ARC_OD_VabsYStd_Obj_29_RL 8;
BA_ "GenSigSendType" SG_ 863 ARC_OD_AabsXStd_Obj_29_RL 8;
BA_ "GenSigSendType" SG_ 863 ARC_OD_Classification_Obj_29_RL 8;
BA_ "GenSigSendType" SG_ 863 ARC_OD_AabsYStd_Obj_29_RL 8;
BA_ "GenSigSendType" SG_ 863 ARC_OD_ClassConf_Obj_29_RL 8;
BA_ "GenSigSendType" SG_ 863 ARC_OD_DistY_Obj_28_RL 8;
BA_ "GenSigSendType" SG_ 863 ARC_OD_ProbOfExist_Obj_29_RL 8;
BA_ "GenSigSendType" SG_ 863 ARC_OD_DynProp_Obj_29_RL 8;
BA_ "GenSigSendType" SG_ 863 ARC_OD_Length_Obj_29_RL 8;
BA_ "GenSigSendType" SG_ 863 ARC_OD_MaintenanceState_Obj_0090 8;
BA_ "GenSigSendType" SG_ 863 ARC_OD_Width_Obj_29_RL 8;
BA_ "GenSigSendType" SG_ 863 ARC_OD_RCS_Obj_29_RL 8;
BA_ "GenSigSendType" SG_ 863 ARC_OD_Orientation_Obj_29_RL 8;
BA_ "GenSigSendType" SG_ 863 ARC_OD_LifeCycle_Obj_29_RL 8;
BA_ "GenSigSendType" SG_ 863 ARC_OD_ObstacleProb_Obj_28_RL 8;
BA_ "GenSigSendType" SG_ 863 ARC_OD_ObstacleProb_Obj_29_RL 8;
BA_ "GenSigSendType" SG_ 863 ARC_OD_VabsY_Obj_28_RL 8;
BA_ "GenSigSendType" SG_ 863 ARC_OD_ID_28_RL 8;
BA_ "GenSigSendType" SG_ 863 ARC_OD_ID_29_RL 8;
BA_ "GenSigSendType" SG_ 863 ARC_OD_MsgCounter_Obj_28_29_RL 8;
BA_ "GenSigSendType" SG_ 863 ARC_OD_CRC8_Obj_28_29_RL 8;
BA_ "GenSigSendType" SG_ 863 ARC_OD_AabsY_Obj_28_RL 8;
BA_ "GenSigSendType" SG_ 863 ARC_OD_DistXStd_Obj_28_RL 8;
BA_ "GenSigSendType" SG_ 863 ARC_OD_DistYStd_Obj_28_RL 8;
BA_ "GenSigSendType" SG_ 863 ARC_OD_VabsXStd_Obj_28_RL 8;
BA_ "GenSigSendType" SG_ 863 ARC_OD_VabsYStd_Obj_28_RL 8;
BA_ "GenSigSendType" SG_ 863 ARC_OD_AabsXStd_Obj_28_RL 8;
BA_ "GenSigSendType" SG_ 864 DistHeight_Obj_31_RL 8;
BA_ "GenSigSendType" SG_ 864 DistHeight_Obj_30_RL 8;
BA_ "GenSigSendType" SG_ 864 ARC_OD_DistX_Obj_30_RL 8;
BA_ "GenSigSendType" SG_ 864 ARC_OD_Classification_Obj_30_RL 8;
BA_ "GenSigSendType" SG_ 864 ARC_OD_AabsYStd_Obj_30_RL 8;
BA_ "GenSigSendType" SG_ 864 ARC_OD_ClassConf_Obj_30_RL 8;
BA_ "GenSigSendType" SG_ 864 ARC_OD_ProbOfExist_Obj_30_RL 8;
BA_ "GenSigSendType" SG_ 864 ARC_OD_VabsX_Obj_30_RL 8;
BA_ "GenSigSendType" SG_ 864 ARC_OD_DynProp_Obj_30_RL 8;
BA_ "GenSigSendType" SG_ 864 ARC_OD_Length_Obj_30_RL 8;
BA_ "GenSigSendType" SG_ 864 ARC_OD_MaintenanceState_Obj_0091 8;
BA_ "GenSigSendType" SG_ 864 ARC_OD_Width_Obj_30_RL 8;
BA_ "GenSigSendType" SG_ 864 ARC_OD_RCS_Obj_30_RL 8;
BA_ "GenSigSendType" SG_ 864 ARC_OD_Orientation_Obj_30_RL 8;
BA_ "GenSigSendType" SG_ 864 ARC_OD_LifeCycle_Obj_30_RL 8;
BA_ "GenSigSendType" SG_ 864 ARC_OD_DistX_Obj_31_RL 8;
BA_ "GenSigSendType" SG_ 864 ARC_OD_VabsX_Obj_31_RL 8;
BA_ "GenSigSendType" SG_ 864 ARC_OD_AabsX_Obj_31_RL 8;
BA_ "GenSigSendType" SG_ 864 ARC_OD_AabsX_Obj_30_RL 8;
BA_ "GenSigSendType" SG_ 864 ARC_OD_DistY_Obj_31_RL 8;
BA_ "GenSigSendType" SG_ 864 ARC_OD_VabsY_Obj_31_RL 8;
BA_ "GenSigSendType" SG_ 864 ARC_OD_AabsY_Obj_31_RL 8;
BA_ "GenSigSendType" SG_ 864 ARC_OD_DistXStd_Obj_31_RL 8;
BA_ "GenSigSendType" SG_ 864 ARC_OD_DistYStd_Obj_31_RL 8;
BA_ "GenSigSendType" SG_ 864 ARC_OD_VabsXStd_Obj_31_RL 8;
BA_ "GenSigSendType" SG_ 864 ARC_OD_VabsYStd_Obj_31_RL 8;
BA_ "GenSigSendType" SG_ 864 ARC_OD_AabsXStd_Obj_31_RL 8;
BA_ "GenSigSendType" SG_ 864 ARC_OD_Classification_Obj_31_RL 8;
BA_ "GenSigSendType" SG_ 864 ARC_OD_AabsYStd_Obj_31_RL 8;
BA_ "GenSigSendType" SG_ 864 ARC_OD_ClassConf_Obj_31_RL 8;
BA_ "GenSigSendType" SG_ 864 ARC_OD_DistY_Obj_30_RL 8;
BA_ "GenSigSendType" SG_ 864 ARC_OD_ProbOfExist_Obj_31_RL 8;
BA_ "GenSigSendType" SG_ 864 ARC_OD_DynProp_Obj_31_RL 8;
BA_ "GenSigSendType" SG_ 864 ARC_OD_Length_Obj_31_RL 8;
BA_ "GenSigSendType" SG_ 864 ARC_OD_MaintenanceState_Obj_0092 8;
BA_ "GenSigSendType" SG_ 864 ARC_OD_Width_Obj_31_RL 8;
BA_ "GenSigSendType" SG_ 864 ARC_OD_RCS_Obj_31_RL 8;
BA_ "GenSigSendType" SG_ 864 ARC_OD_Orientation_Obj_31_RL 8;
BA_ "GenSigSendType" SG_ 864 ARC_OD_LifeCycle_Obj_31_RL 8;
BA_ "GenSigSendType" SG_ 864 ARC_OD_ObstacleProb_Obj_30_RL 8;
BA_ "GenSigSendType" SG_ 864 ARC_OD_ObstacleProb_Obj_31_RL 8;
BA_ "GenSigSendType" SG_ 864 ARC_OD_VabsY_Obj_30_RL 8;
BA_ "GenSigSendType" SG_ 864 ARC_OD_ID_30_RL 8;
BA_ "GenSigSendType" SG_ 864 ARC_OD_ID_31_RL 8;
BA_ "GenSigSendType" SG_ 864 ARC_OD_MsgCounter_Obj_30_31_RL 8;
BA_ "GenSigSendType" SG_ 864 ARC_OD_CRC8_Obj_30_31_RL 8;
BA_ "GenSigSendType" SG_ 864 ARC_OD_AabsY_Obj_30_RL 8;
BA_ "GenSigSendType" SG_ 864 ARC_OD_DistXStd_Obj_30_RL 8;
BA_ "GenSigSendType" SG_ 864 ARC_OD_DistYStd_Obj_30_RL 8;
BA_ "GenSigSendType" SG_ 864 ARC_OD_VabsXStd_Obj_30_RL 8;
BA_ "GenSigSendType" SG_ 864 ARC_OD_VabsYStd_Obj_30_RL 8;
BA_ "GenSigSendType" SG_ 864 ARC_OD_AabsXStd_Obj_30_RL 8;
BA_ "GenSigSendType" SG_ 865 DistHeight_Obj_33_RL 8;
BA_ "GenSigSendType" SG_ 865 DistHeight_Obj_32_RL 8;
BA_ "GenSigSendType" SG_ 865 ARC_OD_DistX_Obj_32_RL 8;
BA_ "GenSigSendType" SG_ 865 ARC_OD_Classification_Obj_32_RL 8;
BA_ "GenSigSendType" SG_ 865 ARC_OD_AabsYStd_Obj_32_RL 8;
BA_ "GenSigSendType" SG_ 865 ARC_OD_ClassConf_Obj_32_RL 8;
BA_ "GenSigSendType" SG_ 865 ARC_OD_ProbOfExist_Obj_32_RL 8;
BA_ "GenSigSendType" SG_ 865 ARC_OD_VabsX_Obj_32_RL 8;
BA_ "GenSigSendType" SG_ 865 ARC_OD_DynProp_Obj_32_RL 8;
BA_ "GenSigSendType" SG_ 865 ARC_OD_Length_Obj_32_RL 8;
BA_ "GenSigSendType" SG_ 865 ARC_OD_MaintenanceState_Obj_0093 8;
BA_ "GenSigSendType" SG_ 865 ARC_OD_Width_Obj_32_RL 8;
BA_ "GenSigSendType" SG_ 865 ARC_OD_RCS_Obj_32_RL 8;
BA_ "GenSigSendType" SG_ 865 ARC_OD_Orientation_Obj_32_RL 8;
BA_ "GenSigSendType" SG_ 865 ARC_OD_LifeCycle_Obj_32_RL 8;
BA_ "GenSigSendType" SG_ 865 ARC_OD_DistX_Obj_33_RL 8;
BA_ "GenSigSendType" SG_ 865 ARC_OD_VabsX_Obj_33_RL 8;
BA_ "GenSigSendType" SG_ 865 ARC_OD_AabsX_Obj_33_RL 8;
BA_ "GenSigSendType" SG_ 865 ARC_OD_AabsX_Obj_32_RL 8;
BA_ "GenSigSendType" SG_ 865 ARC_OD_DistY_Obj_33_RL 8;
BA_ "GenSigSendType" SG_ 865 ARC_OD_VabsY_Obj_33_RL 8;
BA_ "GenSigSendType" SG_ 865 ARC_OD_AabsY_Obj_33_RL 8;
BA_ "GenSigSendType" SG_ 865 ARC_OD_DistXStd_Obj_33_RL 8;
BA_ "GenSigSendType" SG_ 865 ARC_OD_DistYStd_Obj_33_RL 8;
BA_ "GenSigSendType" SG_ 865 ARC_OD_VabsXStd_Obj_33_RL 8;
BA_ "GenSigSendType" SG_ 865 ARC_OD_VabsYStd_Obj_33_RL 8;
BA_ "GenSigSendType" SG_ 865 ARC_OD_AabsXStd_Obj_33_RL 8;
BA_ "GenSigSendType" SG_ 865 ARC_OD_Classification_Obj_33_RL 8;
BA_ "GenSigSendType" SG_ 865 ARC_OD_AabsYStd_Obj_33_RL 8;
BA_ "GenSigSendType" SG_ 865 ARC_OD_ClassConf_Obj_33_RL 8;
BA_ "GenSigSendType" SG_ 865 ARC_OD_DistY_Obj_32_RL 8;
BA_ "GenSigSendType" SG_ 865 ARC_OD_ProbOfExist_Obj_33_RL 8;
BA_ "GenSigSendType" SG_ 865 ARC_OD_DynProp_Obj_33_RL 8;
BA_ "GenSigSendType" SG_ 865 ARC_OD_Length_Obj_33_RL 8;
BA_ "GenSigSendType" SG_ 865 ARC_OD_MaintenanceState_Obj_0094 8;
BA_ "GenSigSendType" SG_ 865 ARC_OD_Width_Obj_33_RL 8;
BA_ "GenSigSendType" SG_ 865 ARC_OD_RCS_Obj_33_RL 8;
BA_ "GenSigSendType" SG_ 865 ARC_OD_Orientation_Obj_33_RL 8;
BA_ "GenSigSendType" SG_ 865 ARC_OD_LifeCycle_Obj_33_RL 8;
BA_ "GenSigSendType" SG_ 865 ARC_OD_ObstacleProb_Obj_32_RL 8;
BA_ "GenSigSendType" SG_ 865 ARC_OD_ObstacleProb_Obj_33_RL 8;
BA_ "GenSigSendType" SG_ 865 ARC_OD_VabsY_Obj_32_RL 8;
BA_ "GenSigSendType" SG_ 865 ARC_OD_ID_32_RL 8;
BA_ "GenSigSendType" SG_ 865 ARC_OD_ID_33_RL 8;
BA_ "GenSigSendType" SG_ 865 ARC_OD_MsgCounter_Obj_32_33_RL 8;
BA_ "GenSigSendType" SG_ 865 ARC_OD_CRC8_Obj_32_33_RL 8;
BA_ "GenSigSendType" SG_ 865 ARC_OD_AabsY_Obj_32_RL 8;
BA_ "GenSigSendType" SG_ 865 ARC_OD_DistXStd_Obj_32_RL 8;
BA_ "GenSigSendType" SG_ 865 ARC_OD_DistYStd_Obj_32_RL 8;
BA_ "GenSigSendType" SG_ 865 ARC_OD_VabsXStd_Obj_32_RL 8;
BA_ "GenSigSendType" SG_ 865 ARC_OD_VabsYStd_Obj_32_RL 8;
BA_ "GenSigSendType" SG_ 865 ARC_OD_AabsXStd_Obj_32_RL 8;
BA_ "GenSigSendType" SG_ 866 DistHeight_Obj_35_RL 8;
BA_ "GenSigSendType" SG_ 866 DistHeight_Obj_34_RL 8;
BA_ "GenSigSendType" SG_ 866 ARC_OD_DistX_Obj_34_RL 8;
BA_ "GenSigSendType" SG_ 866 ARC_OD_Classification_Obj_34_RL 8;
BA_ "GenSigSendType" SG_ 866 ARC_OD_AabsYStd_Obj_34_RL 8;
BA_ "GenSigSendType" SG_ 866 ARC_OD_ClassConf_Obj_34_RL 8;
BA_ "GenSigSendType" SG_ 866 ARC_OD_ProbOfExist_Obj_34_RL 8;
BA_ "GenSigSendType" SG_ 866 ARC_OD_VabsX_Obj_34_RL 8;
BA_ "GenSigSendType" SG_ 866 ARC_OD_DynProp_Obj_34_RL 8;
BA_ "GenSigSendType" SG_ 866 ARC_OD_Length_Obj_34_RL 8;
BA_ "GenSigSendType" SG_ 866 ARC_OD_MaintenanceState_Obj_0095 8;
BA_ "GenSigSendType" SG_ 866 ARC_OD_Width_Obj_34_RL 8;
BA_ "GenSigSendType" SG_ 866 ARC_OD_RCS_Obj_34_RL 8;
BA_ "GenSigSendType" SG_ 866 ARC_OD_Orientation_Obj_34_RL 8;
BA_ "GenSigSendType" SG_ 866 ARC_OD_LifeCycle_Obj_34_RL 8;
BA_ "GenSigSendType" SG_ 866 ARC_OD_DistX_Obj_35_RL 8;
BA_ "GenSigSendType" SG_ 866 ARC_OD_VabsX_Obj_35_RL 8;
BA_ "GenSigSendType" SG_ 866 ARC_OD_AabsX_Obj_35_RL 8;
BA_ "GenSigSendType" SG_ 866 ARC_OD_AabsX_Obj_34_RL 8;
BA_ "GenSigSendType" SG_ 866 ARC_OD_DistY_Obj_35_RL 8;
BA_ "GenSigSendType" SG_ 866 ARC_OD_VabsY_Obj_35_RL 8;
BA_ "GenSigSendType" SG_ 866 ARC_OD_AabsY_Obj_35_RL 8;
BA_ "GenSigSendType" SG_ 866 ARC_OD_DistXStd_Obj_35_RL 8;
BA_ "GenSigSendType" SG_ 866 ARC_OD_DistYStd_Obj_35_RL 8;
BA_ "GenSigSendType" SG_ 866 ARC_OD_VabsXStd_Obj_35_RL 8;
BA_ "GenSigSendType" SG_ 866 ARC_OD_VabsYStd_Obj_35_RL 8;
BA_ "GenSigSendType" SG_ 866 ARC_OD_AabsXStd_Obj_35_RL 8;
BA_ "GenSigSendType" SG_ 866 ARC_OD_Classification_Obj_35_RL 8;
BA_ "GenSigSendType" SG_ 866 ARC_OD_AabsYStd_Obj_35_RL 8;
BA_ "GenSigSendType" SG_ 866 ARC_OD_ClassConf_Obj_35_RL 8;
BA_ "GenSigSendType" SG_ 866 ARC_OD_DistY_Obj_34_RL 8;
BA_ "GenSigSendType" SG_ 866 ARC_OD_ProbOfExist_Obj_35_RL 8;
BA_ "GenSigSendType" SG_ 866 ARC_OD_DynProp_Obj_35_RL 8;
BA_ "GenSigSendType" SG_ 866 ARC_OD_Length_Obj_35_RL 8;
BA_ "GenSigSendType" SG_ 866 ARC_OD_MaintenanceState_Obj_0096 8;
BA_ "GenSigSendType" SG_ 866 ARC_OD_Width_Obj_35_RL 8;
BA_ "GenSigSendType" SG_ 866 ARC_OD_RCS_Obj_35_RL 8;
BA_ "GenSigSendType" SG_ 866 ARC_OD_Orientation_Obj_35_RL 8;
BA_ "GenSigSendType" SG_ 866 ARC_OD_LifeCycle_Obj_35_RL 8;
BA_ "GenSigSendType" SG_ 866 ARC_OD_ObstacleProb_Obj_34_RL 8;
BA_ "GenSigSendType" SG_ 866 ARC_OD_ObstacleProb_Obj_35_RL 8;
BA_ "GenSigSendType" SG_ 866 ARC_OD_VabsY_Obj_34_RL 8;
BA_ "GenSigSendType" SG_ 866 ARC_OD_ID_34_RL 8;
BA_ "GenSigSendType" SG_ 866 ARC_OD_ID_35_RL 8;
BA_ "GenSigSendType" SG_ 866 ARC_OD_MsgCounter_Obj_34_35_RL 8;
BA_ "GenSigSendType" SG_ 866 ARC_OD_CRC8_Obj_34_35_RL 8;
BA_ "GenSigSendType" SG_ 866 ARC_OD_AabsY_Obj_34_RL 8;
BA_ "GenSigSendType" SG_ 866 ARC_OD_DistXStd_Obj_34_RL 8;
BA_ "GenSigSendType" SG_ 866 ARC_OD_DistYStd_Obj_34_RL 8;
BA_ "GenSigSendType" SG_ 866 ARC_OD_VabsXStd_Obj_34_RL 8;
BA_ "GenSigSendType" SG_ 866 ARC_OD_VabsYStd_Obj_34_RL 8;
BA_ "GenSigSendType" SG_ 866 ARC_OD_AabsXStd_Obj_34_RL 8;
BA_ "GenSigSendType" SG_ 867 DistHeight_Obj_37_RL 8;
BA_ "GenSigSendType" SG_ 867 DistHeight_Obj_36_RL 8;
BA_ "GenSigSendType" SG_ 867 ARC_OD_DistX_Obj_36_RL 8;
BA_ "GenSigSendType" SG_ 867 ARC_OD_Classification_Obj_36_RL 8;
BA_ "GenSigSendType" SG_ 867 ARC_OD_AabsYStd_Obj_36_RL 8;
BA_ "GenSigSendType" SG_ 867 ARC_OD_ClassConf_Obj_36_RL 8;
BA_ "GenSigSendType" SG_ 867 ARC_OD_ProbOfExist_Obj_36_RL 8;
BA_ "GenSigSendType" SG_ 867 ARC_OD_VabsX_Obj_36_RL 8;
BA_ "GenSigSendType" SG_ 867 ARC_OD_DynProp_Obj_36_RL 8;
BA_ "GenSigSendType" SG_ 867 ARC_OD_Length_Obj_36_RL 8;
BA_ "GenSigSendType" SG_ 867 ARC_OD_MaintenanceState_Obj_0097 8;
BA_ "GenSigSendType" SG_ 867 ARC_OD_Width_Obj_36_RL 8;
BA_ "GenSigSendType" SG_ 867 ARC_OD_RCS_Obj_36_RL 8;
BA_ "GenSigSendType" SG_ 867 ARC_OD_Orientation_Obj_36_RL 8;
BA_ "GenSigSendType" SG_ 867 ARC_OD_LifeCycle_Obj_36_RL 8;
BA_ "GenSigSendType" SG_ 867 ARC_OD_DistX_Obj_37_RL 8;
BA_ "GenSigSendType" SG_ 867 ARC_OD_VabsX_Obj_37_RL 8;
BA_ "GenSigSendType" SG_ 867 ARC_OD_AabsX_Obj_37_RL 8;
BA_ "GenSigSendType" SG_ 867 ARC_OD_AabsX_Obj_36_RL 8;
BA_ "GenSigSendType" SG_ 867 ARC_OD_DistY_Obj_37_RL 8;
BA_ "GenSigSendType" SG_ 867 ARC_OD_VabsY_Obj_37_RL 8;
BA_ "GenSigSendType" SG_ 867 ARC_OD_AabsY_Obj_37_RL 8;
BA_ "GenSigSendType" SG_ 867 ARC_OD_DistXStd_Obj_37_RL 8;
BA_ "GenSigSendType" SG_ 867 ARC_OD_DistYStd_Obj_37_RL 8;
BA_ "GenSigSendType" SG_ 867 ARC_OD_VabsXStd_Obj_37_RL 8;
BA_ "GenSigSendType" SG_ 867 ARC_OD_VabsYStd_Obj_37_RL 8;
BA_ "GenSigSendType" SG_ 867 ARC_OD_AabsXStd_Obj_37_RL 8;
BA_ "GenSigSendType" SG_ 867 ARC_OD_Classification_Obj_37_RL 8;
BA_ "GenSigSendType" SG_ 867 ARC_OD_AabsYStd_Obj_37_RL 8;
BA_ "GenSigSendType" SG_ 867 ARC_OD_ClassConf_Obj_37_RL 8;
BA_ "GenSigSendType" SG_ 867 ARC_OD_DistY_Obj_36_RL 8;
BA_ "GenSigSendType" SG_ 867 ARC_OD_ProbOfExist_Obj_37_RL 8;
BA_ "GenSigSendType" SG_ 867 ARC_OD_DynProp_Obj_37_RL 8;
BA_ "GenSigSendType" SG_ 867 ARC_OD_Length_Obj_37_RL 8;
BA_ "GenSigSendType" SG_ 867 ARC_OD_MaintenanceState_Obj_0098 8;
BA_ "GenSigSendType" SG_ 867 ARC_OD_Width_Obj_37_RL 8;
BA_ "GenSigSendType" SG_ 867 ARC_OD_RCS_Obj_37_RL 8;
BA_ "GenSigSendType" SG_ 867 ARC_OD_Orientation_Obj_37_RL 8;
BA_ "GenSigSendType" SG_ 867 ARC_OD_LifeCycle_Obj_37_RL 8;
BA_ "GenSigSendType" SG_ 867 ARC_OD_ObstacleProb_Obj_36_RL 8;
BA_ "GenSigSendType" SG_ 867 ARC_OD_ObstacleProb_Obj_37_RL 8;
BA_ "GenSigSendType" SG_ 867 ARC_OD_VabsY_Obj_36_RL 8;
BA_ "GenSigSendType" SG_ 867 ARC_OD_ID_36_RL 8;
BA_ "GenSigSendType" SG_ 867 ARC_OD_ID_37_RL 8;
BA_ "GenSigSendType" SG_ 867 ARC_OD_MsgCounter_Obj_36_37_RL 8;
BA_ "GenSigSendType" SG_ 867 ARC_OD_CRC8_Obj_36_37_RL 8;
BA_ "GenSigSendType" SG_ 867 ARC_OD_AabsY_Obj_36_RL 8;
BA_ "GenSigSendType" SG_ 867 ARC_OD_DistXStd_Obj_36_RL 8;
BA_ "GenSigSendType" SG_ 867 ARC_OD_DistYStd_Obj_36_RL 8;
BA_ "GenSigSendType" SG_ 867 ARC_OD_VabsXStd_Obj_36_RL 8;
BA_ "GenSigSendType" SG_ 867 ARC_OD_VabsYStd_Obj_36_RL 8;
BA_ "GenSigSendType" SG_ 867 ARC_OD_AabsXStd_Obj_36_RL 8;
BA_ "GenSigSendType" SG_ 868 DistHeight_Obj_39_RL 8;
BA_ "GenSigSendType" SG_ 868 DistHeight_Obj_38_RL 8;
BA_ "GenSigSendType" SG_ 868 ARC_OD_DistX_Obj_38_RL 8;
BA_ "GenSigSendType" SG_ 868 ARC_OD_Classification_Obj_38_RL 8;
BA_ "GenSigSendType" SG_ 868 ARC_OD_AabsYStd_Obj_38_RL 8;
BA_ "GenSigSendType" SG_ 868 ARC_OD_ClassConf_Obj_38_RL 8;
BA_ "GenSigSendType" SG_ 868 ARC_OD_ProbOfExist_Obj_38_RL 8;
BA_ "GenSigSendType" SG_ 868 ARC_OD_VabsX_Obj_38_RL 8;
BA_ "GenSigSendType" SG_ 868 ARC_OD_DynProp_Obj_38_RL 8;
BA_ "GenSigSendType" SG_ 868 ARC_OD_Length_Obj_38_RL 8;
BA_ "GenSigSendType" SG_ 868 ARC_OD_MaintenanceState_Obj_0099 8;
BA_ "GenSigSendType" SG_ 868 ARC_OD_Width_Obj_38_RL 8;
BA_ "GenSigSendType" SG_ 868 ARC_OD_RCS_Obj_38_RL 8;
BA_ "GenSigSendType" SG_ 868 ARC_OD_Orientation_Obj_38_RL 8;
BA_ "GenSigSendType" SG_ 868 ARC_OD_LifeCycle_Obj_38_RL 8;
BA_ "GenSigSendType" SG_ 868 ARC_OD_DistX_Obj_39_RL 8;
BA_ "GenSigSendType" SG_ 868 ARC_OD_VabsX_Obj_39_RL 8;
BA_ "GenSigSendType" SG_ 868 ARC_OD_AabsX_Obj_39_RL 8;
BA_ "GenSigSendType" SG_ 868 ARC_OD_AabsX_Obj_38_RL 8;
BA_ "GenSigSendType" SG_ 868 ARC_OD_DistY_Obj_39_RL 8;
BA_ "GenSigSendType" SG_ 868 ARC_OD_VabsY_Obj_39_RL 8;
BA_ "GenSigSendType" SG_ 868 ARC_OD_AabsY_Obj_39_RL 8;
BA_ "GenSigSendType" SG_ 868 ARC_OD_DistXStd_Obj_39_RL 8;
BA_ "GenSigSendType" SG_ 868 ARC_OD_DistYStd_Obj_39_RL 8;
BA_ "GenSigSendType" SG_ 868 ARC_OD_VabsXStd_Obj_39_RL 8;
BA_ "GenSigSendType" SG_ 868 ARC_OD_VabsYStd_Obj_39_RL 8;
BA_ "GenSigSendType" SG_ 868 ARC_OD_AabsXStd_Obj_39_RL 8;
BA_ "GenSigSendType" SG_ 868 ARC_OD_Classification_Obj_39_RL 8;
BA_ "GenSigSendType" SG_ 868 ARC_OD_AabsYStd_Obj_39_RL 8;
BA_ "GenSigSendType" SG_ 868 ARC_OD_ClassConf_Obj_39_RL 8;
BA_ "GenSigSendType" SG_ 868 ARC_OD_DistY_Obj_38_RL 8;
BA_ "GenSigSendType" SG_ 868 ARC_OD_ProbOfExist_Obj_39_RL 8;
BA_ "GenSigSendType" SG_ 868 ARC_OD_DynProp_Obj_39_RL 8;
BA_ "GenSigSendType" SG_ 868 ARC_OD_Length_Obj_39_RL 8;
BA_ "GenSigSendType" SG_ 868 ARC_OD_MaintenanceState_Obj_0100 8;
BA_ "GenSigSendType" SG_ 868 ARC_OD_Width_Obj_39_RL 8;
BA_ "GenSigSendType" SG_ 868 ARC_OD_RCS_Obj_39_RL 8;
BA_ "GenSigSendType" SG_ 868 ARC_OD_Orientation_Obj_39_RL 8;
BA_ "GenSigSendType" SG_ 868 ARC_OD_LifeCycle_Obj_39_RL 8;
BA_ "GenSigSendType" SG_ 868 ARC_OD_ObstacleProb_Obj_38_RL 8;
BA_ "GenSigSendType" SG_ 868 ARC_OD_ObstacleProb_Obj_39_RL 8;
BA_ "GenSigSendType" SG_ 868 ARC_OD_VabsY_Obj_38_RL 8;
BA_ "GenSigSendType" SG_ 868 ARC_OD_ID_38_RL 8;
BA_ "GenSigSendType" SG_ 868 ARC_OD_ID_39_RL 8;
BA_ "GenSigSendType" SG_ 868 ARC_OD_MsgCounter_Obj_38_39_RL 8;
BA_ "GenSigSendType" SG_ 868 ARC_OD_CRC8_Obj_38_39_RL 8;
BA_ "GenSigSendType" SG_ 868 ARC_OD_AabsY_Obj_38_RL 8;
BA_ "GenSigSendType" SG_ 868 ARC_OD_DistXStd_Obj_38_RL 8;
BA_ "GenSigSendType" SG_ 868 ARC_OD_DistYStd_Obj_38_RL 8;
BA_ "GenSigSendType" SG_ 868 ARC_OD_VabsXStd_Obj_38_RL 8;
BA_ "GenSigSendType" SG_ 868 ARC_OD_VabsYStd_Obj_38_RL 8;
BA_ "GenSigSendType" SG_ 868 ARC_OD_AabsXStd_Obj_38_RL 8;
BA_ "GenSigSendType" SG_ 869 DistHeight_Obj_41_RL 8;
BA_ "GenSigSendType" SG_ 869 DistHeight_Obj_40_RL 8;
BA_ "GenSigSendType" SG_ 869 ARC_OD_DistX_Obj_40_RL 8;
BA_ "GenSigSendType" SG_ 869 ARC_OD_Classification_Obj_40_RL 8;
BA_ "GenSigSendType" SG_ 869 ARC_OD_AabsYStd_Obj_40_RL 8;
BA_ "GenSigSendType" SG_ 869 ARC_OD_ClassConf_Obj_40_RL 8;
BA_ "GenSigSendType" SG_ 869 ARC_OD_ProbOfExist_Obj_40_RL 8;
BA_ "GenSigSendType" SG_ 869 ARC_OD_VabsX_Obj_40_RL 8;
BA_ "GenSigSendType" SG_ 869 ARC_OD_DynProp_Obj_40_RL 8;
BA_ "GenSigSendType" SG_ 869 ARC_OD_Length_Obj_40_RL 8;
BA_ "GenSigSendType" SG_ 869 ARC_OD_MaintenanceState_Obj_0101 8;
BA_ "GenSigSendType" SG_ 869 ARC_OD_Width_Obj_40_RL 8;
BA_ "GenSigSendType" SG_ 869 ARC_OD_RCS_Obj_40_RL 8;
BA_ "GenSigSendType" SG_ 869 ARC_OD_Orientation_Obj_40_RL 8;
BA_ "GenSigSendType" SG_ 869 ARC_OD_LifeCycle_Obj_40_RL 8;
BA_ "GenSigSendType" SG_ 869 ARC_OD_DistX_Obj_41_RL 8;
BA_ "GenSigSendType" SG_ 869 ARC_OD_VabsX_Obj_41_RL 8;
BA_ "GenSigSendType" SG_ 869 ARC_OD_AabsX_Obj_41_RL 8;
BA_ "GenSigSendType" SG_ 869 ARC_OD_AabsX_Obj_40_RL 8;
BA_ "GenSigSendType" SG_ 869 ARC_OD_DistY_Obj_41_RL 8;
BA_ "GenSigSendType" SG_ 869 ARC_OD_VabsY_Obj_41_RL 8;
BA_ "GenSigSendType" SG_ 869 ARC_OD_AabsY_Obj_41_RL 8;
BA_ "GenSigSendType" SG_ 869 ARC_OD_DistXStd_Obj_41_RL 8;
BA_ "GenSigSendType" SG_ 869 ARC_OD_DistYStd_Obj_41_RL 8;
BA_ "GenSigSendType" SG_ 869 ARC_OD_VabsXStd_Obj_41_RL 8;
BA_ "GenSigSendType" SG_ 869 ARC_OD_VabsYStd_Obj_41_RL 8;
BA_ "GenSigSendType" SG_ 869 ARC_OD_AabsXStd_Obj_41_RL 8;
BA_ "GenSigSendType" SG_ 869 ARC_OD_Classification_Obj_41_RL 8;
BA_ "GenSigSendType" SG_ 869 ARC_OD_AabsYStd_Obj_41_RL 8;
BA_ "GenSigSendType" SG_ 869 ARC_OD_ClassConf_Obj_41_RL 8;
BA_ "GenSigSendType" SG_ 869 ARC_OD_DistY_Obj_40_RL 8;
BA_ "GenSigSendType" SG_ 869 ARC_OD_ProbOfExist_Obj_41_RL 8;
BA_ "GenSigSendType" SG_ 869 ARC_OD_DynProp_Obj_41_RL 8;
BA_ "GenSigSendType" SG_ 869 ARC_OD_Length_Obj_41_RL 8;
BA_ "GenSigSendType" SG_ 869 ARC_OD_MaintenanceState_Obj_0102 8;
BA_ "GenSigSendType" SG_ 869 ARC_OD_Width_Obj_41_RL 8;
BA_ "GenSigSendType" SG_ 869 ARC_OD_RCS_Obj_41_RL 8;
BA_ "GenSigSendType" SG_ 869 ARC_OD_Orientation_Obj_41_RL 8;
BA_ "GenSigSendType" SG_ 869 ARC_OD_LifeCycle_Obj_41_RL 8;
BA_ "GenSigSendType" SG_ 869 ARC_OD_ObstacleProb_Obj_40_RL 8;
BA_ "GenSigSendType" SG_ 869 ARC_OD_ObstacleProb_Obj_41_RL 8;
BA_ "GenSigSendType" SG_ 869 ARC_OD_VabsY_Obj_40_RL 8;
BA_ "GenSigSendType" SG_ 869 ARC_OD_ID_40_RL 8;
BA_ "GenSigSendType" SG_ 869 ARC_OD_ID_41_RL 8;
BA_ "GenSigSendType" SG_ 869 ARC_OD_MsgCounter_Obj_40_41_RL 8;
BA_ "GenSigSendType" SG_ 869 ARC_OD_CRC8_Obj_40_41_RL 8;
BA_ "GenSigSendType" SG_ 869 ARC_OD_AabsY_Obj_40_RL 8;
BA_ "GenSigSendType" SG_ 869 ARC_OD_DistXStd_Obj_40_RL 8;
BA_ "GenSigSendType" SG_ 869 ARC_OD_DistYStd_Obj_40_RL 8;
BA_ "GenSigSendType" SG_ 869 ARC_OD_VabsXStd_Obj_40_RL 8;
BA_ "GenSigSendType" SG_ 869 ARC_OD_VabsYStd_Obj_40_RL 8;
BA_ "GenSigSendType" SG_ 869 ARC_OD_AabsXStd_Obj_40_RL 8;
BA_ "GenSigSendType" SG_ 870 DistHeight_Obj_43_RL 8;
BA_ "GenSigSendType" SG_ 870 DistHeight_Obj_42_RL 8;
BA_ "GenSigSendType" SG_ 870 ARC_OD_DistX_Obj_42_RL 8;
BA_ "GenSigSendType" SG_ 870 ARC_OD_Classification_Obj_42_RL 8;
BA_ "GenSigSendType" SG_ 870 ARC_OD_AabsYStd_Obj_42_RL 8;
BA_ "GenSigSendType" SG_ 870 ARC_OD_ClassConf_Obj_42_RL 8;
BA_ "GenSigSendType" SG_ 870 ARC_OD_ProbOfExist_Obj_42_RL 8;
BA_ "GenSigSendType" SG_ 870 ARC_OD_VabsX_Obj_42_RL 8;
BA_ "GenSigSendType" SG_ 870 ARC_OD_DynProp_Obj_42_RL 8;
BA_ "GenSigSendType" SG_ 870 ARC_OD_Length_Obj_42_RL 8;
BA_ "GenSigSendType" SG_ 870 ARC_OD_MaintenanceState_Obj_0103 8;
BA_ "GenSigSendType" SG_ 870 ARC_OD_Width_Obj_42_RL 8;
BA_ "GenSigSendType" SG_ 870 ARC_OD_RCS_Obj_42_RL 8;
BA_ "GenSigSendType" SG_ 870 ARC_OD_Orientation_Obj_42_RL 8;
BA_ "GenSigSendType" SG_ 870 ARC_OD_LifeCycle_Obj_42_RL 8;
BA_ "GenSigSendType" SG_ 870 ARC_OD_DistX_Obj_43_RL 8;
BA_ "GenSigSendType" SG_ 870 ARC_OD_VabsX_Obj_43_RL 8;
BA_ "GenSigSendType" SG_ 870 ARC_OD_AabsX_Obj_43_RL 8;
BA_ "GenSigSendType" SG_ 870 ARC_OD_AabsX_Obj_42_RL 8;
BA_ "GenSigSendType" SG_ 870 ARC_OD_DistY_Obj_43_RL 8;
BA_ "GenSigSendType" SG_ 870 ARC_OD_VabsY_Obj_43_RL 8;
BA_ "GenSigSendType" SG_ 870 ARC_OD_AabsY_Obj_43_RL 8;
BA_ "GenSigSendType" SG_ 870 ARC_OD_DistXStd_Obj_43_RL 8;
BA_ "GenSigSendType" SG_ 870 ARC_OD_DistYStd_Obj_43_RL 8;
BA_ "GenSigSendType" SG_ 870 ARC_OD_VabsXStd_Obj_43_RL 8;
BA_ "GenSigSendType" SG_ 870 ARC_OD_VabsYStd_Obj_43_RL 8;
BA_ "GenSigSendType" SG_ 870 ARC_OD_AabsXStd_Obj_43_RL 8;
BA_ "GenSigSendType" SG_ 870 ARC_OD_Classification_Obj_43_RL 8;
BA_ "GenSigSendType" SG_ 870 ARC_OD_AabsYStd_Obj_43_RL 8;
BA_ "GenSigSendType" SG_ 870 ARC_OD_ClassConf_Obj_43_RL 8;
BA_ "GenSigSendType" SG_ 870 ARC_OD_DistY_Obj_42_RL 8;
BA_ "GenSigSendType" SG_ 870 ARC_OD_ProbOfExist_Obj_43_RL 8;
BA_ "GenSigSendType" SG_ 870 ARC_OD_DynProp_Obj_43_RL 8;
BA_ "GenSigSendType" SG_ 870 ARC_OD_Length_Obj_43_RL 8;
BA_ "GenSigSendType" SG_ 870 ARC_OD_MaintenanceState_Obj_0104 8;
BA_ "GenSigSendType" SG_ 870 ARC_OD_Width_Obj_43_RL 8;
BA_ "GenSigSendType" SG_ 870 ARC_OD_RCS_Obj_43_RL 8;
BA_ "GenSigSendType" SG_ 870 ARC_OD_Orientation_Obj_43_RL 8;
BA_ "GenSigSendType" SG_ 870 ARC_OD_LifeCycle_Obj_43_RL 8;
BA_ "GenSigSendType" SG_ 870 ARC_OD_ObstacleProb_Obj_42_RL 8;
BA_ "GenSigSendType" SG_ 870 ARC_OD_ObstacleProb_Obj_43_RL 8;
BA_ "GenSigSendType" SG_ 870 ARC_OD_VabsY_Obj_42_RL 8;
BA_ "GenSigSendType" SG_ 870 ARC_OD_ID_42_RL 8;
BA_ "GenSigSendType" SG_ 870 ARC_OD_ID_43_RL 8;
BA_ "GenSigSendType" SG_ 870 ARC_OD_MsgCounter_Obj_42_43_RL 8;
BA_ "GenSigSendType" SG_ 870 ARC_OD_CRC8_Obj_42_43_RL 8;
BA_ "GenSigSendType" SG_ 870 ARC_OD_AabsY_Obj_42_RL 8;
BA_ "GenSigSendType" SG_ 870 ARC_OD_DistXStd_Obj_42_RL 8;
BA_ "GenSigSendType" SG_ 870 ARC_OD_DistYStd_Obj_42_RL 8;
BA_ "GenSigSendType" SG_ 870 ARC_OD_VabsXStd_Obj_42_RL 8;
BA_ "GenSigSendType" SG_ 870 ARC_OD_VabsYStd_Obj_42_RL 8;
BA_ "GenSigSendType" SG_ 870 ARC_OD_AabsXStd_Obj_42_RL 8;
BA_ "GenSigSendType" SG_ 871 DistHeight_Obj_45_RL 8;
BA_ "GenSigSendType" SG_ 871 DistHeight_Obj_44_RL 8;
BA_ "GenSigSendType" SG_ 871 ARC_OD_DistX_Obj_44_RL 8;
BA_ "GenSigSendType" SG_ 871 ARC_OD_Classification_Obj_44_RL 8;
BA_ "GenSigSendType" SG_ 871 ARC_OD_AabsYStd_Obj_44_RL 8;
BA_ "GenSigSendType" SG_ 871 ARC_OD_ClassConf_Obj_44_RL 8;
BA_ "GenSigSendType" SG_ 871 ARC_OD_ProbOfExist_Obj_44_RL 8;
BA_ "GenSigSendType" SG_ 871 ARC_OD_VabsX_Obj_44_RL 8;
BA_ "GenSigSendType" SG_ 871 ARC_OD_DynProp_Obj_44_RL 8;
BA_ "GenSigSendType" SG_ 871 ARC_OD_Length_Obj_44_RL 8;
BA_ "GenSigSendType" SG_ 871 ARC_OD_MaintenanceState_Obj_0105 8;
BA_ "GenSigSendType" SG_ 871 ARC_OD_Width_Obj_44_RL 8;
BA_ "GenSigSendType" SG_ 871 ARC_OD_RCS_Obj_44_RL 8;
BA_ "GenSigSendType" SG_ 871 ARC_OD_Orientation_Obj_44_RL 8;
BA_ "GenSigSendType" SG_ 871 ARC_OD_LifeCycle_Obj_44_RL 8;
BA_ "GenSigSendType" SG_ 871 ARC_OD_DistX_Obj_45_RL 8;
BA_ "GenSigSendType" SG_ 871 ARC_OD_VabsX_Obj_45_RL 8;
BA_ "GenSigSendType" SG_ 871 ARC_OD_AabsX_Obj_45_RL 8;
BA_ "GenSigSendType" SG_ 871 ARC_OD_AabsX_Obj_44_RL 8;
BA_ "GenSigSendType" SG_ 871 ARC_OD_DistY_Obj_45_RL 8;
BA_ "GenSigSendType" SG_ 871 ARC_OD_VabsY_Obj_45_RL 8;
BA_ "GenSigSendType" SG_ 871 ARC_OD_AabsY_Obj_45_RL 8;
BA_ "GenSigSendType" SG_ 871 ARC_OD_DistXStd_Obj_45_RL 8;
BA_ "GenSigSendType" SG_ 871 ARC_OD_DistYStd_Obj_45_RL 8;
BA_ "GenSigSendType" SG_ 871 ARC_OD_VabsXStd_Obj_45_RL 8;
BA_ "GenSigSendType" SG_ 871 ARC_OD_VabsYStd_Obj_45_RL 8;
BA_ "GenSigSendType" SG_ 871 ARC_OD_AabsXStd_Obj_45_RL 8;
BA_ "GenSigSendType" SG_ 871 ARC_OD_Classification_Obj_45_RL 8;
BA_ "GenSigSendType" SG_ 871 ARC_OD_AabsYStd_Obj_45_RL 8;
BA_ "GenSigSendType" SG_ 871 ARC_OD_ClassConf_Obj_45_RL 8;
BA_ "GenSigSendType" SG_ 871 ARC_OD_DistY_Obj_44_RL 8;
BA_ "GenSigSendType" SG_ 871 ARC_OD_ProbOfExist_Obj_45_RL 8;
BA_ "GenSigSendType" SG_ 871 ARC_OD_DynProp_Obj_45_RL 8;
BA_ "GenSigSendType" SG_ 871 ARC_OD_Length_Obj_45_RL 8;
BA_ "GenSigSendType" SG_ 871 ARC_OD_MaintenanceState_Obj_0106 8;
BA_ "GenSigSendType" SG_ 871 ARC_OD_Width_Obj_45_RL 8;
BA_ "GenSigSendType" SG_ 871 ARC_OD_RCS_Obj_45_RL 8;
BA_ "GenSigSendType" SG_ 871 ARC_OD_Orientation_Obj_45_RL 8;
BA_ "GenSigSendType" SG_ 871 ARC_OD_LifeCycle_Obj_45_RL 8;
BA_ "GenSigSendType" SG_ 871 ARC_OD_ObstacleProb_Obj_44_RL 8;
BA_ "GenSigSendType" SG_ 871 ARC_OD_ObstacleProb_Obj_45_RL 8;
BA_ "GenSigSendType" SG_ 871 ARC_OD_VabsY_Obj_44_RL 8;
BA_ "GenSigSendType" SG_ 871 ARC_OD_ID_44_RL 8;
BA_ "GenSigSendType" SG_ 871 ARC_OD_ID_45_RL 8;
BA_ "GenSigSendType" SG_ 871 ARC_OD_MsgCounter_Obj_44_45_RL 8;
BA_ "GenSigSendType" SG_ 871 ARC_OD_CRC8_Obj_44_45_RL 8;
BA_ "GenSigSendType" SG_ 871 ARC_OD_AabsY_Obj_44_RL 8;
BA_ "GenSigSendType" SG_ 871 ARC_OD_DistXStd_Obj_44_RL 8;
BA_ "GenSigSendType" SG_ 871 ARC_OD_DistYStd_Obj_44_RL 8;
BA_ "GenSigSendType" SG_ 871 ARC_OD_VabsXStd_Obj_44_RL 8;
BA_ "GenSigSendType" SG_ 871 ARC_OD_VabsYStd_Obj_44_RL 8;
BA_ "GenSigSendType" SG_ 871 ARC_OD_AabsXStd_Obj_44_RL 8;
BA_ "GenSigSendType" SG_ 872 DistHeight_Obj_47_RL 8;
BA_ "GenSigSendType" SG_ 872 DistHeight_Obj_46_RL 8;
BA_ "GenSigSendType" SG_ 872 ARC_OD_DistX_Obj_46_RL 8;
BA_ "GenSigSendType" SG_ 872 ARC_OD_Classification_Obj_46_RL 8;
BA_ "GenSigSendType" SG_ 872 ARC_OD_AabsYStd_Obj_46_RL 8;
BA_ "GenSigSendType" SG_ 872 ARC_OD_ClassConf_Obj_46_RL 8;
BA_ "GenSigSendType" SG_ 872 ARC_OD_ProbOfExist_Obj_46_RL 8;
BA_ "GenSigSendType" SG_ 872 ARC_OD_VabsX_Obj_46_RL 8;
BA_ "GenSigSendType" SG_ 872 ARC_OD_DynProp_Obj_46_RL 8;
BA_ "GenSigSendType" SG_ 872 ARC_OD_Length_Obj_46_RL 8;
BA_ "GenSigSendType" SG_ 872 ARC_OD_MaintenanceState_Obj_0107 8;
BA_ "GenSigSendType" SG_ 872 ARC_OD_Width_Obj_46_RL 8;
BA_ "GenSigSendType" SG_ 872 ARC_OD_RCS_Obj_46_RL 8;
BA_ "GenSigSendType" SG_ 872 ARC_OD_Orientation_Obj_46_RL 8;
BA_ "GenSigSendType" SG_ 872 ARC_OD_LifeCycle_Obj_46_RL 8;
BA_ "GenSigSendType" SG_ 872 ARC_OD_DistX_Obj_47_RL 8;
BA_ "GenSigSendType" SG_ 872 ARC_OD_VabsX_Obj_47_RL 8;
BA_ "GenSigSendType" SG_ 872 ARC_OD_AabsX_Obj_47_RL 8;
BA_ "GenSigSendType" SG_ 872 ARC_OD_AabsX_Obj_46_RL 8;
BA_ "GenSigSendType" SG_ 872 ARC_OD_DistY_Obj_47_RL 8;
BA_ "GenSigSendType" SG_ 872 ARC_OD_VabsY_Obj_47_RL 8;
BA_ "GenSigSendType" SG_ 872 ARC_OD_AabsY_Obj_47_RL 8;
BA_ "GenSigSendType" SG_ 872 ARC_OD_DistXStd_Obj_47_RL 8;
BA_ "GenSigSendType" SG_ 872 ARC_OD_DistYStd_Obj_47_RL 8;
BA_ "GenSigSendType" SG_ 872 ARC_OD_VabsXStd_Obj_47_RL 8;
BA_ "GenSigSendType" SG_ 872 ARC_OD_VabsYStd_Obj_47_RL 8;
BA_ "GenSigSendType" SG_ 872 ARC_OD_AabsXStd_Obj_47_RL 8;
BA_ "GenSigSendType" SG_ 872 ARC_OD_Classification_Obj_47_RL 8;
BA_ "GenSigSendType" SG_ 872 ARC_OD_AabsYStd_Obj_47_RL 8;
BA_ "GenSigSendType" SG_ 872 ARC_OD_ClassConf_Obj_47_RL 8;
BA_ "GenSigSendType" SG_ 872 ARC_OD_DistY_Obj_46_RL 8;
BA_ "GenSigSendType" SG_ 872 ARC_OD_ProbOfExist_Obj_47_RL 8;
BA_ "GenSigSendType" SG_ 872 ARC_OD_DynProp_Obj_47_RL 8;
BA_ "GenSigSendType" SG_ 872 ARC_OD_Length_Obj_47_RL 8;
BA_ "GenSigSendType" SG_ 872 ARC_OD_MaintenanceState_Obj_0108 8;
BA_ "GenSigSendType" SG_ 872 ARC_OD_Width_Obj_47_RL 8;
BA_ "GenSigSendType" SG_ 872 ARC_OD_RCS_Obj_47_RL 8;
BA_ "GenSigSendType" SG_ 872 ARC_OD_Orientation_Obj_47_RL 8;
BA_ "GenSigSendType" SG_ 872 ARC_OD_LifeCycle_Obj_47_RL 8;
BA_ "GenSigSendType" SG_ 872 ARC_OD_ObstacleProb_Obj_46_RL 8;
BA_ "GenSigSendType" SG_ 872 ARC_OD_ObstacleProb_Obj_47_RL 8;
BA_ "GenSigSendType" SG_ 872 ARC_OD_VabsY_Obj_46_RL 8;
BA_ "GenSigSendType" SG_ 872 ARC_OD_ID_46_RL 8;
BA_ "GenSigSendType" SG_ 872 ARC_OD_ID_47_RL 8;
BA_ "GenSigSendType" SG_ 872 ARC_OD_MsgCounter_Obj_46_47_RL 8;
BA_ "GenSigSendType" SG_ 872 ARC_OD_CRC8_Obj_46_47_RL 8;
BA_ "GenSigSendType" SG_ 872 ARC_OD_AabsY_Obj_46_RL 8;
BA_ "GenSigSendType" SG_ 872 ARC_OD_DistXStd_Obj_46_RL 8;
BA_ "GenSigSendType" SG_ 872 ARC_OD_DistYStd_Obj_46_RL 8;
BA_ "GenSigSendType" SG_ 872 ARC_OD_VabsXStd_Obj_46_RL 8;
BA_ "GenSigSendType" SG_ 872 ARC_OD_VabsYStd_Obj_46_RL 8;
BA_ "GenSigSendType" SG_ 872 ARC_OD_AabsXStd_Obj_46_RL 8;
BA_ "GenSigSendType" SG_ 873 DistHeight_Obj_49_RL 8;
BA_ "GenSigSendType" SG_ 873 DistHeight_Obj_48_RL 8;
BA_ "GenSigSendType" SG_ 873 ARC_OD_DistX_Obj_48_RL 8;
BA_ "GenSigSendType" SG_ 873 ARC_OD_Classification_Obj_48_RL 8;
BA_ "GenSigSendType" SG_ 873 ARC_OD_AabsYStd_Obj_48_RL 8;
BA_ "GenSigSendType" SG_ 873 ARC_OD_ClassConf_Obj_48_RL 8;
BA_ "GenSigSendType" SG_ 873 ARC_OD_ProbOfExist_Obj_48_RL 8;
BA_ "GenSigSendType" SG_ 873 ARC_OD_VabsX_Obj_48_RL 8;
BA_ "GenSigSendType" SG_ 873 ARC_OD_DynProp_Obj_48_RL 8;
BA_ "GenSigSendType" SG_ 873 ARC_OD_Length_Obj_48_RL 8;
BA_ "GenSigSendType" SG_ 873 ARC_OD_MaintenanceState_Obj_0109 8;
BA_ "GenSigSendType" SG_ 873 ARC_OD_Width_Obj_48_RL 8;
BA_ "GenSigSendType" SG_ 873 ARC_OD_RCS_Obj_48_RL 8;
BA_ "GenSigSendType" SG_ 873 ARC_OD_Orientation_Obj_48_RL 8;
BA_ "GenSigSendType" SG_ 873 ARC_OD_LifeCycle_Obj_48_RL 8;
BA_ "GenSigSendType" SG_ 873 ARC_OD_DistX_Obj_49_RL 8;
BA_ "GenSigSendType" SG_ 873 ARC_OD_VabsX_Obj_49_RL 8;
BA_ "GenSigSendType" SG_ 873 ARC_OD_AabsX_Obj_49_RL 8;
BA_ "GenSigSendType" SG_ 873 ARC_OD_AabsX_Obj_48_RL 8;
BA_ "GenSigSendType" SG_ 873 ARC_OD_DistY_Obj_49_RL 8;
BA_ "GenSigSendType" SG_ 873 ARC_OD_VabsY_Obj_49_RL 8;
BA_ "GenSigSendType" SG_ 873 ARC_OD_AabsY_Obj_49_RL 8;
BA_ "GenSigSendType" SG_ 873 ARC_OD_DistXStd_Obj_49_RL 8;
BA_ "GenSigSendType" SG_ 873 ARC_OD_DistYStd_Obj_49_RL 8;
BA_ "GenSigSendType" SG_ 873 ARC_OD_VabsXStd_Obj_49_RL 8;
BA_ "GenSigSendType" SG_ 873 ARC_OD_VabsYStd_Obj_49_RL 8;
BA_ "GenSigSendType" SG_ 873 ARC_OD_AabsXStd_Obj_49_RL 8;
BA_ "GenSigSendType" SG_ 873 ARC_OD_Classification_Obj_49_RL 8;
BA_ "GenSigSendType" SG_ 873 ARC_OD_AabsYStd_Obj_49_RL 8;
BA_ "GenSigSendType" SG_ 873 ARC_OD_ClassConf_Obj_49_RL 8;
BA_ "GenSigSendType" SG_ 873 ARC_OD_DistY_Obj_48_RL 8;
BA_ "GenSigSendType" SG_ 873 ARC_OD_ProbOfExist_Obj_49_RL 8;
BA_ "GenSigSendType" SG_ 873 ARC_OD_DynProp_Obj_49_RL 8;
BA_ "GenSigSendType" SG_ 873 ARC_OD_Length_Obj_49_RL 8;
BA_ "GenSigSendType" SG_ 873 ARC_OD_MaintenanceState_Obj_0110 8;
BA_ "GenSigSendType" SG_ 873 ARC_OD_Width_Obj_49_RL 8;
BA_ "GenSigSendType" SG_ 873 ARC_OD_RCS_Obj_49_RL 8;
BA_ "GenSigSendType" SG_ 873 ARC_OD_Orientation_Obj_49_RL 8;
BA_ "GenSigSendType" SG_ 873 ARC_OD_LifeCycle_Obj_49_RL 8;
BA_ "GenSigSendType" SG_ 873 ARC_OD_ObstacleProb_Obj_48_RL 8;
BA_ "GenSigSendType" SG_ 873 ARC_OD_ObstacleProb_Obj_49_RL 8;
BA_ "GenSigSendType" SG_ 873 ARC_OD_VabsY_Obj_48_RL 8;
BA_ "GenSigSendType" SG_ 873 ARC_OD_ID_48_RL 8;
BA_ "GenSigSendType" SG_ 873 ARC_OD_ID_49_RL 8;
BA_ "GenSigSendType" SG_ 873 ARC_OD_MsgCounter_Obj_48_49_RL 8;
BA_ "GenSigSendType" SG_ 873 ARC_OD_CRC8_Obj_48_49_RL 8;
BA_ "GenSigSendType" SG_ 873 ARC_OD_AabsY_Obj_48_RL 8;
BA_ "GenSigSendType" SG_ 873 ARC_OD_DistXStd_Obj_48_RL 8;
BA_ "GenSigSendType" SG_ 873 ARC_OD_DistYStd_Obj_48_RL 8;
BA_ "GenSigSendType" SG_ 873 ARC_OD_VabsXStd_Obj_48_RL 8;
BA_ "GenSigSendType" SG_ 873 ARC_OD_VabsYStd_Obj_48_RL 8;
BA_ "GenSigSendType" SG_ 873 ARC_OD_AabsXStd_Obj_48_RL 8;
BA_ "GenSigSendType" SG_ 874 DistHeight_Obj_51_RL 8;
BA_ "GenSigSendType" SG_ 874 DistHeight_Obj_50_RL 8;
BA_ "GenSigSendType" SG_ 874 ARC_OD_DistX_Obj_50_RL 8;
BA_ "GenSigSendType" SG_ 874 ARC_OD_Classification_Obj_50_RL 8;
BA_ "GenSigSendType" SG_ 874 ARC_OD_AabsYStd_Obj_50_RL 8;
BA_ "GenSigSendType" SG_ 874 ARC_OD_ClassConf_Obj_50_RL 8;
BA_ "GenSigSendType" SG_ 874 ARC_OD_ProbOfExist_Obj_50_RL 8;
BA_ "GenSigSendType" SG_ 874 ARC_OD_VabsX_Obj_50_RL 8;
BA_ "GenSigSendType" SG_ 874 ARC_OD_DynProp_Obj_50_RL 8;
BA_ "GenSigSendType" SG_ 874 ARC_OD_Length_Obj_50_RL 8;
BA_ "GenSigSendType" SG_ 874 ARC_OD_MaintenanceState_Obj_0111 8;
BA_ "GenSigSendType" SG_ 874 ARC_OD_Width_Obj_50_RL 8;
BA_ "GenSigSendType" SG_ 874 ARC_OD_RCS_Obj_50_RL 8;
BA_ "GenSigSendType" SG_ 874 ARC_OD_Orientation_Obj_50_RL 8;
BA_ "GenSigSendType" SG_ 874 ARC_OD_LifeCycle_Obj_50_RL 8;
BA_ "GenSigSendType" SG_ 874 ARC_OD_DistX_Obj_51_RL 8;
BA_ "GenSigSendType" SG_ 874 ARC_OD_VabsX_Obj_51_RL 8;
BA_ "GenSigSendType" SG_ 874 ARC_OD_AabsX_Obj_51_RL 8;
BA_ "GenSigSendType" SG_ 874 ARC_OD_AabsX_Obj_50_RL 8;
BA_ "GenSigSendType" SG_ 874 ARC_OD_DistY_Obj_51_RL 8;
BA_ "GenSigSendType" SG_ 874 ARC_OD_VabsY_Obj_51_RL 8;
BA_ "GenSigSendType" SG_ 874 ARC_OD_AabsY_Obj_51_RL 8;
BA_ "GenSigSendType" SG_ 874 ARC_OD_DistXStd_Obj_51_RL 8;
BA_ "GenSigSendType" SG_ 874 ARC_OD_DistYStd_Obj_51_RL 8;
BA_ "GenSigSendType" SG_ 874 ARC_OD_VabsXStd_Obj_51_RL 8;
BA_ "GenSigSendType" SG_ 874 ARC_OD_VabsYStd_Obj_51_RL 8;
BA_ "GenSigSendType" SG_ 874 ARC_OD_AabsXStd_Obj_51_RL 8;
BA_ "GenSigSendType" SG_ 874 ARC_OD_Classification_Obj_51_RL 8;
BA_ "GenSigSendType" SG_ 874 ARC_OD_AabsYStd_Obj_51_RL 8;
BA_ "GenSigSendType" SG_ 874 ARC_OD_ClassConf_Obj_51_RL 8;
BA_ "GenSigSendType" SG_ 874 ARC_OD_DistY_Obj_50_RL 8;
BA_ "GenSigSendType" SG_ 874 ARC_OD_ProbOfExist_Obj_51_RL 8;
BA_ "GenSigSendType" SG_ 874 ARC_OD_DynProp_Obj_51_RL 8;
BA_ "GenSigSendType" SG_ 874 ARC_OD_Length_Obj_51_RL 8;
BA_ "GenSigSendType" SG_ 874 ARC_OD_MaintenanceState_Obj_0112 8;
BA_ "GenSigSendType" SG_ 874 ARC_OD_Width_Obj_51_RL 8;
BA_ "GenSigSendType" SG_ 874 ARC_OD_RCS_Obj_51_RL 8;
BA_ "GenSigSendType" SG_ 874 ARC_OD_Orientation_Obj_51_RL 8;
BA_ "GenSigSendType" SG_ 874 ARC_OD_LifeCycle_Obj_51_RL 8;
BA_ "GenSigSendType" SG_ 874 ARC_OD_ObstacleProb_Obj_50_RL 8;
BA_ "GenSigSendType" SG_ 874 ARC_OD_ObstacleProb_Obj_51_RL 8;
BA_ "GenSigSendType" SG_ 874 ARC_OD_VabsY_Obj_50_RL 8;
BA_ "GenSigSendType" SG_ 874 ARC_OD_ID_50_RL 8;
BA_ "GenSigSendType" SG_ 874 ARC_OD_ID_51_RL 8;
BA_ "GenSigSendType" SG_ 874 ARC_OD_MsgCounter_Obj_50_51_RL 8;
BA_ "GenSigSendType" SG_ 874 ARC_OD_CRC8_Obj_50_51_RL 8;
BA_ "GenSigSendType" SG_ 874 ARC_OD_AabsY_Obj_50_RL 8;
BA_ "GenSigSendType" SG_ 874 ARC_OD_DistXStd_Obj_50_RL 8;
BA_ "GenSigSendType" SG_ 874 ARC_OD_DistYStd_Obj_50_RL 8;
BA_ "GenSigSendType" SG_ 874 ARC_OD_VabsXStd_Obj_50_RL 8;
BA_ "GenSigSendType" SG_ 874 ARC_OD_VabsYStd_Obj_50_RL 8;
BA_ "GenSigSendType" SG_ 874 ARC_OD_AabsXStd_Obj_50_RL 8;
BA_ "GenSigSendType" SG_ 875 DistHeight_Obj_53_RL 8;
BA_ "GenSigSendType" SG_ 875 DistHeight_Obj_52_RL 8;
BA_ "GenSigSendType" SG_ 875 ARC_OD_DistX_Obj_52_RL 8;
BA_ "GenSigSendType" SG_ 875 ARC_OD_Classification_Obj_52_RL 8;
BA_ "GenSigSendType" SG_ 875 ARC_OD_AabsYStd_Obj_52_RL 8;
BA_ "GenSigSendType" SG_ 875 ARC_OD_ClassConf_Obj_52_RL 8;
BA_ "GenSigSendType" SG_ 875 ARC_OD_ProbOfExist_Obj_52_RL 8;
BA_ "GenSigSendType" SG_ 875 ARC_OD_VabsX_Obj_52_RL 8;
BA_ "GenSigSendType" SG_ 875 ARC_OD_DynProp_Obj_52_RL 8;
BA_ "GenSigSendType" SG_ 875 ARC_OD_Length_Obj_52_RL 8;
BA_ "GenSigSendType" SG_ 875 ARC_OD_MaintenanceState_Obj_0113 8;
BA_ "GenSigSendType" SG_ 875 ARC_OD_Width_Obj_52_RL 8;
BA_ "GenSigSendType" SG_ 875 ARC_OD_RCS_Obj_52_RL 8;
BA_ "GenSigSendType" SG_ 875 ARC_OD_Orientation_Obj_52_RL 8;
BA_ "GenSigSendType" SG_ 875 ARC_OD_LifeCycle_Obj_52_RL 8;
BA_ "GenSigSendType" SG_ 875 ARC_OD_DistX_Obj_53_RL 8;
BA_ "GenSigSendType" SG_ 875 ARC_OD_VabsX_Obj_53_RL 8;
BA_ "GenSigSendType" SG_ 875 ARC_OD_AabsX_Obj_53_RL 8;
BA_ "GenSigSendType" SG_ 875 ARC_OD_AabsX_Obj_52_RL 8;
BA_ "GenSigSendType" SG_ 875 ARC_OD_DistY_Obj_53_RL 8;
BA_ "GenSigSendType" SG_ 875 ARC_OD_VabsY_Obj_53_RL 8;
BA_ "GenSigSendType" SG_ 875 ARC_OD_AabsY_Obj_53_RL 8;
BA_ "GenSigSendType" SG_ 875 ARC_OD_DistXStd_Obj_53_RL 8;
BA_ "GenSigSendType" SG_ 875 ARC_OD_DistYStd_Obj_53_RL 8;
BA_ "GenSigSendType" SG_ 875 ARC_OD_VabsXStd_Obj_53_RL 8;
BA_ "GenSigSendType" SG_ 875 ARC_OD_VabsYStd_Obj_53_RL 8;
BA_ "GenSigSendType" SG_ 875 ARC_OD_AabsXStd_Obj_53_RL 8;
BA_ "GenSigSendType" SG_ 875 ARC_OD_Classification_Obj_53_RL 8;
BA_ "GenSigSendType" SG_ 875 ARC_OD_AabsYStd_Obj_53_RL 8;
BA_ "GenSigSendType" SG_ 875 ARC_OD_ClassConf_Obj_53_RL 8;
BA_ "GenSigSendType" SG_ 875 ARC_OD_DistY_Obj_52_RL 8;
BA_ "GenSigSendType" SG_ 875 ARC_OD_ProbOfExist_Obj_53_RL 8;
BA_ "GenSigSendType" SG_ 875 ARC_OD_DynProp_Obj_53_RL 8;
BA_ "GenSigSendType" SG_ 875 ARC_OD_Length_Obj_53_RL 8;
BA_ "GenSigSendType" SG_ 875 ARC_OD_MaintenanceState_Obj_0114 8;
BA_ "GenSigSendType" SG_ 875 ARC_OD_Width_Obj_53_RL 8;
BA_ "GenSigSendType" SG_ 875 ARC_OD_RCS_Obj_53_RL 8;
BA_ "GenSigSendType" SG_ 875 ARC_OD_Orientation_Obj_53_RL 8;
BA_ "GenSigSendType" SG_ 875 ARC_OD_LifeCycle_Obj_53_RL 8;
BA_ "GenSigSendType" SG_ 875 ARC_OD_ObstacleProb_Obj_52_RL 8;
BA_ "GenSigSendType" SG_ 875 ARC_OD_ObstacleProb_Obj_53_RL 8;
BA_ "GenSigSendType" SG_ 875 ARC_OD_VabsY_Obj_52_RL 8;
BA_ "GenSigSendType" SG_ 875 ARC_OD_ID_52_RL 8;
BA_ "GenSigSendType" SG_ 875 ARC_OD_ID_53_RL 8;
BA_ "GenSigSendType" SG_ 875 ARC_OD_MsgCounter_Obj_52_53_RL 8;
BA_ "GenSigSendType" SG_ 875 ARC_OD_CRC8_Obj_52_53_RL 8;
BA_ "GenSigSendType" SG_ 875 ARC_OD_AabsY_Obj_52_RL 8;
BA_ "GenSigSendType" SG_ 875 ARC_OD_DistXStd_Obj_52_RL 8;
BA_ "GenSigSendType" SG_ 875 ARC_OD_DistYStd_Obj_52_RL 8;
BA_ "GenSigSendType" SG_ 875 ARC_OD_VabsXStd_Obj_52_RL 8;
BA_ "GenSigSendType" SG_ 875 ARC_OD_VabsYStd_Obj_52_RL 8;
BA_ "GenSigSendType" SG_ 875 ARC_OD_AabsXStd_Obj_52_RL 8;
BA_ "GenSigSendType" SG_ 876 DistHeight_Obj_55_RL 8;
BA_ "GenSigSendType" SG_ 876 DistHeight_Obj_54_RL 8;
BA_ "GenSigSendType" SG_ 876 ARC_OD_DistX_Obj_54_RL 8;
BA_ "GenSigSendType" SG_ 876 ARC_OD_Classification_Obj_54_RL 8;
BA_ "GenSigSendType" SG_ 876 ARC_OD_AabsYStd_Obj_54_RL 8;
BA_ "GenSigSendType" SG_ 876 ARC_OD_ClassConf_Obj_54_RL 8;
BA_ "GenSigSendType" SG_ 876 ARC_OD_ProbOfExist_Obj_54_RL 8;
BA_ "GenSigSendType" SG_ 876 ARC_OD_VabsX_Obj_54_RL 8;
BA_ "GenSigSendType" SG_ 876 ARC_OD_DynProp_Obj_54_RL 8;
BA_ "GenSigSendType" SG_ 876 ARC_OD_Length_Obj_54_RL 8;
BA_ "GenSigSendType" SG_ 876 ARC_OD_MaintenanceState_Obj_0115 8;
BA_ "GenSigSendType" SG_ 876 ARC_OD_Width_Obj_54_RL 8;
BA_ "GenSigSendType" SG_ 876 ARC_OD_RCS_Obj_54_RL 8;
BA_ "GenSigSendType" SG_ 876 ARC_OD_Orientation_Obj_54_RL 8;
BA_ "GenSigSendType" SG_ 876 ARC_OD_LifeCycle_Obj_54_RL 8;
BA_ "GenSigSendType" SG_ 876 ARC_OD_DistX_Obj_55_RL 8;
BA_ "GenSigSendType" SG_ 876 ARC_OD_VabsX_Obj_55_RL 8;
BA_ "GenSigSendType" SG_ 876 ARC_OD_AabsX_Obj_55_RL 8;
BA_ "GenSigSendType" SG_ 876 ARC_OD_AabsX_Obj_54_RL 8;
BA_ "GenSigSendType" SG_ 876 ARC_OD_DistY_Obj_55_RL 8;
BA_ "GenSigSendType" SG_ 876 ARC_OD_VabsY_Obj_55_RL 8;
BA_ "GenSigSendType" SG_ 876 ARC_OD_AabsY_Obj_55_RL 8;
BA_ "GenSigSendType" SG_ 876 ARC_OD_DistXStd_Obj_55_RL 8;
BA_ "GenSigSendType" SG_ 876 ARC_OD_DistYStd_Obj_55_RL 8;
BA_ "GenSigSendType" SG_ 876 ARC_OD_VabsXStd_Obj_55_RL 8;
BA_ "GenSigSendType" SG_ 876 ARC_OD_VabsYStd_Obj_55_RL 8;
BA_ "GenSigSendType" SG_ 876 ARC_OD_AabsXStd_Obj_55_RL 8;
BA_ "GenSigSendType" SG_ 876 ARC_OD_Classification_Obj_55_RL 8;
BA_ "GenSigSendType" SG_ 876 ARC_OD_AabsYStd_Obj_55_RL 8;
BA_ "GenSigSendType" SG_ 876 ARC_OD_ClassConf_Obj_55_RL 8;
BA_ "GenSigSendType" SG_ 876 ARC_OD_DistY_Obj_54_RL 8;
BA_ "GenSigSendType" SG_ 876 ARC_OD_ProbOfExist_Obj_55_RL 8;
BA_ "GenSigSendType" SG_ 876 ARC_OD_DynProp_Obj_55_RL 8;
BA_ "GenSigSendType" SG_ 876 ARC_OD_Length_Obj_55_RL 8;
BA_ "GenSigSendType" SG_ 876 ARC_OD_MaintenanceState_Obj_0116 8;
BA_ "GenSigSendType" SG_ 876 ARC_OD_Width_Obj_55_RL 8;
BA_ "GenSigSendType" SG_ 876 ARC_OD_RCS_Obj_55_RL 8;
BA_ "GenSigSendType" SG_ 876 ARC_OD_Orientation_Obj_55_RL 8;
BA_ "GenSigSendType" SG_ 876 ARC_OD_LifeCycle_Obj_55_RL 8;
BA_ "GenSigSendType" SG_ 876 ARC_OD_ObstacleProb_Obj_54_RL 8;
BA_ "GenSigSendType" SG_ 876 ARC_OD_ObstacleProb_Obj_55_RL 8;
BA_ "GenSigSendType" SG_ 876 ARC_OD_VabsY_Obj_54_RL 8;
BA_ "GenSigSendType" SG_ 876 ARC_OD_ID_54_RL 8;
BA_ "GenSigSendType" SG_ 876 ARC_OD_ID_55_RL 8;
BA_ "GenSigSendType" SG_ 876 ARC_OD_MsgCounter_Obj_54_55_RL 8;
BA_ "GenSigSendType" SG_ 876 ARC_OD_CRC8_Obj_54_55_RL 8;
BA_ "GenSigSendType" SG_ 876 ARC_OD_AabsY_Obj_54_RL 8;
BA_ "GenSigSendType" SG_ 876 ARC_OD_DistXStd_Obj_54_RL 8;
BA_ "GenSigSendType" SG_ 876 ARC_OD_DistYStd_Obj_54_RL 8;
BA_ "GenSigSendType" SG_ 876 ARC_OD_VabsXStd_Obj_54_RL 8;
BA_ "GenSigSendType" SG_ 876 ARC_OD_VabsYStd_Obj_54_RL 8;
BA_ "GenSigSendType" SG_ 876 ARC_OD_AabsXStd_Obj_54_RL 8;
BA_ "GenSigSendType" SG_ 877 DistHeight_Obj_57_RL 8;
BA_ "GenSigSendType" SG_ 877 DistHeight_Obj_56_RL 8;
BA_ "GenSigSendType" SG_ 877 ARC_OD_DistX_Obj_56_RL 8;
BA_ "GenSigSendType" SG_ 877 ARC_OD_Classification_Obj_56_RL 8;
BA_ "GenSigSendType" SG_ 877 ARC_OD_AabsYStd_Obj_56_RL 8;
BA_ "GenSigSendType" SG_ 877 ARC_OD_ClassConf_Obj_56_RL 8;
BA_ "GenSigSendType" SG_ 877 ARC_OD_ProbOfExist_Obj_56_RL 8;
BA_ "GenSigSendType" SG_ 877 ARC_OD_VabsX_Obj_56_RL 8;
BA_ "GenSigSendType" SG_ 877 ARC_OD_DynProp_Obj_56_RL 8;
BA_ "GenSigSendType" SG_ 877 ARC_OD_Length_Obj_56_RL 8;
BA_ "GenSigSendType" SG_ 877 ARC_OD_MaintenanceState_Obj_0117 8;
BA_ "GenSigSendType" SG_ 877 ARC_OD_Width_Obj_56_RL 8;
BA_ "GenSigSendType" SG_ 877 ARC_OD_RCS_Obj_56_RL 8;
BA_ "GenSigSendType" SG_ 877 ARC_OD_Orientation_Obj_56_RL 8;
BA_ "GenSigSendType" SG_ 877 ARC_OD_LifeCycle_Obj_56_RL 8;
BA_ "GenSigSendType" SG_ 877 ARC_OD_DistX_Obj_57_RL 8;
BA_ "GenSigSendType" SG_ 877 ARC_OD_VabsX_Obj_57_RL 8;
BA_ "GenSigSendType" SG_ 877 ARC_OD_AabsX_Obj_57_RL 8;
BA_ "GenSigSendType" SG_ 877 ARC_OD_AabsX_Obj_56_RL 8;
BA_ "GenSigSendType" SG_ 877 ARC_OD_DistY_Obj_57_RL 8;
BA_ "GenSigSendType" SG_ 877 ARC_OD_VabsY_Obj_57_RL 8;
BA_ "GenSigSendType" SG_ 877 ARC_OD_AabsY_Obj_57_RL 8;
BA_ "GenSigSendType" SG_ 877 ARC_OD_DistXStd_Obj_57_RL 8;
BA_ "GenSigSendType" SG_ 877 ARC_OD_DistYStd_Obj_57_RL 8;
BA_ "GenSigSendType" SG_ 877 ARC_OD_VabsXStd_Obj_57_RL 8;
BA_ "GenSigSendType" SG_ 877 ARC_OD_VabsYStd_Obj_57_RL 8;
BA_ "GenSigSendType" SG_ 877 ARC_OD_AabsXStd_Obj_57_RL 8;
BA_ "GenSigSendType" SG_ 877 ARC_OD_Classification_Obj_57_RL 8;
BA_ "GenSigSendType" SG_ 877 ARC_OD_AabsYStd_Obj_57_RL 8;
BA_ "GenSigSendType" SG_ 877 ARC_OD_ClassConf_Obj_57_RL 8;
BA_ "GenSigSendType" SG_ 877 ARC_OD_DistY_Obj_56_RL 8;
BA_ "GenSigSendType" SG_ 877 ARC_OD_ProbOfExist_Obj_57_RL 8;
BA_ "GenSigSendType" SG_ 877 ARC_OD_DynProp_Obj_57_RL 8;
BA_ "GenSigSendType" SG_ 877 ARC_OD_Length_Obj_57_RL 8;
BA_ "GenSigSendType" SG_ 877 ARC_OD_MaintenanceState_Obj_0118 8;
BA_ "GenSigSendType" SG_ 877 ARC_OD_Width_Obj_57_RL 8;
BA_ "GenSigSendType" SG_ 877 ARC_OD_RCS_Obj_57_RL 8;
BA_ "GenSigSendType" SG_ 877 ARC_OD_Orientation_Obj_57_RL 8;
BA_ "GenSigSendType" SG_ 877 ARC_OD_LifeCycle_Obj_57_RL 8;
BA_ "GenSigSendType" SG_ 877 ARC_OD_ObstacleProb_Obj_56_RL 8;
BA_ "GenSigSendType" SG_ 877 ARC_OD_ObstacleProb_Obj_57_RL 8;
BA_ "GenSigSendType" SG_ 877 ARC_OD_VabsY_Obj_56_RL 8;
BA_ "GenSigSendType" SG_ 877 ARC_OD_ID_56_RL 8;
BA_ "GenSigSendType" SG_ 877 ARC_OD_ID_57_RL 8;
BA_ "GenSigSendType" SG_ 877 ARC_OD_MsgCounter_Obj_56_57_RL 8;
BA_ "GenSigSendType" SG_ 877 ARC_OD_CRC8_Obj_56_57_RL 8;
BA_ "GenSigSendType" SG_ 877 ARC_OD_AabsY_Obj_56_RL 8;
BA_ "GenSigSendType" SG_ 877 ARC_OD_DistXStd_Obj_56_RL 8;
BA_ "GenSigSendType" SG_ 877 ARC_OD_DistYStd_Obj_56_RL 8;
BA_ "GenSigSendType" SG_ 877 ARC_OD_VabsXStd_Obj_56_RL 8;
BA_ "GenSigSendType" SG_ 877 ARC_OD_VabsYStd_Obj_56_RL 8;
BA_ "GenSigSendType" SG_ 877 ARC_OD_AabsXStd_Obj_56_RL 8;
BA_ "GenSigSendType" SG_ 878 DistHeight_Obj_59_RL 8;
BA_ "GenSigSendType" SG_ 878 DistHeight_Obj_58_RL 8;
BA_ "GenSigSendType" SG_ 878 ARC_OD_DistX_Obj_58_RL 8;
BA_ "GenSigSendType" SG_ 878 ARC_OD_Classification_Obj_58_RL 8;
BA_ "GenSigSendType" SG_ 878 ARC_OD_AabsYStd_Obj_58_RL 8;
BA_ "GenSigSendType" SG_ 878 ARC_OD_ClassConf_Obj_58_RL 8;
BA_ "GenSigSendType" SG_ 878 ARC_OD_ProbOfExist_Obj_58_RL 8;
BA_ "GenSigSendType" SG_ 878 ARC_OD_VabsX_Obj_58_RL 8;
BA_ "GenSigSendType" SG_ 878 ARC_OD_DynProp_Obj_58_RL 8;
BA_ "GenSigSendType" SG_ 878 ARC_OD_Length_Obj_58_RL 8;
BA_ "GenSigSendType" SG_ 878 ARC_OD_MaintenanceState_Obj_0119 8;
BA_ "GenSigSendType" SG_ 878 ARC_OD_Width_Obj_58_RL 8;
BA_ "GenSigSendType" SG_ 878 ARC_OD_RCS_Obj_58_RL 8;
BA_ "GenSigSendType" SG_ 878 ARC_OD_Orientation_Obj_58_RL 8;
BA_ "GenSigSendType" SG_ 878 ARC_OD_LifeCycle_Obj_58_RL 8;
BA_ "GenSigSendType" SG_ 878 ARC_OD_DistX_Obj_59_RL 8;
BA_ "GenSigSendType" SG_ 878 ARC_OD_VabsX_Obj_59_RL 8;
BA_ "GenSigSendType" SG_ 878 ARC_OD_AabsX_Obj_59_RL 8;
BA_ "GenSigSendType" SG_ 878 ARC_OD_AabsX_Obj_58_RL 8;
BA_ "GenSigSendType" SG_ 878 ARC_OD_DistY_Obj_59_RL 8;
BA_ "GenSigSendType" SG_ 878 ARC_OD_VabsY_Obj_59_RL 8;
BA_ "GenSigSendType" SG_ 878 ARC_OD_AabsY_Obj_59_RL 8;
BA_ "GenSigSendType" SG_ 878 ARC_OD_DistXStd_Obj_59_RL 8;
BA_ "GenSigSendType" SG_ 878 ARC_OD_DistYStd_Obj_59_RL 8;
BA_ "GenSigSendType" SG_ 878 ARC_OD_VabsXStd_Obj_59_RL 8;
BA_ "GenSigSendType" SG_ 878 ARC_OD_VabsYStd_Obj_59_RL 8;
BA_ "GenSigSendType" SG_ 878 ARC_OD_AabsXStd_Obj_59_RL 8;
BA_ "GenSigSendType" SG_ 878 ARC_OD_Classification_Obj_59_RL 8;
BA_ "GenSigSendType" SG_ 878 ARC_OD_AabsYStd_Obj_59_RL 8;
BA_ "GenSigSendType" SG_ 878 ARC_OD_ClassConf_Obj_59_RL 8;
BA_ "GenSigSendType" SG_ 878 ARC_OD_DistY_Obj_58_RL 8;
BA_ "GenSigSendType" SG_ 878 ARC_OD_ProbOfExist_Obj_59_RL 8;
BA_ "GenSigSendType" SG_ 878 ARC_OD_DynProp_Obj_59_RL 8;
BA_ "GenSigSendType" SG_ 878 ARC_OD_Length_Obj_59_RL 8;
BA_ "GenSigSendType" SG_ 878 ARC_OD_MaintenanceState_Obj_0120 8;
BA_ "GenSigSendType" SG_ 878 ARC_OD_Width_Obj_59_RL 8;
BA_ "GenSigSendType" SG_ 878 ARC_OD_RCS_Obj_59_RL 8;
BA_ "GenSigSendType" SG_ 878 ARC_OD_Orientation_Obj_59_RL 8;
BA_ "GenSigSendType" SG_ 878 ARC_OD_LifeCycle_Obj_59_RL 8;
BA_ "GenSigSendType" SG_ 878 ARC_OD_ObstacleProb_Obj_58_RL 8;
BA_ "GenSigSendType" SG_ 878 ARC_OD_ObstacleProb_Obj_59_RL 8;
BA_ "GenSigSendType" SG_ 878 ARC_OD_VabsY_Obj_58_RL 8;
BA_ "GenSigSendType" SG_ 878 ARC_OD_ID_58_RL 8;
BA_ "GenSigSendType" SG_ 878 ARC_OD_ID_59_RL 8;
BA_ "GenSigSendType" SG_ 878 ARC_OD_MsgCounter_Obj_58_59_RL 8;
BA_ "GenSigSendType" SG_ 878 ARC_OD_CRC8_Obj_58_59_RL 8;
BA_ "GenSigSendType" SG_ 878 ARC_OD_AabsY_Obj_58_RL 8;
BA_ "GenSigSendType" SG_ 878 ARC_OD_DistXStd_Obj_58_RL 8;
BA_ "GenSigSendType" SG_ 878 ARC_OD_DistYStd_Obj_58_RL 8;
BA_ "GenSigSendType" SG_ 878 ARC_OD_VabsXStd_Obj_58_RL 8;
BA_ "GenSigSendType" SG_ 878 ARC_OD_VabsYStd_Obj_58_RL 8;
BA_ "GenSigSendType" SG_ 878 ARC_OD_AabsXStd_Obj_58_RL 8;
BA_ "GenSigSendType" SG_ 266 ESC_FrP02_10A_CRC 8;
BA_ "GenSigSendType" SG_ 266 ESC_FrP02_10A_RC 8;
BA_ "GenSigSendType" SG_ 266 ESC_RLWhlSpdV 8;
BA_ "GenSigStartValue" SG_ 266 ESC_RLWhlSpdV 1;
BA_ "GenSigSendType" SG_ 266 ESC_RLWhlDir 8;
BA_ "GenSigStartValue" SG_ 266 ESC_RLWhlDir 3;
BA_ "GenSigSendType" SG_ 266 ESC_RLWhlSpd 8;
BA_ "GenSigSendType" SG_ 266 ESC_RRWhlSpdV 8;
BA_ "GenSigStartValue" SG_ 266 ESC_RRWhlSpdV 1;
BA_ "GenSigSendType" SG_ 266 ESC_RRWhlDir 8;
BA_ "GenSigStartValue" SG_ 266 ESC_RRWhlDir 3;
BA_ "GenSigSendType" SG_ 266 ESC_RRWhlSpd 8;
BA_ "GenSigSendType" SG_ 266 ESC_RRWhlDirV 8;
BA_ "GenSigSendType" SG_ 266 ESC_RLWhlDirV 8;
BA_ "GenSigSendType" SG_ 268 ESC_FrP04_10C_CRC 8;
BA_ "GenSigSendType" SG_ 268 ESC_FrP04_10C_RC 8;
BA_ "GenSigSendType" SG_ 268 ESC_FRWhlSpdV 8;
BA_ "GenSigStartValue" SG_ 268 ESC_FRWhlSpdV 1;
BA_ "GenSigSendType" SG_ 268 ESC_FRWhlDir 8;
BA_ "GenSigStartValue" SG_ 268 ESC_FRWhlDir 3;
BA_ "GenSigSendType" SG_ 268 ESC_FRWhlSpd 8;
BA_ "GenSigSendType" SG_ 268 ESC_FLWhlSpdV 8;
BA_ "GenSigStartValue" SG_ 268 ESC_FLWhlSpdV 1;
BA_ "GenSigSendType" SG_ 268 ESC_FLWhlDir 8;
BA_ "GenSigStartValue" SG_ 268 ESC_FLWhlDir 3;
BA_ "GenSigSendType" SG_ 268 ESC_FLWhlSpd 8;
BA_ "GenSigSendType" SG_ 268 ESC_FRWhlDirV 8;
BA_ "GenSigStartValue" SG_ 268 ESC_FRWhlDirV 1;
BA_ "GenSigSendType" SG_ 268 ESC_FLWhlDirV 8;
BA_ "GenSigStartValue" SG_ 268 ESC_FLWhlDirV 1;
BA_ "GenSigSendType" SG_ 271 ESC_LatSenSts 8;
BA_ "GenSigSendType" SG_ 271 ESC_YRSenSts 8;
BA_ "GenSigSendType" SG_ 271 ESC_LgtSenSt 8;
BA_ "GenSigSendType" SG_ 271 ESC_YR 8;
BA_ "GenSigStartValue" SG_ 271 ESC_YR 30000;
BA_ "GenSigSendType" SG_ 271 ESC_LatAccelSenVal 8;
BA_ "GenSigStartValue" SG_ 271 ESC_LatAccelSenVal 30000;
BA_ "GenSigSendType" SG_ 271 ESC_LgtAccel 8;
BA_ "GenSigStartValue" SG_ 271 ESC_LgtAccel 6000;
BA_ "GenSigSendType" SG_ 277 EPS_FrP01_115_CRC 8;
BA_ "GenSigSendType" SG_ 277 EPS_FrP01_115_RC 8;
BA_ "GenSigSendType" SG_ 277 EPS_StrgWhlAngl 8;
BA_ "GenSigStartValue" SG_ 277 EPS_StrgWhlAngl 32768;
BA_ "GenSigSendType" SG_ 277 EPS_StrgAnglSpd 8;
BA_ "GenSigSendType" SG_ 277 EPS_StrgAnglSpdV 8;
BA_ "GenSigSendType" SG_ 277 EPS_StrgWhlAnglV 8;
BA_ "GenSigSendType" SG_ 277 EPS_StrgWhlAnglSenCalSts 8;
BA_ "GenSigSendType" SG_ 805 ESC_VehSpd 8;
BA_ "GenSigSendType" SG_ 805 ESC_VehSpdV 8;
BA_ "GenSigSendType" SG_ 805 ESC_VDCCtrlActv 8;
BA_ "GenSigSendType" SG_ 834 ICM_VehSpdDispV 8;
BA_ "GenSigStartValue" SG_ 834 ICM_VehSpdDispV 1;
BA_ "GenSigSendType" SG_ 834 ICM_TotOdoV 8;
BA_ "GenSigSendType" SG_ 834 ICM_VehSpdDisp 8;
BA_ "GenSigSendType" SG_ 834 ICM_TotOdo 8;
BA_ "GenSigSendType" SG_ 819 Sync_Counter 8;
BA_ "GenSigSendType" SG_ 819 Sync_CRC 8;
BA_ "GenSigSendType" SG_ 819 Sync_OVS 8;
BA_ "GenSigSendType" SG_ 819 Sync_Resd 8;
BA_ "GenSigSendType" SG_ 819 Sync_SGW 8;
BA_ "GenSigSendType" SG_ 819 Sync_SyncTime 8;
BA_ "GenSigSendType" SG_ 819 Sync_TimeDomain 8;
BA_ "GenSigSendType" SG_ 819 Sync_Type 8;
BA_ "GenSigSendType" SG_ 267 ESC_FrP03_10B_CRC_1 8;
BA_ "GenSigSendType" SG_ 267 ESC_EBDActv 8;
BA_ "GenSigSendType" SG_ 267 ESC_FrP03_10B_RC_1 8;
BA_ "GenSigSendType" SG_ 267 ESC_TCSActv 8;
BA_ "GenSigSendType" SG_ 267 ESC_ABSActv 8;
BA_ "GenSigSendType" SG_ 267 ESC_ESCFld 8;
BA_ "GenSigSendType" SG_ 267 ESC_CDPActv 8;
BA_ "GenSigSendType" SG_ 267 ESC_HDCSts 8;
BA_ "GenSigSendType" SG_ 267 ESC_Off 8;
BA_ "GenSigStartValue" SG_ 267 ESC_Off 1;
BA_ "GenSigSendType" SG_ 267 ESC_ABAAvlbl 8;
BA_ "GenSigSendType" SG_ 267 ESC_ABAActv 8;
BA_ "GenSigSendType" SG_ 267 ESC_FrP03_10B_CRC_3 8;
BA_ "GenSigSendType" SG_ 267 ESC_FrP03_10B_RC_3 8;
BA_ "GenSigSendType" SG_ 267 ESC_FrP03_10B_CRC_4 8;
BA_ "GenSigSendType" SG_ 267 ESC_FrP03_10B_RC_4 8;
BA_ "GenSigSendType" SG_ 267 ESC_FrP03_10B_CRC_2 8;
BA_ "GenSigSendType" SG_ 267 ESC_FrP03_10B_RC_2 8;
BA_ "GenSigSendType" SG_ 269 ESC_VehStdslSts 8;
BA_ "GenSigSendType" SG_ 269 ESC_VehStdslStsV 8;
BA_ "GenSigSendType" SG_ 181 EHB_BrkPedlAppld 8;
BA_ "GenSigSendType" SG_ 181 EHB_BrkPedlAppldSts 8;
BA_ "GenSigSendType" SG_ 181 EHB_CtrlrFltSts 8;
BA_ "GenSigSendType" SG_ 181 EHB_FrP01_B5_CRC 8;
BA_ "GenSigSendType" SG_ 181 EHB_FrP01_B5_RC 8;
VAL_ 856 ARC_OD_Classification_Obj_14_RL 0 "Unknow" 1 "Person" 2 "Bimo" 3 "Car" 4 "Truck" 5 "Barrier" 6 "Reserved" 7 "Reserved";
VAL_ 856 ARC_OD_DynProp_Obj_14_RL 0 "MOVING" 1 "STATIONARY" 2 "ONCOMING" 3 "CROSSING_LEFT2RIGHT" 4 "CROSSING_RIGHT2LEFT" 5 "UNKNOWN" 6 "STOPPED" 7 "RESERVED";
VAL_ 856 ARC_OD_MaintenanceState_Obj_0075 0 "INVALID" 1 "NEW" 2 "MEASURED" 3 "PREDICTED";
VAL_ 856 ARC_OD_Classification_Obj_15_RL 0 "Unknow" 1 "Person" 2 "Bimo" 3 "Car" 4 "Truck" 5 "Barrier" 6 "Reserved" 7 "Reserved";
VAL_ 856 ARC_OD_DynProp_Obj_15_RL 0 "STATIONAR" 1 "MOVIN" 2 "ONCOMING" 3 "STOPPE" 4 "CROSSING_LEFT2RIGH" 5 "CROSSING_RIGHT2LEF" 6 "RESERVE" 7 "RESERVED";
VAL_ 856 ARC_OD_MaintenanceState_Obj_0076 0 "INVALID" 1 "NEW" 2 "MEASURED" 3 "PREDICTED";
VAL_ 857 ARC_OD_Classification_Obj_16_RL 0 "Unknow" 1 "Person" 2 "Bimo" 3 "Car" 4 "Truck" 5 "Barrier" 6 "Reserved" 7 "Reserved";
VAL_ 857 ARC_OD_DynProp_Obj_16_RL 0 "MOVING" 1 "STATIONARY" 2 "ONCOMING" 3 "CROSSING_LEFT2RIGHT" 4 "CROSSING_RIGHT2LEFT" 5 "UNKNOWN" 6 "STOPPED" 7 "RESERVED";
VAL_ 857 ARC_OD_MaintenanceState_Obj_0077 0 "INVALID" 1 "NEW" 2 "MEASURED" 3 "PREDICTED";
VAL_ 857 ARC_OD_Classification_Obj_17_RL 0 "Unknow" 1 "Person" 2 "Bimo" 3 "Car" 4 "Truck" 5 "Barrier" 6 "Reserved" 7 "Reserved";
VAL_ 857 ARC_OD_DynProp_Obj_17_RL 0 "STATIONAR" 1 "MOVIN" 2 "ONCOMING" 3 "STOPPE" 4 "CROSSING_LEFT2RIGH" 5 "CROSSING_RIGHT2LEF" 6 "RESERVE" 7 "RESERVED";
VAL_ 857 ARC_OD_MaintenanceState_Obj_0078 0 "INVALID" 1 "NEW" 2 "MEASURED" 3 "PREDICTED";
VAL_ 858 ARC_OD_Classification_Obj_18_RL 0 "Unknow" 1 "Person" 2 "Bimo" 3 "Car" 4 "Truck" 5 "Barrier" 6 "Reserved" 7 "Reserved";
VAL_ 858 ARC_OD_DynProp_Obj_18_RL 0 "MOVING" 1 "STATIONARY" 2 "ONCOMING" 3 "CROSSING_LEFT2RIGHT" 4 "CROSSING_RIGHT2LEFT" 5 "UNKNOWN" 6 "STOPPED" 7 "RESERVED";
VAL_ 858 ARC_OD_MaintenanceState_Obj_0079 0 "INVALID" 1 "NEW" 2 "MEASURED" 3 "PREDICTED";
VAL_ 858 ARC_OD_Classification_Obj_19_RL 0 "Unknow" 1 "Person" 2 "Bimo" 3 "Car" 4 "Truck" 5 "Barrier" 6 "Reserved" 7 "Reserved";
VAL_ 858 ARC_OD_DynProp_Obj_19_RL 0 "STATIONAR" 1 "MOVIN" 2 "ONCOMING" 3 "STOPPE" 4 "CROSSING_LEFT2RIGH" 5 "CROSSING_RIGHT2LEF" 6 "RESERVE" 7 "RESERVED";
VAL_ 858 ARC_OD_MaintenanceState_Obj_0080 0 "INVALID" 1 "NEW" 2 "MEASURED" 3 "PREDICTED";
VAL_ 859 ARC_OD_Classification_Obj_20_RL 0 "Unknow" 1 "Person" 2 "Bimo" 3 "Car" 4 "Truck" 5 "Barrier" 6 "Reserved" 7 "Reserved";
VAL_ 859 ARC_OD_DynProp_Obj_20_RL 0 "MOVING" 1 "STATIONARY" 2 "ONCOMING" 3 "CROSSING_LEFT2RIGHT" 4 "CROSSING_RIGHT2LEFT" 5 "UNKNOWN" 6 "STOPPED" 7 "RESERVED";
VAL_ 859 ARC_OD_MaintenanceState_Obj_0081 0 "INVALID" 1 "NEW" 2 "MEASURED" 3 "PREDICTED";
VAL_ 859 ARC_OD_Classification_Obj_21_RL 0 "Unknow" 1 "Person" 2 "Bimo" 3 "Car" 4 "Truck" 5 "Barrier" 6 "Reserved" 7 "Reserved";
VAL_ 859 ARC_OD_DynProp_Obj_21_RL 0 "STATIONAR" 1 "MOVIN" 2 "ONCOMING" 3 "STOPPE" 4 "CROSSING_LEFT2RIGH" 5 "CROSSING_RIGHT2LEF" 6 "RESERVE" 7 "RESERVED";
VAL_ 859 ARC_OD_MaintenanceState_Obj_0082 0 "INVALID" 1 "NEW" 2 "MEASURED" 3 "PREDICTED";
VAL_ 860 ARC_OD_Classification_Obj_22_RL 0 "Unknow" 1 "Person" 2 "Bimo" 3 "Car" 4 "Truck" 5 "Barrier" 6 "Reserved" 7 "Reserved";
VAL_ 860 ARC_OD_DynProp_Obj_22_RL 0 "MOVING" 1 "STATIONARY" 2 "ONCOMING" 3 "CROSSING_LEFT2RIGHT" 4 "CROSSING_RIGHT2LEFT" 5 "UNKNOWN" 6 "STOPPED" 7 "RESERVED";
VAL_ 860 ARC_OD_MaintenanceState_Obj_0083 0 "INVALID" 1 "NEW" 2 "MEASURED" 3 "PREDICTED";
VAL_ 860 ARC_OD_Classification_Obj_23_RL 0 "Unknow" 1 "Person" 2 "Bimo" 3 "Car" 4 "Truck" 5 "Barrier" 6 "Reserved" 7 "Reserved";
VAL_ 860 ARC_OD_DynProp_Obj_23_RL 0 "STATIONAR" 1 "MOVIN" 2 "ONCOMING" 3 "STOPPE" 4 "CROSSING_LEFT2RIGH" 5 "CROSSING_RIGHT2LEF" 6 "RESERVE" 7 "RESERVED";
VAL_ 860 ARC_OD_MaintenanceState_Obj_0084 0 "INVALID" 1 "NEW" 2 "MEASURED" 3 "PREDICTED";
VAL_ 861 ARC_OD_Classification_Obj_24_RL 0 "Unknow" 1 "Person" 2 "Bimo" 3 "Car" 4 "Truck" 5 "Barrier" 6 "Reserved" 7 "Reserved";
VAL_ 861 ARC_OD_DynProp_Obj_24_RL 0 "MOVING" 1 "STATIONARY" 2 "ONCOMING" 3 "CROSSING_LEFT2RIGHT" 4 "CROSSING_RIGHT2LEFT" 5 "UNKNOWN" 6 "STOPPED" 7 "RESERVED";
VAL_ 861 ARC_OD_MaintenanceState_Obj_0085 0 "INVALID" 1 "NEW" 2 "MEASURED" 3 "PREDICTED";
VAL_ 861 ARC_OD_Classification_Obj_25_RL 0 "Unknow" 1 "Person" 2 "Bimo" 3 "Car" 4 "Truck" 5 "Barrier" 6 "Reserved" 7 "Reserved";
VAL_ 861 ARC_OD_DynProp_Obj_25_RL 0 "STATIONAR" 1 "MOVIN" 2 "ONCOMING" 3 "STOPPE" 4 "CROSSING_LEFT2RIGH" 5 "CROSSING_RIGHT2LEF" 6 "RESERVE" 7 "RESERVED";
VAL_ 861 ARC_OD_MaintenanceState_Obj_0086 0 "INVALID" 1 "NEW" 2 "MEASURED" 3 "PREDICTED";
VAL_ 862 ARC_OD_Classification_Obj_26_RL 0 "Unknow" 1 "Person" 2 "Bimo" 3 "Car" 4 "Truck" 5 "Barrier" 6 "Reserved" 7 "Reserved";
VAL_ 862 ARC_OD_DynProp_Obj_26_RL 0 "MOVING" 1 "STATIONARY" 2 "ONCOMING" 3 "CROSSING_LEFT2RIGHT" 4 "CROSSING_RIGHT2LEFT" 5 "UNKNOWN" 6 "STOPPED" 7 "RESERVED";
VAL_ 862 ARC_OD_MaintenanceState_Obj_0087 0 "INVALID" 1 "NEW" 2 "MEASURED" 3 "PREDICTED";
VAL_ 862 ARC_OD_Classification_Obj_27_RL 0 "Unknow" 1 "Person" 2 "Bimo" 3 "Car" 4 "Truck" 5 "Barrier" 6 "Reserved" 7 "Reserved";
VAL_ 862 ARC_OD_DynProp_Obj_27_RL 0 "STATIONAR" 1 "MOVIN" 2 "ONCOMING" 3 "STOPPE" 4 "CROSSING_LEFT2RIGH" 5 "CROSSING_RIGHT2LEF" 6 "RESERVE" 7 "RESERVED";
VAL_ 862 ARC_OD_MaintenanceState_Obj_0088 0 "INVALID" 1 "NEW" 2 "MEASURED" 3 "PREDICTED";
VAL_ 863 ARC_OD_Classification_Obj_28_RL 0 "Unknow" 1 "Person" 2 "Bimo" 3 "Car" 4 "Truck" 5 "Barrier" 6 "Reserved" 7 "Reserved";
VAL_ 863 ARC_OD_DynProp_Obj_28_RL 0 "MOVING" 1 "STATIONARY" 2 "ONCOMING" 3 "CROSSING_LEFT2RIGHT" 4 "CROSSING_RIGHT2LEFT" 5 "UNKNOWN" 6 "STOPPED" 7 "RESERVED";
VAL_ 863 ARC_OD_MaintenanceState_Obj_0089 0 "INVALID" 1 "NEW" 2 "MEASURED" 3 "PREDICTED";
VAL_ 863 ARC_OD_Classification_Obj_29_RL 0 "Unknow" 1 "Person" 2 "Bimo" 3 "Car" 4 "Truck" 5 "Barrier" 6 "Reserved" 7 "Reserved";
VAL_ 863 ARC_OD_DynProp_Obj_29_RL 0 "STATIONAR" 1 "MOVIN" 2 "ONCOMING" 3 "STOPPE" 4 "CROSSING_LEFT2RIGH" 5 "CROSSING_RIGHT2LEF" 6 "RESERVE" 7 "RESERVED";
VAL_ 863 ARC_OD_MaintenanceState_Obj_0090 0 "INVALID" 1 "NEW" 2 "MEASURED" 3 "PREDICTED";
VAL_ 864 ARC_OD_Classification_Obj_30_RL 0 "Unknow" 1 "Person" 2 "Bimo" 3 "Car" 4 "Truck" 5 "Barrier" 6 "Reserved" 7 "Reserved";
VAL_ 864 ARC_OD_DynProp_Obj_30_RL 0 "MOVING" 1 "STATIONARY" 2 "ONCOMING" 3 "CROSSING_LEFT2RIGHT" 4 "CROSSING_RIGHT2LEFT" 5 "UNKNOWN" 6 "STOPPED" 7 "RESERVED";
VAL_ 864 ARC_OD_MaintenanceState_Obj_0091 0 "INVALID" 1 "NEW" 2 "MEASURED" 3 "PREDICTED";
VAL_ 864 ARC_OD_Classification_Obj_31_RL 0 "Unknow" 1 "Person" 2 "Bimo" 3 "Car" 4 "Truck" 5 "Barrier" 6 "Reserved" 7 "Reserved";
VAL_ 864 ARC_OD_DynProp_Obj_31_RL 0 "STATIONAR" 1 "MOVIN" 2 "ONCOMING" 3 "STOPPE" 4 "CROSSING_LEFT2RIGH" 5 "CROSSING_RIGHT2LEF" 6 "RESERVE" 7 "RESERVED";
VAL_ 864 ARC_OD_MaintenanceState_Obj_0092 0 "INVALID" 1 "NEW" 2 "MEASURED" 3 "PREDICTED";
VAL_ 865 ARC_OD_Classification_Obj_32_RL 0 "Unknow" 1 "Person" 2 "Bimo" 3 "Car" 4 "Truck" 5 "Barrier" 6 "Reserved" 7 "Reserved";
VAL_ 865 ARC_OD_DynProp_Obj_32_RL 0 "MOVING" 1 "STATIONARY" 2 "ONCOMING" 3 "CROSSING_LEFT2RIGHT" 4 "CROSSING_RIGHT2LEFT" 5 "UNKNOWN" 6 "STOPPED" 7 "RESERVED";
VAL_ 865 ARC_OD_MaintenanceState_Obj_0093 0 "INVALID" 1 "NEW" 2 "MEASURED" 3 "PREDICTED";
VAL_ 865 ARC_OD_Classification_Obj_33_RL 0 "Unknow" 1 "Person" 2 "Bimo" 3 "Car" 4 "Truck" 5 "Barrier" 6 "Reserved" 7 "Reserved";
VAL_ 865 ARC_OD_DynProp_Obj_33_RL 0 "STATIONAR" 1 "MOVIN" 2 "ONCOMING" 3 "STOPPE" 4 "CROSSING_LEFT2RIGH" 5 "CROSSING_RIGHT2LEF" 6 "RESERVE" 7 "RESERVED";
VAL_ 865 ARC_OD_MaintenanceState_Obj_0094 0 "INVALID" 1 "NEW" 2 "MEASURED" 3 "PREDICTED";
VAL_ 866 ARC_OD_Classification_Obj_34_RL 0 "Unknow" 1 "Person" 2 "Bimo" 3 "Car" 4 "Truck" 5 "Barrier" 6 "Reserved" 7 "Reserved";
VAL_ 866 ARC_OD_DynProp_Obj_34_RL 0 "MOVING" 1 "STATIONARY" 2 "ONCOMING" 3 "CROSSING_LEFT2RIGHT" 4 "CROSSING_RIGHT2LEFT" 5 "UNKNOWN" 6 "STOPPED" 7 "RESERVED";
VAL_ 866 ARC_OD_MaintenanceState_Obj_0095 0 "INVALID" 1 "NEW" 2 "MEASURED" 3 "PREDICTED";
VAL_ 866 ARC_OD_Classification_Obj_35_RL 0 "Unknow" 1 "Person" 2 "Bimo" 3 "Car" 4 "Truck" 5 "Barrier" 6 "Reserved" 7 "Reserved";
VAL_ 866 ARC_OD_DynProp_Obj_35_RL 0 "STATIONAR" 1 "MOVIN" 2 "ONCOMING" 3 "STOPPE" 4 "CROSSING_LEFT2RIGH" 5 "CROSSING_RIGHT2LEF" 6 "RESERVE" 7 "RESERVED";
VAL_ 866 ARC_OD_MaintenanceState_Obj_0096 0 "INVALID" 1 "NEW" 2 "MEASURED" 3 "PREDICTED";
VAL_ 867 ARC_OD_Classification_Obj_36_RL 0 "Unknow" 1 "Person" 2 "Bimo" 3 "Car" 4 "Truck" 5 "Barrier" 6 "Reserved" 7 "Reserved";
VAL_ 867 ARC_OD_DynProp_Obj_36_RL 0 "MOVING" 1 "STATIONARY" 2 "ONCOMING" 3 "CROSSING_LEFT2RIGHT" 4 "CROSSING_RIGHT2LEFT" 5 "UNKNOWN" 6 "STOPPED" 7 "RESERVED";
VAL_ 867 ARC_OD_MaintenanceState_Obj_0097 0 "INVALID" 1 "NEW" 2 "MEASURED" 3 "PREDICTED";
VAL_ 867 ARC_OD_Classification_Obj_37_RL 0 "Unknow" 1 "Person" 2 "Bimo" 3 "Car" 4 "Truck" 5 "Barrier" 6 "Reserved" 7 "Reserved";
VAL_ 867 ARC_OD_DynProp_Obj_37_RL 0 "STATIONAR" 1 "MOVIN" 2 "ONCOMING" 3 "STOPPE" 4 "CROSSING_LEFT2RIGH" 5 "CROSSING_RIGHT2LEF" 6 "RESERVE" 7 "RESERVED";
VAL_ 867 ARC_OD_MaintenanceState_Obj_0098 0 "INVALID" 1 "NEW" 2 "MEASURED" 3 "PREDICTED";
VAL_ 868 ARC_OD_Classification_Obj_38_RL 0 "Unknow" 1 "Person" 2 "Bimo" 3 "Car" 4 "Truck" 5 "Barrier" 6 "Reserved" 7 "Reserved";
VAL_ 868 ARC_OD_DynProp_Obj_38_RL 0 "MOVING" 1 "STATIONARY" 2 "ONCOMING" 3 "CROSSING_LEFT2RIGHT" 4 "CROSSING_RIGHT2LEFT" 5 "UNKNOWN" 6 "STOPPED" 7 "RESERVED";
VAL_ 868 ARC_OD_MaintenanceState_Obj_0099 0 "INVALID" 1 "NEW" 2 "MEASURED" 3 "PREDICTED";
VAL_ 868 ARC_OD_Classification_Obj_39_RL 0 "Unknow" 1 "Person" 2 "Bimo" 3 "Car" 4 "Truck" 5 "Barrier" 6 "Reserved" 7 "Reserved";
VAL_ 868 ARC_OD_DynProp_Obj_39_RL 0 "STATIONAR" 1 "MOVIN" 2 "ONCOMING" 3 "STOPPE" 4 "CROSSING_LEFT2RIGH" 5 "CROSSING_RIGHT2LEF" 6 "RESERVE" 7 "RESERVED";
VAL_ 868 ARC_OD_MaintenanceState_Obj_0100 0 "INVALID" 1 "NEW" 2 "MEASURED" 3 "PREDICTED";
VAL_ 869 ARC_OD_Classification_Obj_40_RL 0 "Unknow" 1 "Person" 2 "Bimo" 3 "Car" 4 "Truck" 5 "Barrier" 6 "Reserved" 7 "Reserved";
VAL_ 869 ARC_OD_DynProp_Obj_40_RL 0 "MOVING" 1 "STATIONARY" 2 "ONCOMING" 3 "CROSSING_LEFT2RIGHT" 4 "CROSSING_RIGHT2LEFT" 5 "UNKNOWN" 6 "STOPPED" 7 "RESERVED";
VAL_ 869 ARC_OD_MaintenanceState_Obj_0101 0 "INVALID" 1 "NEW" 2 "MEASURED" 3 "PREDICTED";
VAL_ 869 ARC_OD_Classification_Obj_41_RL 0 "Unknow" 1 "Person" 2 "Bimo" 3 "Car" 4 "Truck" 5 "Barrier" 6 "Reserved" 7 "Reserved";
VAL_ 869 ARC_OD_DynProp_Obj_41_RL 0 "STATIONAR" 1 "MOVIN" 2 "ONCOMING" 3 "STOPPE" 4 "CROSSING_LEFT2RIGH" 5 "CROSSING_RIGHT2LEF" 6 "RESERVE" 7 "RESERVED";
VAL_ 869 ARC_OD_MaintenanceState_Obj_0102 0 "INVALID" 1 "NEW" 2 "MEASURED" 3 "PREDICTED";
VAL_ 870 ARC_OD_Classification_Obj_42_RL 0 "POINT" 1 "CAR" 2 "TRUCK" 3 "PEDESTRIAN" 4 "MOTORCYCLE" 5 "BICYCLE" 6 "WIDE" 7 "UNCLASSIFIED";
VAL_ 870 ARC_OD_DynProp_Obj_42_RL 0 "MOVING" 1 "STATIONARY" 2 "ONCOMING" 3 "CROSSING_LEFT2RIGHT" 4 "CROSSING_RIGHT2LEFT" 5 "UNKNOWN" 6 "STOPPED" 7 "RESERVED";
VAL_ 870 ARC_OD_MaintenanceState_Obj_0103 0 "INVALID" 1 "NEW" 2 "MEASURED" 3 "PREDICTED";
VAL_ 870 ARC_OD_Classification_Obj_43_RL 0 "POINT" 1 "CAR" 2 "TRUCK" 3 "PEDESTRIAN" 4 "MOTORCYCLE" 5 "BICYCLE" 6 "WIDE" 7 "UNCLASSIFIED";
VAL_ 870 ARC_OD_DynProp_Obj_43_RL 0 "STATIONAR" 1 "MOVIN" 2 "ONCOMING" 3 "STOPPE" 4 "CROSSING_LEFT2RIGH" 5 "CROSSING_RIGHT2LEF" 6 "RESERVE" 7 "RESERVED";
VAL_ 870 ARC_OD_MaintenanceState_Obj_0104 0 "INVALID" 1 "NEW" 2 "MEASURED" 3 "PREDICTED";
VAL_ 871 ARC_OD_Classification_Obj_44_RL 0 "POINT" 1 "CAR" 2 "TRUCK" 3 "PEDESTRIAN" 4 "MOTORCYCLE" 5 "BICYCLE" 6 "WIDE" 7 "UNCLASSIFIED";
VAL_ 871 ARC_OD_DynProp_Obj_44_RL 0 "MOVING" 1 "STATIONARY" 2 "ONCOMING" 3 "CROSSING_LEFT2RIGHT" 4 "CROSSING_RIGHT2LEFT" 5 "UNKNOWN" 6 "STOPPED" 7 "RESERVED";
VAL_ 871 ARC_OD_MaintenanceState_Obj_0105 0 "INVALID" 1 "NEW" 2 "MEASURED" 3 "PREDICTED";
VAL_ 871 ARC_OD_Classification_Obj_45_RL 0 "POINT" 1 "CAR" 2 "TRUCK" 3 "PEDESTRIAN" 4 "MOTORCYCLE" 5 "BICYCLE" 6 "WIDE" 7 "UNCLASSIFIED";
VAL_ 871 ARC_OD_DynProp_Obj_45_RL 0 "STATIONAR" 1 "MOVIN" 2 "ONCOMING" 3 "STOPPE" 4 "CROSSING_LEFT2RIGH" 5 "CROSSING_RIGHT2LEF" 6 "RESERVE" 7 "RESERVED";
VAL_ 871 ARC_OD_MaintenanceState_Obj_0106 0 "INVALID" 1 "NEW" 2 "MEASURED" 3 "PREDICTED";
VAL_ 872 ARC_OD_Classification_Obj_46_RL 0 "POINT" 1 "CAR" 2 "TRUCK" 3 "PEDESTRIAN" 4 "MOTORCYCLE" 5 "BICYCLE" 6 "WIDE" 7 "UNCLASSIFIED";
VAL_ 872 ARC_OD_DynProp_Obj_46_RL 0 "MOVING" 1 "STATIONARY" 2 "ONCOMING" 3 "CROSSING_LEFT2RIGHT" 4 "CROSSING_RIGHT2LEFT" 5 "UNKNOWN" 6 "STOPPED" 7 "RESERVED";
VAL_ 872 ARC_OD_MaintenanceState_Obj_0107 0 "INVALID" 1 "NEW" 2 "MEASURED" 3 "PREDICTED";
VAL_ 872 ARC_OD_Classification_Obj_47_RL 0 "POINT" 1 "CAR" 2 "TRUCK" 3 "PEDESTRIAN" 4 "MOTORCYCLE" 5 "BICYCLE" 6 "WIDE" 7 "UNCLASSIFIED";
VAL_ 872 ARC_OD_DynProp_Obj_47_RL 0 "STATIONAR" 1 "MOVIN" 2 "ONCOMING" 3 "STOPPE" 4 "CROSSING_LEFT2RIGH" 5 "CROSSING_RIGHT2LEF" 6 "RESERVE" 7 "RESERVED";
VAL_ 872 ARC_OD_MaintenanceState_Obj_0108 0 "INVALID" 1 "NEW" 2 "MEASURED" 3 "PREDICTED";
VAL_ 873 ARC_OD_Classification_Obj_48_RL 0 "POINT" 1 "CAR" 2 "TRUCK" 3 "PEDESTRIAN" 4 "MOTORCYCLE" 5 "BICYCLE" 6 "WIDE" 7 "UNCLASSIFIED";
VAL_ 873 ARC_OD_DynProp_Obj_48_RL 0 "MOVING" 1 "STATIONARY" 2 "ONCOMING" 3 "CROSSING_LEFT2RIGHT" 4 "CROSSING_RIGHT2LEFT" 5 "UNKNOWN" 6 "STOPPED" 7 "RESERVED";
VAL_ 873 ARC_OD_MaintenanceState_Obj_0109 0 "INVALID" 1 "NEW" 2 "MEASURED" 3 "PREDICTED";
VAL_ 873 ARC_OD_Classification_Obj_49_RL 0 "POINT" 1 "CAR" 2 "TRUCK" 3 "PEDESTRIAN" 4 "MOTORCYCLE" 5 "BICYCLE" 6 "WIDE" 7 "UNCLASSIFIED";
VAL_ 873 ARC_OD_DynProp_Obj_49_RL 0 "STATIONAR" 1 "MOVIN" 2 "ONCOMING" 3 "STOPPE" 4 "CROSSING_LEFT2RIGH" 5 "CROSSING_RIGHT2LEF" 6 "RESERVE" 7 "RESERVED";
VAL_ 873 ARC_OD_MaintenanceState_Obj_0110 0 "INVALID" 1 "NEW" 2 "MEASURED" 3 "PREDICTED";
VAL_ 874 ARC_OD_Classification_Obj_50_RL 0 "POINT" 1 "CAR" 2 "TRUCK" 3 "PEDESTRIAN" 4 "MOTORCYCLE" 5 "BICYCLE" 6 "WIDE" 7 "UNCLASSIFIED";
VAL_ 874 ARC_OD_DynProp_Obj_50_RL 0 "MOVING" 1 "STATIONARY" 2 "ONCOMING" 3 "CROSSING_LEFT2RIGHT" 4 "CROSSING_RIGHT2LEFT" 5 "UNKNOWN" 6 "STOPPED" 7 "RESERVED";
VAL_ 874 ARC_OD_MaintenanceState_Obj_0111 0 "INVALID" 1 "NEW" 2 "MEASURED" 3 "PREDICTED";
VAL_ 874 ARC_OD_Classification_Obj_51_RL 0 "POINT" 1 "CAR" 2 "TRUCK" 3 "PEDESTRIAN" 4 "MOTORCYCLE" 5 "BICYCLE" 6 "WIDE" 7 "UNCLASSIFIED";
VAL_ 874 ARC_OD_DynProp_Obj_51_RL 0 "STATIONAR" 1 "MOVIN" 2 "ONCOMING" 3 "STOPPE" 4 "CROSSING_LEFT2RIGH" 5 "CROSSING_RIGHT2LEF" 6 "RESERVE" 7 "RESERVED";
VAL_ 874 ARC_OD_MaintenanceState_Obj_0112 0 "INVALID" 1 "NEW" 2 "MEASURED" 3 "PREDICTED";
VAL_ 875 ARC_OD_Classification_Obj_52_RL 0 "POINT" 1 "CAR" 2 "TRUCK" 3 "PEDESTRIAN" 4 "MOTORCYCLE" 5 "BICYCLE" 6 "WIDE" 7 "UNCLASSIFIED";
VAL_ 875 ARC_OD_DynProp_Obj_52_RL 0 "MOVING" 1 "STATIONARY" 2 "ONCOMING" 3 "CROSSING_LEFT2RIGHT" 4 "CROSSING_RIGHT2LEFT" 5 "UNKNOWN" 6 "STOPPED" 7 "RESERVED";
VAL_ 875 ARC_OD_MaintenanceState_Obj_0113 0 "INVALID" 1 "NEW" 2 "MEASURED" 3 "PREDICTED";
VAL_ 875 ARC_OD_Classification_Obj_53_RL 0 "POINT" 1 "CAR" 2 "TRUCK" 3 "PEDESTRIAN" 4 "MOTORCYCLE" 5 "BICYCLE" 6 "WIDE" 7 "UNCLASSIFIED";
VAL_ 875 ARC_OD_DynProp_Obj_53_RL 0 "STATIONAR" 1 "MOVIN" 2 "ONCOMING" 3 "STOPPE" 4 "CROSSING_LEFT2RIGH" 5 "CROSSING_RIGHT2LEF" 6 "RESERVE" 7 "RESERVED";
VAL_ 875 ARC_OD_MaintenanceState_Obj_0114 0 "INVALID" 1 "NEW" 2 "MEASURED" 3 "PREDICTED";
VAL_ 876 ARC_OD_Classification_Obj_54_RL 0 "POINT" 1 "CAR" 2 "TRUCK" 3 "PEDESTRIAN" 4 "MOTORCYCLE" 5 "BICYCLE" 6 "WIDE" 7 "UNCLASSIFIED";
VAL_ 876 ARC_OD_DynProp_Obj_54_RL 0 "MOVING" 1 "STATIONARY" 2 "ONCOMING" 3 "CROSSING_LEFT2RIGHT" 4 "CROSSING_RIGHT2LEFT" 5 "UNKNOWN" 6 "STOPPED" 7 "RESERVED";
VAL_ 876 ARC_OD_MaintenanceState_Obj_0115 0 "INVALID" 1 "NEW" 2 "MEASURED" 3 "PREDICTED";
VAL_ 876 ARC_OD_Classification_Obj_55_RL 0 "POINT" 1 "CAR" 2 "TRUCK" 3 "PEDESTRIAN" 4 "MOTORCYCLE" 5 "BICYCLE" 6 "WIDE" 7 "UNCLASSIFIED";
VAL_ 876 ARC_OD_DynProp_Obj_55_RL 0 "STATIONAR" 1 "MOVIN" 2 "ONCOMING" 3 "STOPPE" 4 "CROSSING_LEFT2RIGH" 5 "CROSSING_RIGHT2LEF" 6 "RESERVE" 7 "RESERVED";
VAL_ 876 ARC_OD_MaintenanceState_Obj_0116 0 "INVALID" 1 "NEW" 2 "MEASURED" 3 "PREDICTED";
VAL_ 877 ARC_OD_Classification_Obj_56_RL 0 "POINT" 1 "CAR" 2 "TRUCK" 3 "PEDESTRIAN" 4 "MOTORCYCLE" 5 "BICYCLE" 6 "WIDE" 7 "UNCLASSIFIED";
VAL_ 877 ARC_OD_DynProp_Obj_56_RL 0 "MOVING" 1 "STATIONARY" 2 "ONCOMING" 3 "CROSSING_LEFT2RIGHT" 4 "CROSSING_RIGHT2LEFT" 5 "UNKNOWN" 6 "STOPPED" 7 "RESERVED";
VAL_ 877 ARC_OD_MaintenanceState_Obj_0117 0 "INVALID" 1 "NEW" 2 "MEASURED" 3 "PREDICTED";
VAL_ 877 ARC_OD_Classification_Obj_57_RL 0 "POINT" 1 "CAR" 2 "TRUCK" 3 "PEDESTRIAN" 4 "MOTORCYCLE" 5 "BICYCLE" 6 "WIDE" 7 "UNCLASSIFIED";
VAL_ 877 ARC_OD_DynProp_Obj_57_RL 0 "STATIONAR" 1 "MOVIN" 2 "ONCOMING" 3 "STOPPE" 4 "CROSSING_LEFT2RIGH" 5 "CROSSING_RIGHT2LEF" 6 "RESERVE" 7 "RESERVED";
VAL_ 877 ARC_OD_MaintenanceState_Obj_0118 0 "INVALID" 1 "NEW" 2 "MEASURED" 3 "PREDICTED";
VAL_ 878 ARC_OD_Classification_Obj_58_RL 0 "POINT" 1 "CAR" 2 "TRUCK" 3 "PEDESTRIAN" 4 "MOTORCYCLE" 5 "BICYCLE" 6 "WIDE" 7 "UNCLASSIFIED";
VAL_ 878 ARC_OD_DynProp_Obj_58_RL 0 "MOVING" 1 "STATIONARY" 2 "ONCOMING" 3 "CROSSING_LEFT2RIGHT" 4 "CROSSING_RIGHT2LEFT" 5 "UNKNOWN" 6 "STOPPED" 7 "RESERVED";
VAL_ 878 ARC_OD_MaintenanceState_Obj_0119 0 "INVALID" 1 "NEW" 2 "MEASURED" 3 "PREDICTED";
VAL_ 878 ARC_OD_Classification_Obj_59_RL 0 "POINT" 1 "CAR" 2 "TRUCK" 3 "PEDESTRIAN" 4 "MOTORCYCLE" 5 "BICYCLE" 6 "WIDE" 7 "UNCLASSIFIED";
VAL_ 878 ARC_OD_DynProp_Obj_59_RL 0 "STATIONAR" 1 "MOVIN" 2 "ONCOMING" 3 "STOPPE" 4 "CROSSING_LEFT2RIGH" 5 "CROSSING_RIGHT2LEF" 6 "RESERVE" 7 "RESERVED";
VAL_ 878 ARC_OD_MaintenanceState_Obj_0120 0 "INVALID" 1 "NEW" 2 "MEASURED" 3 "PREDICTED";
VAL_ 266 ESC_RLWhlSpdV 0 "Valid " 1 "Invalid";
VAL_ 277 EPS_StrgWhlAnglSenCalSts 0 "unknow" 1 "Estimated" 2 "Calibrated" 3 "unknow";
VAL_ 805 ESC_VehSpdV 0 "Valid" 1 "Invalid ";
VAL_ 805 ESC_VDCCtrlActv 0 "VDCInactive " 1 "VDCActive ";
VAL_ 834 ICM_VehSpdDispV 0 "Invalid" 1 "Valid";
VAL_ 834 ICM_TotOdoV 0 "Invalid" 1 "Valid";
VAL_ 267 ESC_EBDActv 0 "Notactive" 1 "Active";
VAL_ 267 ESC_TCSActv 0 "Inactive" 1 "Active";
VAL_ 267 ESC_ABSActv 0 "Not active" 1 "Active";
VAL_ 267 ESC_ESCFld 0 "ESC Normal" 1 "ESC Failed";
VAL_ 267 ESC_CDPActv 0 "Not Active" 1 "Active";
VAL_ 267 ESC_HDCSts 0 "OFF" 1 "On not active braking" 2 "On active braking" 3 "Reserved";
VAL_ 267 ESC_Off 0 "Off" 1 "On";
VAL_ 267 ESC_ABAAvlbl 0 "Not available" 1 "Available";
VAL_ 267 ESC_ABAActv 0 "Not active" 1 "Active";
VAL_ 269 ESC_VehStdslSts 0 "Not Standstill" 1 "Standstill";
VAL_ 269 ESC_VehStdslStsV 0 "Invalid" 1 "Valid";
VAL_ 181 EHB_BrkPedlAppld 0 "brake pedal not applied" 1 "brake pedal applied";
VAL_ 181 EHB_BrkPedlAppldSts 0 "Init" 1 "Normal" 2 "Fault" 3 "Reserved";
VAL_ 181 EHB_CtrlrFltSts 0 "Normal" 1 "Fault";
